VERSION "HNNBNNNYNNNNNNNNNNNNNNNNNNNNNNNNNNNNNNNNNN/4/%%%/4/'%**4NNN///"

NS_ :

BS_:

BU_: BAP_Tester Gateway_Max Getriebe_DQ Motor_konv Parksperre Schaltbetaetigung

BO_ 267 Motor_51_Auth: 48 Motor_konv
 SG_ Motor_51_CRC : 0|8@1+ (1,0) [0|255] ""  Gateway_Max
 SG_ Motor_51_BZ : 8|4@1+ (1,0) [0|15] ""  Gateway_Max
 SG_ MO_Fahrpedalrohwert_01 : 12|8@1+ (0.4,0) [0.0|101.6] "Unit_PerCent"  Gateway_Max,Getriebe_DQ
 SG_ MO_QBit_Fahrpedalwerte_01 : 20|1@1+ (1.0,0.0) [0.0|1] ""  Gateway_Max,Getriebe_DQ
 SG_ MO_Fahrpedalgradient : 21|8@1+ (25,0) [0|6350] "Unit_PerCentPerSecon"  Gateway_Max
 SG_ MO_Sig_Fahrpedalgradient : 29|1@1+ (1.0,0.0) [0.0|1] ""  Gateway_Max
 SG_ MO_rel_Saugrohrdruck : 30|6@1+ (18,0) [0|1116] "Unit_MilliBar"  Gateway_Max
 SG_ MO_rel_Saugrohrdruck_gem_err : 36|1@1+ (1.0,0.0) [0.0|1] ""  Gateway_Max
 SG_ MO_Moment_im_Leerlauf : 37|1@1+ (1.0,0.0) [0.0|1] ""  Gateway_Max,Getriebe_DQ
 SG_ MO_Schubabschaltung : 38|1@1+ (1.0,0.0) [0.0|1] ""  Gateway_Max,Getriebe_DQ
 SG_ MO_StartStopp_StoppVorbereitung : 39|1@1+ (1.0,0.0) [0.0|1] ""  Gateway_Max,Getriebe_DQ
 SG_ MO_Solldrehz_Leerlauf : 40|8@1+ (10,0) [0|2540] "Unit_MinutInver"  Gateway_Max,Getriebe_DQ
 SG_ MO_Entkopplung_Sollschlupf : 48|7@1+ (20,0) [0|2480] "Unit_MinutInver"  Gateway_Max
 SG_ MO_temporaere_Fahrerabwesenheit : 55|1@1+ (1.0,0.0) [0.0|1] ""  Gateway_Max
 SG_ TSK_a_Soll_gradientenbegrenzt : 57|7@1+ (0.1,-7.2) [-7.2|5.4] "Unit_MeterPerSeconSquar"  Gateway_Max
 SG_ TSK_Radbremsmom : 76|12@1+ (8,0) [0|32760] "Unit_NewtoMeter"  Gateway_Max,Getriebe_DQ
 SG_ TSK_Status : 88|3@1+ (1.0,0.0) [0.0|7] ""  Gateway_Max,Getriebe_DQ
 SG_ TSK_v_Begrenzung_aktiv : 91|1@1+ (1.0,0.0) [0.0|1] ""  Gateway_Max,Getriebe_DQ
 SG_ TSK_Standby_Anf_ESP : 92|1@1+ (1.0,0.0) [0.0|1] ""  Gateway_Max
 SG_ TSK_Freig_Verzoeg_Anf : 94|1@1+ (1.0,0.0) [0.0|1] ""  Gateway_Max,Getriebe_DQ
 SG_ TSK_Limiter_ausgewaehlt : 95|1@1+ (1.0,0.0) [0.0|1] ""  Gateway_Max
 SG_ TSK_Hauptschalter_GRA_ACC : 106|2@1+ (1.0,0.0) [0.0|3] ""  Gateway_Max
 SG_ TSK_SRBM_Anf_ASIL : 108|3@1+ (1.0,0.0) [0.0|7] ""  Gateway_Max
 SG_ TSK_ax_Getriebe_02 : 112|9@1+ (0.024,-2.016) [-2.016|10.224] "Unit_MeterPerSeconSquar"  Gateway_Max,Getriebe_DQ
 SG_ TSK_Zwangszusch_ESP : 121|1@1+ (1.0,0.0) [0.0|1] ""  Gateway_Max
 SG_ TSK_zul_Regelabw : 122|6@1+ (0.024,0) [0.000|1.512] "Unit_MeterPerSeconSquar"  Gateway_Max
 SG_ TSK_Radsollmoment : 128|16@1+ (0.5,-16383) [-16383.0|16383.5] "Unit_NewtoMeter"  Gateway_Max
 SG_ TSK_Kategorie_Verzoegerungsfkt : 144|2@1+ (1.0,0.0) [0.0|3] ""  Gateway_Max
 SG_ TSK_Notstopp_Anf : 233|2@1+ (1.0,0.0) [0.0|3] ""  Gateway_Max
 SG_ MO_Status_MinDrzEingriff : 235|3@1+ (1.0,0.0) [0.0|7] ""  Gateway_Max
 SG_ MO_Status_MaxDrzEingriff : 238|3@1+ (1.0,0.0) [0.0|7] ""  Gateway_Max
 SG_ MO_Status_MinDrzEingriff_sek : 241|3@1+ (1.0,0.0) [0.0|7] ""  Gateway_Max
 SG_ MO_Status_MaxDrzEingriff_sek : 244|3@1+ (1.0,0.0) [0.0|7] ""  Gateway_Max
 SG_ TSK_SRBM_max_Gradient : 248|7@1+ (50,0) [0|6250] "Unit_NewtoMeterPerSecon"  Gateway_Max
 SG_ SOK_Motor_51_Signatur : 352|32@1+ (1,0) [0|4294967295] ""  Gateway_Max

BO_ 330 Motor_52: 32 Motor_konv
 SG_ MO_Hochschaltdrehz : 21|12@1+ (3,0) [3|12282] "Unit_MinutInver"  Gateway_Max
 SG_ MO_Anzeige_Verbr_Einheit : 33|2@1+ (1.0,0.0) [0.0|3] ""  Gateway_Max
 SG_ MO_Schaltblitz_Anz : 35|7@1+ (1,0) [0|100] "Unit_PerCent"  Gateway_Max
 SG_ MO_Anzeige_Drehmoment : 42|11@1+ (1,0) [0|2045] "Unit_NewtoMeter"  Gateway_Max
 SG_ MO_Anzeige_Leistung : 53|11@1+ (0.6,0) [0.0|1227.0] "Unit_KiloWatt"  Gateway_Max
 SG_ MO_rel_Ladedruck : 64|8@1+ (0.4,0) [0.0|100.0] "Unit_PerCent"  Gateway_Max
 SG_ MO_Istgang : 72|4@1+ (1.0,0.0) [0.0|15] ""  Gateway_Max
 SG_ MO_Sollgang : 76|4@1+ (1.0,0.0) [0.0|15] ""  Gateway_Max
 SG_ MO_Oeldruck : 80|8@1+ (0.04,0) [0.00|10.00] "Unit_Bar"  Gateway_Max
 SG_ MO_Anzeigedrehz : 88|12@1+ (3,0) [0|12282] "Unit_MinutInver"  Gateway_Max
 SG_ MO_Effizienzmodus : 100|1@1+ (1.0,0.0) [0.0|1] ""  Gateway_Max,Getriebe_DQ
 SG_ MO_Fehler_Oeldrucksensor : 101|1@1+ (1.0,0.0) [0.0|1] ""  Gateway_Max
 SG_ MO_Schaltempf_verfbar : 102|1@1+ (1.0,0.0) [0.0|1] ""  Gateway_Max
 SG_ MO_Ladedruck : 103|9@1+ (0.01,0) [0.00|5.10] "Unit_Bar"  Gateway_Max
 SG_ MO_KVS : 112|15@1+ (1,0) [0|32767] "Unit_MicroLiter"  Gateway_Max
 SG_ MO_KVS_Ueberlauf : 127|1@1+ (1.0,0.0) [0.0|1] ""  Gateway_Max
 SG_ MO_ePowermeter : 128|8@1+ (0.4,-0.4) [0.0|100.8] "Unit_PerCent"  Gateway_Max
 SG_ MO_ePerformance : 136|8@1+ (0.4,-0.4) [0.0|100.8] "Unit_PerCent"  Gateway_Max
 SG_ MO_Zust_Antrieb : 144|4@1+ (1.0,0.0) [0.0|15] ""  Gateway_Max
 SG_ MO_Zust_Betriebsstrategie : 148|3@1+ (1.0,0.0) [0.0|7] ""  Gateway_Max
 SG_ Ladezustand_02 : 152|8@1+ (0.5,0) [0.0|100.0] "Unit_PerCent"  Gateway_Max
 SG_ Ladezustand_gering : 160|2@1+ (1.0,0.0) [0.0|3] ""  Gateway_Max
 SG_ Ladezustand_kritisch : 162|2@1+ (1.0,0.0) [0.0|3] ""  Gateway_Max
 SG_ MO_Powermeter_Elm_02 : 168|12@1+ (0.05,-102.4) [-100.00|100.00] "Unit_PerCent"  Gateway_Max
 SG_ MO_Powermeter : 180|12@1+ (1,0) [0|4092] ""  Gateway_Max
 SG_ MO_OnePedalDriving_Warnung : 192|2@1+ (1.0,0.0) [0.0|3] ""  Gateway_Max

BO_ 512 Motor_53: 32 Motor_konv
 SG_ TSK_Wunschgeschw : 12|10@1+ (0.32,0) [0.00|326.72] "Unit_KiloMeterPerHour"  Gateway_Max
 SG_ TSK_praediktiver_Hinweis : 22|3@1+ (1.0,0.0) [0.0|7] ""  Gateway_Max
 SG_ TSK_naechstes_Event : 25|6@1+ (1.0,0.0) [0.0|63] ""  Gateway_Max
 SG_ TSK_Fahrzeugstatus_praed_Fkt : 31|3@1+ (1.0,0.0) [0.0|7] ""  Gateway_Max
 SG_ TSK_praediktiver_Automode : 34|1@1+ (1.0,0.0) [0.0|1] ""  Gateway_Max
 SG_ CE_StStrtDlyEmiSysPrep : 35|2@1+ (1.0,0.0) [0.0|3] ""  Gateway_Max
 SG_ CE_StLdRdcEmiSysPrep : 37|3@1+ (1.0,0.0) [0.0|7] ""  Gateway_Max,Getriebe_DQ
 SG_ TSK_Texte : 40|5@1+ (1.0,0.0) [0.0|31] ""  Gateway_Max
 SG_ TSK_Akustik : 45|3@1+ (1.0,0.0) [0.0|7] ""  Gateway_Max
 SG_ TSK_Texte_Primaeranz : 48|5@1+ (1.0,0.0) [0.0|31] ""  Gateway_Max
 SG_ TSK_Limiter_Fahrerinfo : 53|2@1+ (1.0,0.0) [0.0|3] ""  Gateway_Max
 SG_ TSK_Limiter_Anzeige : 55|1@1+ (1.0,0.0) [0.0|1] ""  Gateway_Max
 SG_ TSK_Fahrzeugstatus_GRA : 56|1@1+ (1.0,0.0) [0.0|1] ""  Gateway_Max
 SG_ TSK_Fahrzeugstatus_Limiter : 57|1@1+ (1.0,0.0) [0.0|1] ""  Gateway_Max
 SG_ MO_Motorlaufwarnung : 58|1@1+ (1.0,0.0) [0.0|1] ""  Gateway_Max
 SG_ TSK_naechstes_Event_Einheit : 60|1@1+ (1.0,0.0) [0.0|1] ""  Gateway_Max
 SG_ TSK_Status_Anzeige : 61|3@1+ (1.0,0.0) [0.0|7] ""  Gateway_Max
 SG_ MO_Sperrung_FahrPr_BZS : 64|8@1+ (1.0,0.0) [0.0|255] ""  Gateway_Max
 SG_ MO_Rampenzeit_Generator_Anf : 72|4@1+ (1.0,0.0) [0.0|15] ""  Gateway_Max
 SG_ MO_Prio_MAX_Wunschdrehzahl : 76|1@1+ (1.0,0.0) [0.0|1] ""  Gateway_Max,Getriebe_DQ
 SG_ MO_Prio_MIN_Wunschdrehzahl : 77|1@1+ (1.0,0.0) [0.0|1] ""  Gateway_Max,Getriebe_DQ
 SG_ MO_Luftpfad_aktiv : 78|1@1+ (1.0,0.0) [0.0|1] ""  Gateway_Max
 SG_ MO_v_Begrenz_Aktivierbar : 79|1@1+ (1.0,0.0) [0.0|1] ""  Gateway_Max
 SG_ MO_Drehzahlbeeinflussung : 80|8@1+ (0.39,0) [0.00|99.45] "Unit_PerCent"  Gateway_Max
 SG_ MO_MIN_Wunschdrehzahl : 88|8@1+ (25,0) [0|6350] "Unit_MinutInver"  Gateway_Max,Getriebe_DQ
 SG_ MO_MAX_Wunschdrehzahl : 96|9@1+ (25,0) [0|12750] "Unit_MinutInver"  Gateway_Max,Getriebe_DQ
 SG_ MO_Charisma_FahrPr : 105|4@1+ (1.0,0.0) [0.0|15] ""  Gateway_Max
 SG_ MO_Charisma_Status : 109|2@1+ (1.0,0.0) [0.0|3] ""  Gateway_Max
 SG_ MO_StSt_Charisma_FahrPr : 111|4@1+ (1.0,0.0) [0.0|15] ""  Gateway_Max
 SG_ MO_StSt_Charisma_Status : 115|2@1+ (1.0,0.0) [0.0|3] ""  Gateway_Max
 SG_ MO_BZS_Charisma_FahrPr : 117|4@1+ (1.0,0.0) [0.0|15] ""  Gateway_Max
 SG_ MO_BZS_Charisma_Status : 121|2@1+ (1.0,0.0) [0.0|3] ""  Gateway_Max
 SG_ MO_NGS_Position : 123|1@1+ (1.0,0.0) [0.0|1] ""  Gateway_Max
 SG_ MO_NGS_Status : 124|2@1+ (1.0,0.0) [0.0|3] ""  Gateway_Max
 SG_ MO_v_Begrenzung_Niveau : 126|2@1+ (1.0,0.0) [0.0|3] ""  Gateway_Max
 SG_ MO_Anzeige_Rekuperation : 128|8@1+ (0.5,-0.5) [0.0|100.0] "Unit_PerCent"  Gateway_Max
 SG_ PEA_Fortschrittsanzeige : 136|7@1+ (1,0) [0|100] "Unit_PerCent"  Gateway_Max
 SG_ MO_Anzeige_Fahrbereitschaft : 143|1@1+ (1.0,0.0) [0.0|1] ""  Gateway_Max
 SG_ MO_Boost_verfuegbar : 144|8@1+ (0.4,-0.4) [0.0|100.4] "Unit_PerCent"  Gateway_Max
 SG_ MO_Overboost : 152|1@1+ (1.0,0.0) [0.0|1] ""  Gateway_Max
 SG_ MO_Boost_aktiv : 153|1@1+ (1.0,0.0) [0.0|1] ""  Gateway_Max
 SG_ MO_Anzeige_Betriebsmodus : 154|4@1+ (1.0,0.0) [0.0|15] ""  Gateway_Max
 SG_ PEA_Hinweis : 158|2@1+ (1.0,0.0) [0.0|3] ""  Gateway_Max
 SG_ PEA_Ereignisanzeige : 160|5@1+ (1.0,0.0) [0.0|31] ""  Gateway_Max
 SG_ PEA_Ereignisanzeige_temporaer : 165|1@1+ (1.0,0.0) [0.0|1] ""  Gateway_Max
 SG_ PEA_Abschalttexte : 166|2@1+ (1.0,0.0) [0.0|3] ""  Gateway_Max
 SG_ PEA_Zielgeschw_Einheit : 168|1@1+ (1.0,0.0) [0.0|1] ""  Gateway_Max
 SG_ PEA_Zielgeschw : 169|5@1+ (1.0,0.0) [0.0|31] ""  Gateway_Max
 SG_ MO_Antriebsstrang_Warnung_HS : 174|2@1+ (1.0,0.0) [0.0|3] ""  Gateway_Max
 SG_ MO_Anzeige_Verbrauch_oE : 176|16@1+ (0.005,0) [0.000|327.675] "Unit_None"  Gateway_Max
 SG_ MO_Text_Aktivierung_Antrieb : 192|4@1+ (1.0,0.0) [0.0|15] ""  Gateway_Max
 SG_ ISA_Tempolimit_Regelung : 196|6@1+ (1.0,0.0) [0.0|63] ""  Gateway_Max
 SG_ PEA_Fahrerinfo : 202|4@1+ (1.0,0.0) [0.0|15] ""  Gateway_Max
 SG_ CE_CtrPrpPrep : 206|3@1+ (1.0,0.0) [0.0|7] ""  Gateway_Max
 SG_ CE_PrctPrpPrep : 209|7@1+ (1,0) [0|100] "Unit_PerCent"  Gateway_Max
 SG_ MO_Kuehlmitttel_Sensor_AGB2 : 216|1@1+ (1.0,0.0) [0.0|1] ""  Gateway_Max
 SG_ CE_FlgEmiColdLmp : 217|1@1+ (1.0,0.0) [0.0|1] ""  Gateway_Max
 SG_ CE_FlgEmiColdTxt : 218|1@1+ (1.0,0.0) [0.0|1] ""  Gateway_Max
 SG_ CE_FlgHybModAdvi : 219|1@1+ (1.0,0.0) [0.0|1] ""  Gateway_Max
 SG_ CE_FlgPTLimPrfTxt : 220|1@1+ (1.0,0.0) [0.0|1] ""  Gateway_Max
 SG_ TSK_praed_Wunschgeschw : 246|10@1+ (0.32,0) [0.00|326.72] "Unit_KiloMeterPerHour"  Gateway_Max

BO_ 332 Motor_54: 32 Motor_konv
 SG_ Motor_54_CRC : 0|8@1+ (1,0) [0|255] ""  Gateway_Max
 SG_ Motor_54_BZ : 8|4@1+ (1,0) [0|15] ""  Gateway_Max
 SG_ MO_Anforderung_HMS : 12|3@1+ (1.0,0.0) [0.0|7] ""  Gateway_Max
 SG_ FoD_DTC_TSK_GRA : 15|1@1+ (1.0,0.0) [0.0|1] ""  Gateway_Max
 SG_ TSK_vMax_aktuell : 16|8@1+ (1,0) [0|253] "Unit_KiloMeterPerHour"  Gateway_Max
 SG_ ISA_Status : 24|3@1+ (1.0,0.0) [0.0|7] ""  Gateway_Max
 SG_ ISA_Regelung_aktiv : 27|1@1+ (1.0,0.0) [0.0|1] ""  Gateway_Max
 SG_ ISA_Tempolimitwarnung : 28|1@1+ (1.0,0.0) [0.0|1] ""  Gateway_Max
 SG_ MO_Red_El_Fahrleistung : 29|3@1+ (1.0,0.0) [0.0|7] ""  Gateway_Max
 SG_ TSK_Status_EA : 32|3@1+ (1.0,0.0) [0.0|7] ""  Gateway_Max
 SG_ FoD_DTC_TSK_ACC : 35|1@1+ (1.0,0.0) [0.0|1] ""  Gateway_Max
 SG_ TSK_ACC_FoD_Status : 36|2@1+ (1.0,0.0) [0.0|3] ""  Gateway_Max
 SG_ TSK_GRA_FoD_Status : 38|2@1+ (1.0,0.0) [0.0|3] ""  Gateway_Max
 SG_ TSK_vMax_Fahrerassistenz : 40|9@1+ (1,0) [0|510] ""  Gateway_Max
 SG_ TSK_Einheit_vMax_Fahrerassistenz : 49|1@1+ (1.0,0.0) [0.0|1] ""  Gateway_Max
 SG_ TSK_Status_PLA : 50|3@1+ (1.0,0.0) [0.0|7] ""  Gateway_Max
 SG_ TSK_aktives_System : 53|3@1+ (1.0,0.0) [0.0|7] ""  Gateway_Max
 SG_ TSK_erhoehter_Fahrwiderstand : 56|1@1+ (1.0,0.0) [0.0|1] ""  Gateway_Max
 SG_ TSK_Anf_Antriebsmoment : 57|1@1+ (1.0,0.0) [0.0|1] ""  Gateway_Max
 SG_ TSK_Status_ARA : 58|3@1+ (1.0,0.0) [0.0|7] ""  Gateway_Max
 SG_ TSK_Status_IPA : 61|3@1+ (1.0,0.0) [0.0|7] ""  Gateway_Max,Getriebe_DQ
 SG_ TSK_aktives_System_02 : 64|4@1+ (1.0,0.0) [0.0|15] ""  Gateway_Max,Getriebe_DQ
 SG_ TSK_Status_RHP : 68|3@1+ (1.0,0.0) [0.0|7] ""  Gateway_Max,Getriebe_DQ
 SG_ MO_Kuppl_betaetigt : 72|1@1+ (1.0,0.0) [0.0|1] ""  Gateway_Max
 SG_ MO_QBit_Kuppl_betaetigt : 73|1@1+ (1.0,0.0) [0.0|1] ""  Gateway_Max
 SG_ MO_Klima_Regelmodus : 74|2@1+ (1.0,0.0) [0.0|3] ""  Gateway_Max
 SG_ MO_Fahrbereitschaft : 76|2@1+ (1.0,0.0) [0.0|3] ""  Gateway_Max,Getriebe_DQ
 SG_ MO_Freilauf_Info : 78|2@1+ (1.0,0.0) [0.0|3] ""  Gateway_Max,Getriebe_DQ
 SG_ CE_FlgLnchCtlPreCnd : 80|1@1+ (1.0,0.0) [0.0|1] ""  Gateway_Max
 SG_ MO_Krit_Heckobjekt : 81|3@1+ (1.0,0.0) [0.0|7] ""  Gateway_Max
 SG_ MO_NGS_Gangpos : 84|3@1+ (1.0,0.0) [0.0|7] ""  Gateway_Max
 SG_ MO_Freilauf_Status : 87|3@1+ (1.0,0.0) [0.0|7] ""  Gateway_Max
 SG_ MO_EBoost_verf_praed : 90|2@1+ (1.0,0.0) [0.0|3] ""  Gateway_Max
 SG_ MO_Heckspoiler_Anf : 92|1@1+ (1.0,0.0) [0.0|1] ""  Gateway_Max
 SG_ MO_eLaunch_verf : 93|2@1+ (1.0,0.0) [0.0|3] ""  Gateway_Max
 SG_ MO_Positionierung_aktiv : 95|1@1+ (1.0,0.0) [0.0|1] ""  Gateway_Max
 SG_ MO_Veto_Launchcontrol : 96|1@1+ (1.0,0.0) [0.0|1] ""  Gateway_Max,Getriebe_DQ
 SG_ MO_Startwunsch : 100|1@1+ (1.0,0.0) [0.0|1] ""  Gateway_Max,Getriebe_DQ
 SG_ MO_LaunchControl : 101|1@1+ (1.0,0.0) [0.0|1] ""  Gateway_Max
 SG_ MO_UBE_Hybrid_Reserve : 102|10@1+ (5,0) [0|5110] "Unit_WattHour"  Gateway_Max
 SG_ OBDProtocol_req : 112|8@1+ (1.0,0.0) [0.0|255] ""  Gateway_Max,Getriebe_DQ
 SG_ OBD_Calc_Load_Val : 128|8@1+ (0.39215686274509803,0) [0E-17|99.99999999999999765] "Unit_PerCent"  Gateway_Max,Getriebe_DQ
 SG_ OBD_Eng_Cool_Temp : 136|8@1+ (1,-40) [-40|215] "Unit_DegreCelsi"  Gateway_Max,Getriebe_DQ
 SG_ OBD_Abs_Throttle_Pos : 144|8@1+ (0.39215686274509803,0) [0E-17|99.99999999999999765] "Unit_PerCent"  Gateway_Max,Getriebe_DQ
 SG_ OBD_Abs_Load_Val : 152|16@1+ (0.39215686274509803,0) [0E-17|25699.99999999999939605] "Unit_PerCent"  Gateway_Max,Getriebe_DQ
 SG_ OBD_Abs_Pedal_Pos : 168|8@1+ (0.39215686274509803,0) [0E-17|99.99999999999999765] "Unit_PerCent"  Gateway_Max,Getriebe_DQ
 SG_ MO_Servicemodus : 176|4@1+ (1.0,0.0) [0.0|15] ""  Gateway_Max,Getriebe_DQ
 SG_ OBD_ClearMem_Inhibit : 183|1@1+ (1.0,0.0) [0.0|1] ""  Gateway_Max,Getriebe_DQ
 SG_ OBD_Sperrung_Kaltstart_Denom : 184|1@1+ (1.0,0.0) [0.0|1] ""  Gateway_Max
 SG_ MO_QBit_Aussen_Temp : 185|1@1+ (1.0,0.0) [0.0|1] ""  Gateway_Max
 SG_ OBD_Sperrung_IUMPR : 186|1@1+ (1.0,0.0) [0.0|1] ""  Gateway_Max,Getriebe_DQ
 SG_ OBD_Kaltstart_Denominator : 187|1@1+ (1.0,0.0) [0.0|1] ""  Gateway_Max
 SG_ OBD_Minimum_Trip : 188|1@1+ (1.0,0.0) [0.0|1] ""  Gateway_Max,Getriebe_DQ
 SG_ OBD_Driving_Cycle : 189|1@1+ (1.0,0.0) [0.0|1] ""  Gateway_Max,Getriebe_DQ
 SG_ OBD_Warm_Up_Cycle : 190|1@1+ (1.0,0.0) [0.0|1] ""  Gateway_Max,Getriebe_DQ
 SG_ OBD_Normed_Trip : 191|1@1+ (1.0,0.0) [0.0|1] ""  Gateway_Max,Getriebe_DQ
 SG_ MO_EMG_Min_Leistung : 192|11@1+ (100,-102200) [-102200|102300] "Unit_Watt"  Gateway_Max
 SG_ MO_EMG_Max_Leistung : 203|11@1+ (100,-102200) [-102200|102300] "Unit_Watt"  Gateway_Max
 SG_ MO_MVEM_MinLeistung_MVVerbrauch : 214|10@1+ (50,-10500) [-10500|40500] "Unit_Watt"  Gateway_Max
 SG_ MO_MVEM_MaxLeistung_MVVerbrauch : 224|10@1+ (50,-10500) [-10500|40500] "Unit_Watt"  Gateway_Max
 SG_ MO_UBE_Reserve : 238|10@1+ (5,0) [0|5110] "Unit_WattHour"  Gateway_Max
 SG_ OBD_Aussen_Temp_gef : 248|8@1+ (1,-40) [-40|213] "Unit_DegreCelsi"  Gateway_Max

BO_ 553 Motor_54_SOK_Signatur: 4 Motor_konv
 SG_ SOK_Motor_54_Signatur : 0|32@1+ (1,0) [0|4294967295] ""  Gateway_Max,Getriebe_DQ

BO_ 246 Motor_55_Auth: 48 Motor_konv
 SG_ Motor_55_CRC : 0|8@1+ (1,0) [0|255] ""  Gateway_Max
 SG_ Motor_55_BZ : 8|4@1+ (1,0) [0|15] ""  Gateway_Max
 SG_ TS_Faktor_Radmomente : 12|2@1+ (1.0,0.0) [0.0|3] ""  Gateway_Max,Getriebe_DQ
 SG_ TS_Status_MomRad_Ist : 14|2@1+ (1.0,0.0) [0.0|3] ""  Gateway_Max
 SG_ TS_MomRad_verfuegb_maxReku_Summe : 16|12@1+ (3,-12279) [-12279|0] ""  Gateway_Max
 SG_ TS_MomRad_Ist : 28|13@1+ (3,-12279) [-12279|12279] "Unit_None"  Gateway_Max
 SG_ TS_MomRad_Soll_Summe : 41|13@1+ (3,-12279) [-12279|12279] "Unit_None"  Gateway_Max,Getriebe_DQ
 SG_ TS_MomRad_Wunsch : 54|13@1+ (3,-12279) [-12279|12279] "Unit_None"  Gateway_Max
 SG_ TS_MomRad_Wunsch_sek : 67|13@1+ (3,-12279) [-12279|12279] "Unit_None"  Gateway_Max
 SG_ TS_MomRad_verfuegb_max : 80|12@1+ (3,0) [0|12279] "Unit_None"  Gateway_Max
 SG_ TS_MomRad_verfuegb_max_sek : 92|12@1+ (3,0) [0|12279] "Unit_None"  Gateway_Max
 SG_ TS_MomRad_verfuegb_maxReku : 104|12@1+ (3,-12279) [-12279|0] "Unit_None"  Gateway_Max
 SG_ TS_MomRad_verfuegb_maxReku_sek : 116|12@1+ (3,-12279) [-12279|0] "Unit_None"  Gateway_Max
 SG_ TS_MomRad_Ist_sek : 128|13@1+ (3,-12279) [-12279|12279] "Unit_None"  Gateway_Max
 SG_ TS_Allrad_Anteil_sek : 141|9@1+ (0.2,0) [0.0|100.0] "Unit_PerCent"  Gateway_Max,Getriebe_DQ
 SG_ FDR_Allrad_Anteil_max_sek : 150|9@1+ (0.2,0) [0.0|100.0] "Unit_PerCent"  Gateway_Max
 SG_ FDR_Allrad_Anteil_min_sek : 159|9@1+ (0.2,0) [0.0|100.0] "Unit_PerCent"  Gateway_Max
 SG_ FDR_MomRad_Eingriff : 168|13@1+ (3,-12279) [-12279|12279] "Unit_NewtoMeter"  Gateway_Max
 SG_ FDR_Status_Eingriff : 181|1@1+ (1.0,0.0) [0.0|1] ""  Gateway_Max
 SG_ FDR_MomRad_Eingriff_sek : 182|13@1+ (3,-12279) [-12279|12279] "Unit_NewtoMeter"  Gateway_Max
 SG_ FDR_Status_Eingriff_sek : 195|1@1+ (1.0,0.0) [0.0|1] ""  Gateway_Max
 SG_ MO_Mom_Begr_Fahr_Pred : 196|9@1+ (1,0) [0|509] ""  Gateway_Max,Getriebe_DQ
 SG_ FDR_Zwangszusch_ESP : 205|1@1+ (1.0,0.0) [0.0|1] ""  Gateway_Max
 SG_ MO_EMG_Sollmodus : 206|4@1+ (1.0,0.0) [0.0|15] ""  Gateway_Max
 SG_ TS_Status_DrzReg : 210|2@1+ (1.0,0.0) [0.0|3] ""  Gateway_Max
 SG_ TS_Status_DrzReg_sek : 212|2@1+ (1.0,0.0) [0.0|3] ""  Gateway_Max
 SG_ MO_EMG_SollDrehzahl : 257|15@1+ (1,-10000) [-10000|22766] "Unit_MinutInver"  Gateway_Max
 SG_ MO_EMG_Max_Momentengradient : 272|7@1+ (1,0) [0|124] "Unit_NewtoMeterPerSecon"  Gateway_Max
 SG_ MO_EMG_Generator_Leistung : 279|11@1+ (20,-20440) [-20440|20460] "Unit_Watt"  Gateway_Max
 SG_ MO_EMG_Max_Strom_Lim : 290|11@1+ (1,-1023) [-1023|1022] "Unit_Amper"  Gateway_Max
 SG_ MO_EMG_Min_Strom_Lim : 301|11@1+ (1,-1023) [-1023|1022] "Unit_Amper"  Gateway_Max
 SG_ MO_EMG_Max_Spannung_Lim : 312|8@1+ (0.25,0) [0.00|63.25] "Unit_Volt"  Gateway_Max
 SG_ MO_EMG_Min_Spannung_Lim : 320|8@1+ (0.25,0) [0.00|63.25] "Unit_Volt"  Gateway_Max
 SG_ MO_EMG_SollMoment_02 : 328|16@1+ (0.01,-327.68) [-327.68|327.65] "Unit_NewtoMeter"  Gateway_Max
 SG_ MO_EMG_Sollspannung : 344|8@1+ (0.25,0) [0.00|63.25] "Unit_Volt"  Gateway_Max
 SG_ SOK_Motor_55_Signatur : 352|32@1+ (1,0) [0|4294967295] ""  Gateway_Max

BO_ 190 Motor_56: 48 Vector__XXX
 SG_ Motor_56_CRC : 0|8@1+ (1,0) [0|255] ""  Gateway_Max
 SG_ Motor_56_BZ : 8|4@1+ (1,0) [0|15] ""  Gateway_Max
 SG_ MO_EM1_MinDrehzahl : 12|14@1+ (2,-10000) [-10000|22764] "Unit_MinutInver"  Gateway_Max
 SG_ MO_EM1_MaxDrehzahl : 26|14@1+ (2,-10000) [-10000|22764] "Unit_MinutInver"  Gateway_Max
 SG_ MO_EM1_DynLimit_AR : 40|8@1+ (1,0) [0|254] "Unit_NewtoMeter"  Gateway_Max
 SG_ MO_EM1_Periode_AR : 48|8@1+ (0.001953125,0) [0E-9|0.496093750] "Unit_Secon"  Gateway_Max
 SG_ MO_EM1_SollMoment : 56|12@1+ (0.5,-1023) [-1023.0|1023.5] "Unit_NewtoMeter"  Gateway_Max
 SG_ MO_EM1_Sollmodus : 68|4@1+ (1.0,0.0) [0.0|15] ""  Gateway_Max
 SG_ MO_EM1_Min_Leistung : 72|14@1+ (100,-819000) [-819000|819100] "Unit_Watt"  Gateway_Max
 SG_ MO_EM1_Max_Leistung : 86|14@1+ (100,-819000) [-819000|819100] "Unit_Watt"  Gateway_Max
 SG_ MO_EM1_Min_Strom_Lim : 100|13@1+ (0.5,-2047) [-2047.0|2047.5] "Unit_Amper"  Gateway_Max
 SG_ MO_EM1_Max_Strom_Lim : 113|13@1+ (0.5,-2047) [-2047.0|2047.5] "Unit_Amper"  Gateway_Max
 SG_ MO_EM1_AR_Anf : 126|3@1+ (1.0,0.0) [0.0|7] ""  Gateway_Max
 SG_ MO_EM1_Kp_AR : 129|9@1+ (0.00390625,0) [0E-8|1.99218750] "Unit_NewtoMeterPerRPM"  Gateway_Max
 SG_ MO_EM1_SollSpannung : 138|12@1+ (0.5,0) [0.0|2047.0] "Unit_Volt"  Gateway_Max
 SG_ MO_CluEng_Set : 150|2@1+ (1.0,0.0) [0.0|3] ""  Gateway_Max
 SG_ MO_EM2_MinDrehzahl : 156|14@1+ (2,-10000) [-10000|22764] "Unit_MinutInver"  Gateway_Max
 SG_ MO_EM2_MaxDrehzahl : 170|14@1+ (2,-10000) [-10000|22764] "Unit_MinutInver"  Gateway_Max
 SG_ MO_EM2_DynLimit_AR : 184|8@1+ (1,0) [0|254] "Unit_NewtoMeter"  Gateway_Max
 SG_ MO_EM2_Periode_AR : 192|8@1+ (0.001953125,0) [0E-9|0.496093750] "Unit_Secon"  Gateway_Max
 SG_ MO_EM2_SollMoment : 200|12@1+ (0.5,-1023) [-1023.0|1023.5] "Unit_NewtoMeter"  Gateway_Max
 SG_ MO_EM2_Sollmodus : 212|4@1+ (1.0,0.0) [0.0|15] ""  Gateway_Max
 SG_ MO_EM2_Min_Leistung : 216|14@1+ (100,-819000) [-819000|819100] "Unit_Watt"  Gateway_Max
 SG_ MO_EM2_Max_Leistung : 230|14@1+ (100,-819000) [-819000|819100] "Unit_Watt"  Gateway_Max
 SG_ MO_EM2_Min_Strom_Lim : 244|13@1+ (0.5,-2047) [-2047.0|2047.5] "Unit_Amper"  Gateway_Max
 SG_ MO_EM2_Max_Strom_Lim : 257|13@1+ (0.5,-2047) [-2047.0|2047.5] "Unit_Amper"  Gateway_Max
 SG_ MO_EM2_AR_Anf : 270|3@1+ (1.0,0.0) [0.0|7] ""  Gateway_Max
 SG_ MO_EM2_Kp_AR : 273|9@1+ (0.00390625,0) [0E-8|1.99218750] "Unit_NewtoMeterPerRPM"  Gateway_Max
 SG_ MO_EM2_SollSpannung : 282|12@1+ (0.5,0) [0.0|2047.0] "Unit_Volt"  Gateway_Max
 SG_ MO_CluAxs_Set : 294|2@1+ (1.0,0.0) [0.0|3] ""  Gateway_Max
 SG_ MO_DC_Max_Strom_HV : 296|8@1+ (0.2,0) [0.0|50.8] "Unit_Amper"  Gateway_Max
 SG_ MO_DC_SollSpannung_HV : 304|8@1+ (2,0) [0|508] "Unit_Volt"  Gateway_Max
 SG_ MO_EM1_Max_Moment : 312|12@1+ (0.5,-1023) [-1023.0|1023.5] "Unit_NewtoMeter"  Gateway_Max
 SG_ MO_EM1_Min_Moment : 324|12@1+ (0.5,-1023) [-1023.0|1023.5] "Unit_NewtoMeter"  Gateway_Max
 SG_ MO_EM2_Max_Moment : 336|12@1+ (0.5,-1023) [-1023.0|1023.5] "Unit_NewtoMeter"  Gateway_Max
 SG_ MO_EM2_Min_Moment : 348|12@1+ (0.5,-1023) [-1023.0|1023.5] "Unit_NewtoMeter"  Gateway_Max
 SG_ SOK_MO_SollMoment_Signatur : 360|24@1+ (1,0) [0|16777215] "Unit_None"  Gateway_Max

BO_ 2463978666 Motor_57: 32 Vector__XXX
 SG_ Motor_57_CRC : 0|8@1+ (1,0) [0|255] ""  Gateway_Max
 SG_ Motor_57_BZ : 8|4@1+ (1,0) [0|15] ""  Gateway_Max
 SG_ MO_EM1_Min_Spannung_Lim : 12|10@1+ (1,0) [0|1021] "Unit_Volt"  Gateway_Max
 SG_ MO_EM1_Max_Spannung_Lim : 22|10@1+ (1,0) [0|1021] "Unit_Volt"  Gateway_Max
 SG_ MO_EM1_Min_Leistung_Gesamt : 32|13@1+ (200,-819000) [-819000|818800] "Unit_Watt"  Gateway_Max
 SG_ MO_EM1_Max_Leistung_Gesamt : 45|13@1+ (200,-819000) [-819000|818800] "Unit_Watt"  Gateway_Max
 SG_ MO_EM2_Min_Leistung_Gesamt : 58|13@1+ (200,-819000) [-819000|818800] "Unit_Watt"  Gateway_Max
 SG_ MO_EM2_Max_Leistung_Gesamt : 71|13@1+ (200,-819000) [-819000|818800] "Unit_Watt"  Gateway_Max
 SG_ MO_EM2_Min_Spannung_Lim : 84|10@1+ (1,0) [0|1021] "Unit_Volt"  Gateway_Max
 SG_ MO_EM2_Max_Spannung_Lim : 94|10@1+ (1,0) [0|1021] "Unit_Volt"  Gateway_Max
 SG_ MO_EM1_Generator_Leistung : 104|8@1+ (100,0) [0|25300] "Unit_Watt"  Gateway_Max
 SG_ MO_EM2_Generator_Leistung : 112|8@1+ (100,0) [0|25300] "Unit_Watt"  Gateway_Max
 SG_ MO_Verbrauch_EM_Ges : 120|15@1+ (10,0) [0|327670] "Unit_WattSecond"  Gateway_Max
 SG_ MO_Verbrauch_EM_Ges_Ueberlauf : 135|1@1+ (1.0,0.0) [0.0|1] ""  Gateway_Max
 SG_ MO_Rekuperation_Ges_EM : 136|15@1+ (10,0) [0|327670] "Unit_WattSecond"  Gateway_Max
 SG_ MO_Rekuperation_EM_Ges_Ueberlauf : 151|1@1+ (1.0,0.0) [0.0|1] ""  Gateway_Max
 SG_ MO_Drehzahl_EM : 152|13@1+ (8,-32768) [-32768|32744] "Unit_RevPerMinute"  Gateway_Max
 SG_ MO_Uebersetzung_EM : 165|10@1+ (0.03125,0) [0.03125|31.90625] ""  Gateway_Max
 SG_ MO_Drehzahl_EM_sek : 175|13@1+ (8,-32768) [-32768|32744] "Unit_RevPerMinute"  Gateway_Max
 SG_ MO_Uebersetzung_EM_sek : 188|10@1+ (0.03125,0) [0.03125|31.90625] ""  Gateway_Max
 SG_ MO_TNW_Min_Spannung_Lim : 198|10@1+ (1,0) [0|1021] "Unit_Volt"  Gateway_Max
 SG_ MO_TNW_Max_Spannung_Lim : 208|10@1+ (1,0) [0|1021] "Unit_Volt"  Gateway_Max

BO_ 2331595982 Motor_64: 32 Vector__XXX
 SG_ PTUIPwrm_PrctPwrSysCur : 12|12@1+ (0.05,-102.3) [-102.30|102.35] "Unit_PerCent"  Gateway_Max
 SG_ PTUIPwrm_PrctPwrElDrvCur : 24|12@1+ (0.05,-102.3) [-102.30|102.35] "Unit_PerCent"  Gateway_Max
 SG_ PTHyDrA_StAcv : 36|2@1+ (1.0,0.0) [0.0|3] ""  Gateway_Max
 SG_ PTUIPwrm_StAcv : 38|2@1+ (1.0,0.0) [0.0|3] ""  Gateway_Max
 SG_ PTHyDrA_PrctUtilElDrv : 40|11@1+ (0.05,0) [0.00|102.25] "Unit_PerCent"  Gateway_Max
 SG_ PTUIPwrm_PrctPwrGnrMaxUse : 51|11@1+ (0.05,-102.25) [-102.25|0.00] "Unit_PerCent"  Gateway_Max
 SG_ PTUIPwrm_PrctPwrMotElMaxUse : 62|11@1+ (0.05,0) [0.00|102.25] "Unit_PerCent"  Gateway_Max
 SG_ PTUIPwrm_FacPwrDyn : 73|7@1+ (0.01,0) [0.00|1.25] "Unit_None"  Gateway_Max
 SG_ PTUIPwrm_PrctPwrMotMaxUse : 80|11@1+ (0.05,0) [0.00|102.25] "Unit_PerCent"  Gateway_Max
 SG_ PTUIPwrm_PrctBoostAvl : 91|10@1+ (0.1,0) [0.0|102.1] "Unit_PerCent"  Gateway_Max
 SG_ PTUIPwrm_PrctPwrElBoostCur : 101|10@1+ (0.1,0) [0.0|102.1] "Unit_PerCent"  Gateway_Max
 SG_ PTUIPwrm_PrctPwrElBoostMaxUse : 111|10@1+ (0.1,0) [0.0|102.1] "Unit_PerCent"  Gateway_Max
 SG_ PTUIPwrm_PwrElBoostNom : 121|10@1+ (1,0) [0|1021] "Unit_KiloWatt"  Gateway_Max
 SG_ PTUIPwrm_PrctPwrEcoMaxUse : 142|11@1+ (0.05,0) [0.00|102.25] "Unit_PerCent"  Gateway_Max
 SG_ PTUIPwrm_PrctPwrSysMaxUseTemp : 153|11@1+ (0.05,0) [0.00|102.25] "Unit_PerCent"  Gateway_Max

BO_ 2589283946 Motor_65: 32 Vector__XXX
 SG_ PTUIPwrm_PwrMotElNom : 12|11@1+ (1,0) [0|2045] "Unit_KiloWatt"  Gateway_Max
 SG_ PTUIPwrm_PwrGnrNom : 24|11@1+ (1,0) [0|2045] "Unit_KiloWatt"  Gateway_Max
 SG_ PTUIPwrm_PwrSysMotNomDisp : 35|11@1+ (1,0) [0|2045] "Unit_KiloWatt"  Gateway_Max

BO_ 2589284069 Motor_66: 32 Motor_konv
 SG_ MO_Beladungsstufe_OPF : 12|3@1+ (1.0,0.0) [0.0|7] ""  Gateway_Max
 SG_ MO_Sensorbeladung_OPF : 16|8@1+ (0.4,0) [0.0|100.0] "Unit_PerCent"  Gateway_Max
 SG_ MO_Modellbeladung_OPF : 24|8@1+ (0.4,0) [0.0|100.0] "Unit_PerCent"  Gateway_Max
 SG_ MO_Aschebeladung_OPF : 32|8@1+ (0.4,0) [0.0|100.0] "Unit_PerCent"  Gateway_Max
 SG_ MO_Offset_Nockenwelle1 : 40|8@1+ (0.03137255,-4) [-4.00000000|4.00000025] "Unit_None"  Gateway_Max
 SG_ MO_Offset_Nockenwelle2 : 48|8@1+ (0.03137255,-4) [-4.00000000|4.00000025] "Unit_None"  Gateway_Max

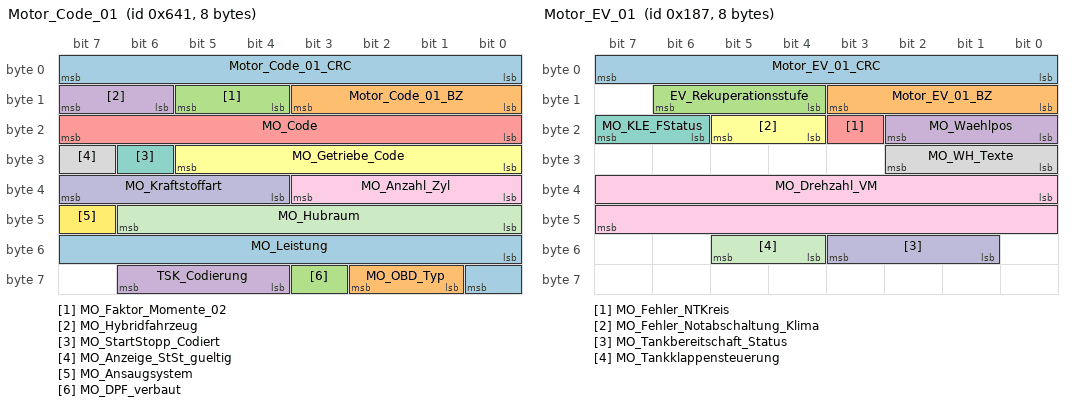
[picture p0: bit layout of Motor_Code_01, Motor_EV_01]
BO_ 1601 Motor_Code_01: 8 Motor_konv
 SG_ Motor_Code_01_CRC : 0|8@1+ (1,0) [0|255] ""  Gateway_Max,Getriebe_DQ
 SG_ Motor_Code_01_BZ : 8|4@1+ (1,0) [0|15] ""  Gateway_Max,Getriebe_DQ
 SG_ MO_Faktor_Momente_02 : 12|2@1+ (1,0) [1|3] "Unit_NewtoMeter"  Gateway_Max,Getriebe_DQ
 SG_ MO_Hybridfahrzeug : 14|2@1+ (1.0,0.0) [0.0|3] ""  Gateway_Max
 SG_ MO_Code : 16|8@1+ (1,0) [0|255] ""  Gateway_Max
 SG_ MO_Getriebe_Code : 24|6@1+ (1.0,0.0) [0.0|63] ""  Gateway_Max
 SG_ MO_StartStopp_Codiert : 30|1@1+ (1.0,0.0) [0.0|1] ""  Gateway_Max
 SG_ MO_Anzeige_StSt_gueltig : 31|1@1+ (1.0,0.0) [0.0|1] ""  Gateway_Max
 SG_ MO_Anzahl_Zyl : 32|4@1+ (1.0,0.0) [0.0|15] ""  Gateway_Max
 SG_ MO_Kraftstoffart : 36|4@1+ (1.0,0.0) [0.0|15] ""  Gateway_Max,Getriebe_DQ
 SG_ MO_Hubraum : 40|7@1+ (0.1,0) [0.0|12.7] "Unit_Liter"  Gateway_Max
 SG_ MO_Ansaugsystem : 47|1@1+ (1.0,0.0) [0.0|1] ""  Gateway_Max
 SG_ MO_Leistung : 48|9@1+ (1,0) [0|511] "Unit_KiloWatt"  Gateway_Max
 SG_ MO_OBD_Typ : 57|2@1+ (1.0,0.0) [0.0|3] ""  Gateway_Max
 SG_ MO_DPF_verbaut : 59|1@1+ (1.0,0.0) [0.0|1] ""  Gateway_Max
 SG_ TSK_Codierung : 60|3@1+ (1.0,0.0) [0.0|7] ""  Gateway_Max

BO_ 391 Motor_EV_01: 8 Motor_konv
 SG_ Motor_EV_01_CRC : 0|8@1+ (1,0) [0|255] ""  Gateway_Max
 SG_ Motor_EV_01_BZ : 8|4@1+ (1,0) [0|15] ""  Gateway_Max
 SG_ EV_Rekuperationsstufe : 12|3@1+ (1.0,0.0) [0.0|7] ""  Gateway_Max
 SG_ MO_Waehlpos : 16|3@1+ (1.0,0.0) [0.0|7] ""  Gateway_Max
 SG_ MO_Fehler_NTKreis : 19|1@1+ (1.0,0.0) [0.0|1] ""  Gateway_Max
 SG_ MO_Fehler_Notabschaltung_Klima : 20|2@1+ (1.0,0.0) [0.0|3] ""  Gateway_Max
 SG_ MO_KLE_FStatus : 22|2@1+ (1.0,0.0) [0.0|3] ""  Gateway_Max
 SG_ MO_WH_Texte : 24|3@1+ (1.0,0.0) [0.0|7] ""  Gateway_Max
 SG_ MO_Drehzahl_VM : 32|16@1+ (0.25,0) [0.00|16383.00] "Unit_MinutInver"  Gateway_Max
 SG_ MO_Tankbereitschaft_Status : 49|3@1+ (1.0,0.0) [0.0|7] ""  Gateway_Max
 SG_ MO_Tankklappensteuerung : 52|2@1+ (1.0,0.0) [0.0|3] ""  Gateway_Max

BO_ 813 Motor_Gas_01: 8 Motor_konv
 SG_ MO_Fuellstand_LPG m1  : 0|10@1+ (0.125,0) [0.000|127.625] "Unit_Liter"  Gateway_Max
 SG_ MO_CNG_LPG M  : 12|1@1+ (1.0,0.0) [0.0|1] ""  Gateway_Max
 SG_ MO_CNG_Tankstopp m0  : 15|1@1+ (1.0,0.0) [0.0|1] ""  Gateway_Max
 SG_ MO_LPG_Tankstopp m1  : 15|1@1+ (1.0,0.0) [0.0|1] ""  Gateway_Max
 SG_ MO_AnzeigeGasbetrieb : 16|4@1+ (1.0,0.0) [0.0|15] ""  Gateway_Max
 SG_ MO_akt_Betrieb : 20|1@1+ (1.0,0.0) [0.0|1] ""  Gateway_Max
 SG_ MO_Erdgasqualitaet : 21|3@1+ (1.0,0.0) [0.0|7] ""  Gateway_Max
 SG_ MO_Verbrauchsaequivalent : 24|8@1+ (0.008,0) [0.008|2.000] "Unit_None"  Gateway_Max
 SG_ MO_Tankmasse_CNG m0  : 32|8@1+ (0.25,0) [0.25|63.50] "Unit_KiloGram"  Gateway_Max
 SG_ MO_Tankvolumen_LPG m1  : 32|8@1+ (0.5,0) [0.5|127.0] "Unit_Liter"  Gateway_Max
 SG_ MO_Fuellungsgrad_CNG m0  : 40|8@1+ (0.4,0) [0.0|101.2] "Unit_PerCent"  Gateway_Max
 SG_ MO_Fuellungsgrad_LPG m1  : 40|8@1+ (0.4,0) [0.0|101.2] "Unit_PerCent"  Gateway_Max
 SG_ MO_CNG_Ueberlauf m0  : 48|1@1+ (1.0,0.0) [0.0|1] ""  Gateway_Max
 SG_ MO_LPG_Ueberlauf m1  : 48|1@1+ (1.0,0.0) [0.0|1] ""  Gateway_Max
 SG_ MO_Verbrauch_CNG m0  : 49|15@1+ (1,0) [0|32767] "Unit_MilliGram"  Gateway_Max
 SG_ MO_Verbrauch_LPG m1  : 49|15@1+ (1,0) [0|32767] "Unit_MicroLiter"  Gateway_Max

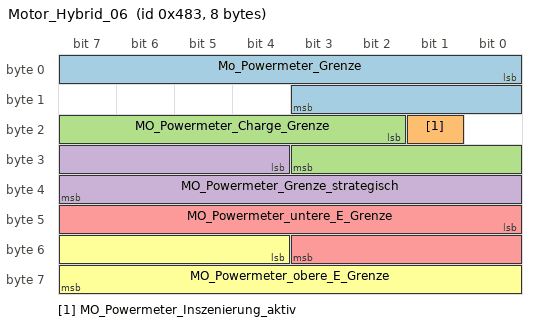
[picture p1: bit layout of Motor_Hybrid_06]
BO_ 1155 Motor_Hybrid_06: 8 Vector__XXX
 SG_ Mo_Powermeter_Grenze : 0|12@1+ (1,0) [0|4092] ""  Gateway_Max
 SG_ MO_Powermeter_Inszenierung_aktiv : 17|1@1+ (1.0,0.0) [0.0|1] ""  Gateway_Max
 SG_ MO_Powermeter_Charge_Grenze : 18|10@1+ (1,0) [0|1021] "Unit_None"  Gateway_Max
 SG_ MO_Powermeter_Grenze_strategisch : 28|12@1+ (1,0) [0|4093] "Unit_None"  Gateway_Max
 SG_ MO_Powermeter_untere_E_Grenze : 40|12@1+ (1,0) [0|4093] "Unit_None"  Gateway_Max
 SG_ MO_Powermeter_obere_E_Grenze : 52|12@1+ (1,0) [0|4093] "Unit_None"  Gateway_Max

BO_ 2589284112 Motor_VTD_01: 8 Vector__XXX
 SG_ MO_VTD_TD_L : 0|32@1+ (0.1,0) [0.0|429496729.3] "Unit_KiloMeter"  Gateway_Max
 SG_ MO_VTD_CDEODT_L : 32|32@1+ (0.1,0) [0.0|429496729.3] "Unit_KiloMeter"  Gateway_Max

BO_ 2589284113 Motor_VTD_01_SOK_Signatur: 8 Vector__XXX
 SG_ SOK_Motor_VTD_01_Signatur : 0|64@1+ (1,0) [0|18446744073709551615] ""  Gateway_Max

BO_ 2589284114 Motor_VTD_02: 8 Vector__XXX
 SG_ MO_VTD_CDFC_L : 0|32@1+ (0.01,0) [0.00|42949672.93] "Unit_Liter"  Gateway_Max
 SG_ MO_VTD_CDERDT_L : 32|32@1+ (0.1,0) [0.0|429496729.3] "Unit_KiloMeter"  Gateway_Max

BO_ 2589284115 Motor_VTD_02_SOK_Signatur: 8 Vector__XXX
 SG_ SOK_Motor_VTD_02_Signatur : 0|64@1+ (1,0) [0|18446744073709551615] ""  Gateway_Max

BO_ 2589284116 Motor_VTD_03: 8 Vector__XXX
 SG_ MO_VTD_CIDT_L : 0|32@1+ (0.1,0) [0.0|429496729.3] "Unit_KiloMeter"  Gateway_Max
 SG_ MO_VTD_GE_L : 32|32@1+ (0.1,0) [0.0|429496729.3] "Unit_KiloWattHour"  Gateway_Max

BO_ 2589284117 Motor_VTD_03_SOK_Signatur: 8 Vector__XXX
 SG_ SOK_Motor_VTD_03_Signatur : 0|64@1+ (1,0) [0|18446744073709551615] ""  Gateway_Max

BO_ 2589284118 Motor_VTD_04: 8 Vector__XXX
 SG_ MO_VTD_CIFC_L : 0|32@1+ (0.01,0) [0.00|42949672.93] "Unit_Liter"  Gateway_Max
 SG_ MO_VTD_FC_L : 32|32@1+ (0.01,0) [0.00|42949672.93] "Unit_Liter"  Gateway_Max

BO_ 2589284119 Motor_VTD_04_SOK_Signatur: 8 Vector__XXX
 SG_ SOK_Motor_VTD_04_Signatur : 0|64@1+ (1,0) [0|18446744073709551615] ""  Gateway_Max

BO_ 16 MSG1_WFS_Anfrage: 8 Motor_konv
 SG_ WFS_MSG1_RND : 0|32@1+ (1.0,0.0) [0.0|4294967295] ""  Gateway_Max
 SG_ WFS_MSG1_CRC : 32|32@1+ (1.0,0.0) [0.0|4294967295] ""  Gateway_Max

BO_ 22 MSG3_WFS_Anfrage: 8 Vector__XXX
 SG_ WFS_MSG3_RND : 0|32@1+ (1.0,0.0) [0.0|4294967295] ""  Gateway_Max
 SG_ WFS_MSG3_CRC : 32|32@1+ (1.0,0.0) [0.0|4294967295] ""  Gateway_Max

BO_ 24 MSG4_WFS_Anfrage: 8 Vector__XXX
 SG_ WFS_MSG4_RND : 0|32@1+ (1.0,0.0) [0.0|4294967295] ""  Gateway_Max
 SG_ WFS_MSG4_CRC : 32|32@1+ (1.0,0.0) [0.0|4294967295] ""  Gateway_Max

CM_ BO_ 1601 "ab MQB mit CRC-8";
CM_ BO_ 813 "Gesendet nur bei CNG/LPG-Motorprojekten";

CM_ SG_ 267 MO_Entkopplung_Sollschlupf "MSG fordert von GSG an, das Anfahrelement (Fahr-/Wandlerkupplung) zu entkoppeln; das GSG soll die gesendete Drehzahl als Schlupf einstellen und ggf. die Regler-Parameter umschalten, damit Rucke aus dem Antrieb nicht im Fahrzeug spürbar werden; nutzbar z.B";
CM_ SG_ 267 MO_Fahrpedalgradient "Das Motorsteuergerät besitzt 2 analoge Fahrpedalsignale. Das Signal des ersten Kanals wird alle 4ms abgetastet. Um Bitschwankungen des A/D-Wandler herauszufiltern wird das Signal entjittert. Anschließend wird der Gradient berechnet. Entsprechend der Zyklu";
CM_ SG_ 267 MO_Fahrpedalrohwert_01 "AUDI D4: Zykluszeit: 10ms (siehe Zykluszeit schnell/Cycletime Fast)

Stellung des Fahrpedales (Rohwert, ohne Überlagerung durch GRA-Eingriffe etc.)

Die Funktionen zur Berechung des Fahrpedalrohwerts laufen im 10ms Raster. Der Fahrpedalwert berechnet ";
CM_ SG_ 267 MO_Moment_im_Leerlauf "Fahrerwunschmoment ist minimal: keine Momentenanforderung durch Fahrpedal, ACC oder GRA+; (Das Signal ist unabhängig von Momentenerhöhungen durch Leerlaufregler oder MSR).

AUDI D4: Zykluszeit: 10ms (siehe Zykluszeit schnell/Cycletime Fast)

Achtung:";
CM_ SG_ 267 MO_QBit_Fahrpedalwerte_01 "AUDI D4: Zykluszeit: 10ms (siehe Zykluszeit schnell/Cycletime Fast)

QBit für beide Fahrpedalwerte des Motors (Fahrpedalrohsignal für ESP, EPB, ACC; Fahrpedalwert für Getriebe)

Achtung:
Reduktion der Zykluszeit Motor_03 auf 10ms geplant.
Projektabh";
CM_ SG_ 267 MO_rel_Saugrohrdruck "Der Wert gibt an, um wieviel mbar der Saugrohrdruck unterhalb des Umgebungsdrucks liegt. Überdruck im Saugrohr wird nicht ausgegeben.
0: Saugrohrdruck=Umgebungsdruck";
CM_ SG_ 267 MO_rel_Saugrohrdruck_gem_err "0: mind. eine Modellrechnung wird zur Berechnung des relativen Saugdrucks herangezogen
1: Relativer Saugrohrdruck wird ausschließlich über Messgrößen bestimmt";
CM_ SG_ 267 MO_Schubabschaltung "ESP plausibilisiert Unterdrucksensor nur bei aktiver Schubabschaltung

MLBevo:
Signal wird nur in MLBevo Projekten mit PDKII Getriebe bedient. In allen anderen MLBevo Projekten wird das Signal mit '0' bedient
PDKII berücksichtigt Verzugszeiten, die in";
CM_ SG_ 267 MO_Sig_Fahrpedalgradient "Kennzeichnet das Vorzeichen des Signal 'Fahrpedalgradient'. Die Ausgabe erfolgt nur parallel statisch mit gesendetem Signal: 'Steuerungsbit Fahrpedalgradient' ";
CM_ SG_ 267 MO_Solldrehz_Leerlauf "Leerlaufsolldrehzahl, die im Motor eingestellt ist (Bei Parallelhybrid im E-Fahr-Betrieb Leerlaufsolldrehzahl der E-Maschine). Der Motor paßt aufgrund der Anforderung von anderen Steuergeräten seine Leerlaufsolldrehzahl an, bspw. Kat-Heizen, Anforderung v";
CM_ SG_ 267 MO_StartStopp_StoppVorbereitung "Zeigt allen aktiven Start-/Stoppteilnehmern einen möglichen Motorstopp im Anhaltevorgang an (Empfänger notwendige Vorbereitungen treffen)
Es liegen keine Vetos vor.";
CM_ SG_ 267 MO_Status_MaxDrzEingriff "Aktuell drehzahlführender Anforderer der Maximaldrehzahl (Begrenzungsregelung) des Pulswechselrichters der Primärachse.";
CM_ SG_ 267 MO_Status_MaxDrzEingriff_sek "Aktuell drehzahlführender Anforderer der Maximaldrehzahl (Begrenzungsregelung) des Pulswechselrichters der Sekundärachse.";
CM_ SG_ 267 MO_Status_MinDrzEingriff "Aktuell drehzahlführender Anforderer der Minimaldrehzahl (Begrenzungsregelung) des Pulswechselrichters der Primärachse.";
CM_ SG_ 267 MO_Status_MinDrzEingriff_sek "Aktuell drehzahlführender Anforderer der Minimaldrehzahl (Begrenzungsregelung) des Pulswechselrichters der Sekundärachse.";
CM_ SG_ 267 MO_temporaere_Fahrerabwesenheit "Das Signal dient zur Signalisierung einer temporären Abwesenheit des Fahrers. In dieser Zeit ist es ihm möglich, sich durch gewisse ¿ im Verlassenskonzept definierte ¿ Fahreraktionen im aktuellen Fahrzyklus zurückzumelden.
Das Signal wird gesetzt, sobald";
CM_ SG_ 267 Motor_51_BZ "4bit Botschaftszähler, wird mit jeder Sendebotschaft inkrementiert";
CM_ SG_ 267 Motor_51_CRC "Für MLB:
Berechnung siehe Lastenheft 'Kommunikationsabsicherung für FlexRay und CAN'
Ab MQB und MLBevo:
Berechnung siehe Lastenheft 'End-to-End Kommunikationsabsicherung'

Endwerte siehe Begleitdokument 'S-PDU Kennungsfolgen'";
CM_ SG_ 267 SOK_Motor_51_Signatur "Signatur im Rahmen der durch SOK geschützten Broadcast-Kommunikation

Geschützte Funktion: Bremsfunktion HDC und Airbag-Funktionen 
Geschützte Botschaft: Motor_51";
CM_ SG_ 267 TSK_a_Soll_gradientenbegrenzt "TSK Sollbeschleunigung für Fahrerassistenzsysteme mit aktiver Längsführung (GRA, ACC, IPA...). Der Wert stellt den ruckbegrenzten Sollwert der TSK-Regelung dar und ist Basis der TSK-Antriebs- und Bremsmomentenvorsteuerung.";
CM_ SG_ 267 TSK_ax_Getriebe_02 "Beschleunigungsanforderung des Beschleunigungsreglers (u. a. für ACC, GRA, Speed Limiter). Das Signal wird vom Getriebe benutzt, um die von GRA/ACC geforderte Sollbeschleunigung in dem verbrauchsgünstigsten Gang einzustellen.
MQB: Im MQB wird die Sollbes";
CM_ SG_ 267 TSK_Freig_Verzoeg_Anf "Freigabe der Verzögerungsanforderung der ACC oder ggf. GRA+ Funktion für ECD Regelung im ESP";
CM_ SG_ 267 TSK_Hauptschalter_GRA_ACC "Stellung des GRA/ACC Hauptschalters. Das Signal wird auch bei Fehlerabschaltungen von GRA/ACC weiterhin bedient und ermöglicht für ACC die Steuerung der ACC-Anzeige auch in Fehlerfällen.";
CM_ SG_ 267 TSK_Kategorie_Verzoegerungsfkt "Zeigt der Bremslichtfunktion an, ob die aktuell verzögerungswirksame Teilnehmerfunktion am TSK als Fahrerassistenzsystem oder als Schubrekuperation zu interpretieren ist.";
CM_ SG_ 267 TSK_Limiter_ausgewaehlt "ACC/GRA-Betrieb nur bei nicht ausgewähltem Limiter möglich";
CM_ SG_ 267 TSK_Notstopp_Anf "Anforderung Notstopp des TSK";
CM_ SG_ 267 TSK_Radbremsmom "Bei der Schnittstelle vom TSK zum ESP soll in Folgeprojekten des B8 und insbesondere bei VW-Projekten die Ansteuerung der Bremse nicht über Sollbeschleunigung sondern Bremsmoment erfolgen.  Es handelt sich genauer um das Summenradbremsmoment, welches die ";
CM_ SG_ 267 TSK_Radsollmoment "Sollradmoment vom TSK";
CM_ SG_ 267 TSK_SRBM_Anf_ASIL "ASIL-Level des TSK-Anforderers, der aktuell eine Bremsmomentenanforderung auslöst";
CM_ SG_ 267 TSK_SRBM_max_Gradient "In diesem Signal wird der vom TSK maximal geforderte SummenRadBremsMomentengradient gesendet, der von der Bremse bei der Umsetzung der TSK-Verzögerung nicht überschritten werden darf.";
CM_ SG_ 267 TSK_Standby_Anf_ESP "Mit diesem Bit wird das aktive Bremssystem auf eine anstehende TSK-Verzögerungsanforderung vorbereitet (Überfahren Leerweg, Anlegen Bremsbeläge)";
CM_ SG_ 267 TSK_Status "Betriebszustand des TSK-Reglers";
CM_ SG_ 267 TSK_v_Begrenzung_aktiv "Limiter oder HGB begrenzen die Beschleunigung/das Moment";
CM_ SG_ 267 TSK_zul_Regelabw "Anforderung der zulässigen Regelabweichung vom Triebstrangkoordinator. Zulässiger Betrag der Abweichung zwischen angeforderter 'TSK_Sollbeschleunigung_Getriebe' und umzusetzender Sollbeschleunigung  im Getriebe. Im TSK wird, abhängig vom Arbeitspunkt die ";
CM_ SG_ 267 TSK_Zwangszusch_ESP "Mit diesem Bit wird das ESP/ASR zwangsweise aktiviert. Bei gesetztem Bit ist ein ausgetastetes ESP (oder ASR) wieder aktiviert bzw. wird die Austastung verhindert.";

CM_ SG_ 330 Ladezustand_02 "Aktueller relativer Ladezustand der HV-Batterie
";
CM_ SG_ 330 Ladezustand_gering "Fahrerwarnung bezüglich geringem Ladezustand der HV-Batterie";
CM_ SG_ 330 Ladezustand_kritisch "Dient zur Triggerung der Tiefentladewarnung für die HV-Batterie mit einer Ladeaufforderung im Kombi. Die Tiefentladewarnung tritt bei sehr langen Standzeiten auf, z.B. im Showroom.";
CM_ SG_ 330 MO_Anzeige_Drehmoment "Drehmomentssignal für Sport-HMI im Kombi.";
CM_ SG_ 330 MO_Anzeige_Leistung "Leistungssignal für Sport-HMI im Kombi.";
CM_ SG_ 330 MO_Anzeige_Verbr_Einheit "Signal steht im Kontext MO_Anzeige_Verbrauch und überträgt die Verbrauchseinheit der aktuellen Antriebsart. Signal muss in der gleichen Botschaft wie MO_Anzeige_Verbrauch übertragen werden";
CM_ SG_ 330 MO_Anzeigedrehz "Optimierte Anzeigedrehzahl wegen sportlicherem Drehzahlmesser im Kombi. 
Bei Parallelhybrid: Anzeige VKM- Drehzahl nach Anzeigekonzept

Hinweis: Ehemaliger Fehlerwert 0xFFF wird senderseitig nicht unterstützt. Diesen Wert aus Kompatibilitätsgründen nic";
CM_ SG_ 330 MO_Effizienzmodus "Bei Handschaltern wird  das Fahrprogramm Effizienz signalisiert. 
Bei Automatikgetrieben wird das Fahrprogramm 'D' durch 'E' ersetzt.";
CM_ SG_ 330 MO_ePerformance "Zeigt die elektrische Leistungreserve bei BEV und PHEV Projekten an.
Bei Init und Fehler soll keine Anzeige erfolgen. ";
CM_ SG_ 330 MO_ePowermeter "Anzeige ePowermeter (Fahrreserve elektrisch bis Start Verbrennungsmotor (Verbrenner startet bei 100%))";
CM_ SG_ 330 MO_Fehler_Oeldrucksensor "Steuert  im Kombiinstrument die gelbe zentrale Warnlampe und das Symbol 'gelbe Ölkanne'  mit der Textmeldung 'Sensorfehler: Werkstatt aufsuchen' an
";
CM_ SG_ 330 MO_Hochschaltdrehz "Hochschaltdrehzahl bei manuellem Gangwechsel über Lenkrad Tip-Up oder Gangwahlhebel falls dieser in Tippgasse.
Nur AUDI RS-Modelle!";
CM_ SG_ 330 MO_Istgang "Aktueller Gang für Anzeige Hochschaltempfehlung (gültig, wenn MO_Schaltempf_verfbar = 1).

Anzeige im Kombi:
Sollgang == Istgang         ==> Anzeige Istgang
Sollgang !=   Istgang         ==> Schaltempfehlung
Sollgang == Istgang == 0 ==> keine Anzeige";
CM_ SG_ 330 MO_KVS "Motorsteuergerätinterner Verbrauchszähler, der vom Kombi zyklisch ausgelesen wird, um die Einspritzmenge zur Verbrauchsmessung aufzusummieren; aus diesem Zählerstand werden Momentan- und Durchschnittsverbrauch berechnet; das Überlauf-Bit ist zu berücksich";
CM_ SG_ 330 MO_KVS_Ueberlauf "Der motorsteuergeräteinterne Verbrauchszähler ist mindestens einmal übergelaufen. Dieses Bit wird genutzt, um erkennen zu können, daß das Motorsteuergerät aus dem Reset-Zustand hochläuft.";
CM_ SG_ 330 MO_Ladedruck "absoluter Ladedruck";
CM_ SG_ 330 MO_Oeldruck "Öldruck analog zur Anzeige";
CM_ SG_ 330 MO_OnePedalDriving_Warnung "Bewarnung des Fahrers, wenn keine ausreichende Verzögerung aus der Funktion OnePedalDriving dargestellt werden kann.
MO_OnePedalDriving_Warnung = 0  -> keine Warnung
MO_OnePedalDriving_Warnung = 1  -> 1. Warnstufe";
CM_ SG_ 330 MO_Powermeter "Anzeigewerte im Kombi
0       = Unteres Ende Bremsen/grau;
340   = Unteres Ende CHARGE;
1020 = READY;
1870 = Oberes Ende EFFICIENCY;
3400 = 100%;
4080 = MAX;";
CM_ SG_ 330 MO_Powermeter_Elm_02 "relatives Moment / relative Leistung der elektrischen Maschine";
CM_ SG_ 330 MO_rel_Ladedruck "relativer Ladedruck (für Boostanzeige)";
CM_ SG_ 330 MO_Schaltblitz_Anz "Signalisierung der drehzahlabhängigen Schaltblitzanzeige im Kombiinstrument (0-100%)";
CM_ SG_ 330 MO_Schaltempf_verfbar "Info, ob Schaltempfehlung im Fzg. verfügbar. Statischer Wert, ändert sich für ein Fzg. nicht!";
CM_ SG_ 330 MO_Sollgang "Motor sendet den Sollgang in den der Fahrer schalten soll. Wird im Kombi als Hochschaltempfehlung hervorgehoben (gültig, wenn MO_Schaltempf_verfbar = 1).

Anzeige im Kombi:
Sollgang == Istgang          ==> Anzeige Istgang
Sollgang !=  Istgang         ";
CM_ SG_ 330 MO_Zust_Antrieb "Signalisiert die Zuordnung der Antriebsverbräuche zu den Antriebsmaschinen für die Restreichweitenberechnung, nicht gleichbedeutend mit Motorlauf EM oder VM bzw. Brennstoffzelle";
CM_ SG_ 330 MO_Zust_Betriebsstrategie "Signalisiert den aktuellen Zustand der Betriebsstrategie";

CM_ SG_ 512 CE_CtrPrpPrep "Anzeigesignal für Countdown des Aufheizfortschritts (VW-Anzeigekonzept)";
CM_ SG_ 512 CE_FlgEmiColdLmp "Ausgabe einer aktiven Momenteneinschränkung während des Kaltstart.";
CM_ SG_ 512 CE_FlgEmiColdTxt "„Volle Antriebsleistung demnächst verfügbar“
VW: mit Aktivierung der Emissionskaltleuchte für 5s sichtbar
AUDI: Anzeige solange max. Leistung < Schwelle (zB. 50%)";
CM_ SG_ 512 CE_FlgHybModAdvi "'Für volle Antriebsleistung Hybrid-Modus wählen'";
CM_ SG_ 512 CE_FlgPTLimPrfTxt "PopUp für Fahrerwarnung bei Derating aufgrund zu hoher Abgastemperatur

„Fahrleistung temporär eingeschränkt“";
CM_ SG_ 512 CE_PrctPrpPrep "Anzeigesignal für Ladebalken des Aufheizfortschritts";
CM_ SG_ 512 CE_StLdRdcEmiSysPrep "Status Lastreduktion zur Konditionierung des Abgassystems";
CM_ SG_ 512 CE_StStrtDlyEmiSysPrep "Startverzögerung aufgrund Emissionssystem";
CM_ SG_ 512 ISA_Tempolimit_Regelung "Anzeige des expliziten Tempolimits zur Regelgrundanzeige";
CM_ SG_ 512 MO_Antriebsstrang_Warnung_HS "Status der Fehlerlampen-Ansteuerung und Textausgabe für Fehlerspeichereinträge aus der Kupplungsschutz-Funktion für Handschaltgetriebe.";
CM_ SG_ 512 MO_Anzeige_Betriebsmodus "Info an das Kombi zur Anzeige verschiedener Betriebsmodi";
CM_ SG_ 512 MO_Anzeige_Fahrbereitschaft "Signalisiert dauerhaft an das Kombi, ob die Fahrbereitschaft vorhanden ist (Drehzahlmesser auf READY)";
CM_ SG_ 512 MO_Anzeige_Rekuperation "Signal steht im Kontext zu MO_Anzeige_Verbrauch und wird für die Anzeige des Reku-Bereiches im grafischen Momentanverbrauch verwendet";
CM_ SG_ 512 MO_Anzeige_Verbrauch_oE "Anzeige Verbrauchssignal fürs Kombi. Im Bezug auf Verbrennerbeteiligung. Das Signal ist einheitenlos. Die zugehörige Einheit wird in MO_Anzeige_Verbr_Einheit übertragen.";
CM_ SG_ 512 MO_Boost_aktiv "Anzeige im Kombi ob Boost aktiv ist.
Die Anzeige wird zusätzlich über das Signal MO_Boost_verfuegbar gesteuert.
";
CM_ SG_ 512 MO_Boost_verfuegbar "Anzeige des aktuell verfügbaren Boostpotentials im Kombiinstrument.";
CM_ SG_ 512 MO_BZS_Charisma_FahrPr "Rückmeldung des aktuellen Charisma-Fahrprogramms der MSG Betriebsstrategie

MLBevo: Aktuelles Fahrprogramm des Charisma-Teilnehmers (siehe Systemlastenheft Drive Select)
MQB: Istwert der Kennlinie (siehe Systemlastenheft MQB FPA)";
CM_ SG_ 512 MO_BZS_Charisma_Status "Charisma Systemstatus des Charisma-Teilnehmers MSG (Betriebszustände)

Wert 0x3 ist nur für Fahrzeuge ab MQB relevant";
CM_ SG_ 512 MO_Charisma_FahrPr "MLBevo: Aktuelles Fahrprogramm des Charisma-Teilnehmers (siehe Systemlastenheft Drive Select)
MQB: Istwert der Kennlinie (siehe Systemlastenheft MQB FPA)";
CM_ SG_ 512 MO_Charisma_Status "Charisma Systemstatus des Charisma-Teilnehmers

Wert 0x3 ist nur für Fahrzeuge ab MQB relevant";
CM_ SG_ 512 MO_Drehzahlbeeinflussung "Faktor zur Anhebung der Fahrdrehzahl im Warmlauf";
CM_ SG_ 512 MO_Kuehlmitttel_Sensor_AGB2 "Signal der Sensorelektroden für den Kühlmittelfüllstand HV-Kreis im HEV aktuell, entstört, bewertet (OK/Mangel)";
CM_ SG_ 512 MO_Luftpfad_aktiv "Getriebeeingriff wird zusätzlich zum Zündungspfad auch über den Luftpfad umgesetzt, kommt zu MLB neu in die PL48-Getriebe";
CM_ SG_ 512 MO_MAX_Wunschdrehzahl "maximale Motorwunschdrehzahl, die vom Getriebe nicht überschritten werden darf

Signal darf GE_Synchro_Wunschdrehzahl nicht spiegeln";
CM_ SG_ 512 MO_MIN_Wunschdrehzahl "minimale Motorwunschdrehzahl aufgrund Regeneration, die vom Getriebe nicht unterschritten werden darf

Hinweis: 
Ehemaliger Fehlerwert 0xFF wird senderseitig nicht unterstützt. 
Diesen Wert aus Kompatibilitätsgründen nicht neu belegen!";
CM_ SG_ 512 MO_Motorlaufwarnung "Signal zur Anforderung der 'Motorlaufwarnung' im Kombi.";
CM_ SG_ 512 MO_NGS_Position "Messwert des Neutralgangsensors
(nur Handschalter)";
CM_ SG_ 512 MO_NGS_Status "Status des Signals MO_NGS_Position. Das MSG prüft die Plausibilität nur hinsichtlich sicher geöffnetem Triebstrang.";
CM_ SG_ 512 MO_Overboost "Nur Turbo. Anzeige eines Overboostpfeils im Kombi während Overboostzustand der Ladedruckregelung.";
CM_ SG_ 512 MO_Prio_MAX_Wunschdrehzahl "Prioritätsbit der Motorwunschdrehzahl  als MAX";
CM_ SG_ 512 MO_Prio_MIN_Wunschdrehzahl "Prioritätsbit der Motorwunschdrehzahl als MIN";
CM_ SG_ 512 MO_Rampenzeit_Generator_Anf "Das Motorsteuergerät kann eine Load-Response-Zeit des Generators vom Niedervoltenergiemanagement (NVEM) anfordern. Die Load-Response-Zeit wird vom NVEM umgesetzt, wenn dies bordnetzverträglich möglich ist.";
CM_ SG_ 512 MO_Sperrung_FahrPr_BZS "Sperrung einzelner Betriebszustände bzgl. Kommunikation zwischen Motor-SG und Charisma-SG (Gateway)";
CM_ SG_ 512 MO_StSt_Charisma_FahrPr "MLBevo: Aktuelles Fahrprogramm des Charisma-Teilnehmers (siehe Systemlastenheft Drive Select)
MQB: Istwert der Kennlinie (siehe Systemlastenheft MQB FPA)";
CM_ SG_ 512 MO_StSt_Charisma_Status "Charisma Systemstatus des Charisma-Teilnehmers

Wert 0x3 ist nur für Fahrzeuge ab MQB relevant";
CM_ SG_ 512 MO_Text_Aktivierung_Antrieb "Fahrerinformation zur Antriebsstrangaktivierung.";
CM_ SG_ 512 MO_v_Begrenz_Aktivierbar "Fehlerbit wird vom Motor-SG gesetzt, wenn dieses nicht in dieGeschwindigkeits-begrenzung gehen kann, ein Fehler während der v-Begrenzung auftritt oder v > v_Begrenzung - v_Delta";
CM_ SG_ 512 MO_v_Begrenzung_Niveau "Zeigt an, ob eine v-Begrenzung aufgrund Anforderung der Niveauregelung  im MSG aktiv ist oder nicht (Signal für Niveau zum Steuern der Kombianzeige).";
CM_ SG_ 512 PEA_Abschalttexte "Das Signal dient dem Anzeigen von Abschalttexten, wenn PEA nicht verfügbar ist";
CM_ SG_ 512 PEA_Ereignisanzeige "Das Signal dient der Anzeige des Hinweisgrundes";
CM_ SG_ 512 PEA_Ereignisanzeige_temporaer "Signal dient zur Steuerung einer TPA Anzeige im Kombi";
CM_ SG_ 512 PEA_Fahrerinfo "PEA sendet im Hinweis-/Störungsfall an das Kombi Informationen zum Anzeigen (Text + Akustik)";
CM_ SG_ 512 PEA_Fortschrittsanzeige "Ablaufbalken für PEA-Hinweise";
CM_ SG_ 512 PEA_Hinweis "Aufforderung für Fahrerhandlung durch PEA";
CM_ SG_ 512 PEA_Zielgeschw "Das Signal dient der Anzeige einer Geschwindigkeit eines Geschwindigkeitsereignisses für PEA";
CM_ SG_ 512 PEA_Zielgeschw_Einheit "Einheit der anzuzeigenden Zielgeschwindigkeit für PEA (Prädiktiver Effizienz Assistent)";
CM_ SG_ 512 TSK_Akustik "Anforderung zur Ausgabe Akustischer Meldungen des Triebstrangkoordinators";
CM_ SG_ 512 TSK_Fahrzeugstatus_GRA "Zur Anzeige der Nicht-Verfuegbarkeit des Geschwindigkeitsregelanlage im Fahrzeugstatus";
CM_ SG_ 512 TSK_Fahrzeugstatus_Limiter "Zur Anzeige der Nicht-Verfuegbarkeit des Speedlimiters im Fahrzeugstatus";
CM_ SG_ 512 TSK_Fahrzeugstatus_praed_Fkt "Zeigt den Status der Prädiktion der Kundenfunktionen P_LIM und P_ GRA an";
CM_ SG_ 512 TSK_Limiter_Anzeige "Signalisiert den Wunsch des MSG an das Kombiinstrument, seine Anzeige auf Limiter umzuschalten";
CM_ SG_ 512 TSK_Limiter_Fahrerinfo "Fahrerhinweise und Warnungen des Speedlimiters";
CM_ SG_ 512 TSK_naechstes_Event "Anzeige des naechsten Streckenereignisses, welches in der PGRA-PLIM Regelung eine Änderung der Zielgeschwindigkeit zur Folge hat";
CM_ SG_ 512 TSK_naechstes_Event_Einheit "Das Signal zeigt an in welcher Einheit der Hinweis anzuzeigen ist. Bspw. Schilder in mph und Anzeige in Km/h";
CM_ SG_ 512 TSK_praed_Wunschgeschw "Zur Anzeige der prädiktiven Wunschgeschwindigkeit von GRA/Speedlimiter im Kombiinstrument";
CM_ SG_ 512 TSK_praediktiver_Automode "Signal zur Anzeige des Automodes bei praediktivem Limiter/GRA";
CM_ SG_ 512 TSK_praediktiver_Hinweis "Anzeigesteuerung ob Geschwindigkeitshinweis als Vorschlag (zur Übernahme) oder als Hinweis (bei automatischer Übernahme) behandelt werden soll";
CM_ SG_ 512 TSK_Status_Anzeige "Signalisiert den Status von GRA oder Limiter zur Anzeige im Kombiinstrument.
Der Signalwert 'Limitierung_aktiv' wird nur verwendet für den Audi Speedlimiter und zeigt bei aktivier Funktion an, dass nahe an der Abregelgeschwindigkeit gefahren wird und die";
CM_ SG_ 512 TSK_Texte "Textmeldungen des TSK zur Darstellung im Kombi";
CM_ SG_ 512 TSK_Texte_Primaeranz "Trigger für Anzeigetexte von GRA und Limiter, GRA Temporäranzeige (Audi) und Limiter Warnungen

0 keine Anzeige 
1 GRA Symbol passiv xxx km/h / mph (nur Audi)
2 GRA Symbol aktiv xxx km/h / mph (nur Audi)
3 Bremse überhitzt ! (reserv.)
4 Limiter Modu";
CM_ SG_ 512 TSK_Wunschgeschw "Zur Anzeige der Wunschgeschwindigkeit von GRA/Speedlimiter im Kombiinstrument";

CM_ SG_ 332 CE_FlgLnchCtlPreCnd "Launch Control: status of combustion engine preconditions";
CM_ SG_ 332 FoD_DTC_TSK_ACC "DTC ist entweder bereits eingetragen oder wird eingetragen, sobald die zugehörige FOD Funktion freigeschaltet wird.";
CM_ SG_ 332 FoD_DTC_TSK_GRA "DTC ist entweder bereits eingetragen oder wird eingetragen, sobald die zugehörige FoD Funktion freigeschaltet wird.";
CM_ SG_ 332 ISA_Regelung_aktiv "Signalisiert, dass die Regelung zur Überführung der Fahrzeuggeschwindigkeit auf ein gültiges Tempolimit der Funktion Intelligent Speed Assist (ISA) aktiv ist.";
CM_ SG_ 332 ISA_Status "Signalisiert den Status der Funktion Intelligent Speed Assist (ISA). Der Status zeigt an, ob ISA Tempolimits übernimmt und einregelt. Dabei wird unterschieden, ob es sich um eine globale Aktivierung/Deaktivierung der Funktion, oder um eine temporäre Einsc";
CM_ SG_ 332 ISA_Tempolimitwarnung "Signal zur Ausgabe einer Warnung an den Fahrer, wenn bei aktiviertem Intelligent Speed Assit (ISA) das gültige Tempolimit überschritten wird.";
CM_ SG_ 332 MO_Anforderung_HMS "Halteanforderung vom Motor an HMS";
CM_ SG_ 332 MO_EBoost_verf_praed "Zeigt an, ob für eine im Projekt definierte Zeit (max. 10s) E-Boost in Höhe von EM1_maxPred_Moment verfügbar sein wird.

0 - Init_oder_nicht_verfügbar
1 - EBoost_kurzzeit_verfügbar (~3Sek.)
2 - EBoost_langzeit_verfügbar (~10Sek)";
CM_ SG_ 332 MO_eLaunch_verf "Zeigt an, ob aus Antriebssicht E-Launch verfügbar ist.";
CM_ SG_ 332 MO_EMG_Max_Leistung "zugeteilte elektrische Leistung für den motorischen Betrieb;
elektrische Leistung zur Berechnung eines momentan möglichen maximalen Moments";
CM_ SG_ 332 MO_EMG_Min_Leistung "zugeteilte elektrische Leistung für den generatorischen Betrieb;
elektrische Leistung zur Berechnung eines momentan möglichen minimalen Moments";
CM_ SG_ 332 MO_Fahrbereitschaft "Das Signal MO_Fahrbereitschaft zeigt in mehreren Stufen an, ob der Motor in einem anfahrbereiten Zustand ist.";
CM_ SG_ 332 MO_Freilauf_Info "Freilauf Informationssignal vom Motorsteuergerät zum Getriebesteuergerät. Das Motorsteuergerät kann über dieses Signal den Freilauf freigeben, verhindern bzw. explizit anfordern.";
CM_ SG_ 332 MO_Freilauf_Status "Freilauf-Status-Signal vom Frailauf-Master an aktive Freilauf-Teilnehmer. In diesem Signal zeigt der Freilauf-Master an, welchen aktuellen Status die Freilauf-Betriebsstrategie hat.";
CM_ SG_ 332 MO_Heckspoiler_Anf "Anforderung den Heckspoiler zur Ladeluft- bzw. Motorraumkühlung auszufahren.";
CM_ SG_ 332 MO_Klima_Regelmodus "Anforderung an Klima SG zur Regelungsanpassung der HV Klimakomponenten bei bestimmten Umweltbedingungen";
CM_ SG_ 332 MO_Krit_Heckobjekt "Beschreibt die Kritikalität des hinter einem in der Spur fahrenden Fahrzeuges";
CM_ SG_ 332 MO_Kuppl_betaetigt "Das Motorsteuergerät gibt eine plausibilisierte Information aus, ob die Kupplung betätigt oder nicht betätigt wurde.";
CM_ SG_ 332 MO_LaunchControl "Signalisierung einer verfügbaren LaunchControl Funktion ans Kombiinstrument";
CM_ SG_ 332 MO_MVEM_MaxLeistung_MVVerbrauch "Einzuhaltende Max-Grenze der Leistungsaufnahme bzw. -abgabe der 48V-Verbraucher (inkl 48V-DC/DC-Wandler) im 48V-Netz. Für Begrenzung der Leistungsaufnahme der MV-Verbraucher vorgesehen.

Verbrauch - positiv";
CM_ SG_ 332 MO_MVEM_MinLeistung_MVVerbrauch "Einzuhaltende Min-Grenze der Leistungsaufnahme bzw. -abgabe der 48V-Verbraucher (inkl 48V-DC/DC-Wandler) im 48V-Netz. Für Anforderung einer Leistungsaufnahme der MV-Verbraucher vorgesehen. 
 
Verbrauch - positiv
Rückspeisung - negativ";
CM_ SG_ 332 MO_NGS_Gangpos "Gang- bzw. Neutralinformation des erweiterten Neutralgangsensors. Bedingt durch den eingeschränkten Erfassungssbereich des Sensors sind die Ganginformationen als eingelegt bzw. fast eingelegt/vorausgewählt zu interpretieren (nur Handschalter)";
CM_ SG_ 332 MO_Positionierung_aktiv "Zeigt an, dass die Motorpositionierung mit Hilfe des Riemenstartergenerator momentan aktiv ist.";
CM_ SG_ 332 MO_QBit_Aussen_Temp "QBit der Aussentemperatur. Gesetzt bei Ersatzwert, Init oder Fehler.";
CM_ SG_ 332 MO_QBit_Kuppl_betaetigt "Q - Bit für das Signal Kupplung betätigt";
CM_ SG_ 332 MO_Red_El_Fahrleistung "Anzeige einer eingeschränkten Fahrleistung";
CM_ SG_ 332 MO_Servicemodus "Ausgabe aktiver Service-Mode";
CM_ SG_ 332 MO_Startwunsch "o	Setzen bei Erfüllung der kompletten Fahrerbedienhandlung (z.B. Zündanlasstaster + Bremse + Fahrstufe P/N [klassisch] oder Fahrstufe D/R + Bremse [MEB]), je nach Fahrzeug z.T. bereits vor oder immer erst nach Einschalten der Klemme 15;
o	Rücksetzen bei ";
CM_ SG_ 332 MO_UBE_Hybrid_Reserve "Seitens Antrieb in einem (P)HEV erforderliche Energiereserve der HV-Batterie, die den Fußpunkt der „Usable Battery Energy“ (BMS_UBE) verschiebt. Die Reserve dient der Darstellung von Hybrid-Grundfunktionen (z.B. Start/Stopp, elektrisch Kriechen,usw.) unte";
CM_ SG_ 332 MO_UBE_Reserve "Seitens Antrieb erforderliche Energiereserve der HV-Batterie, die den Fußpunkt der „Usable Battery Energy“ (BMS_UBE) verschiebt. Die Reserve dient der Gewährleistung von Sicherheitsfunktionen und ggf. Emissionierungsmaßnahmen unterhalb des Fahrbetriebs im";
CM_ SG_ 332 MO_Veto_Launchcontrol "Veto des Motor-Steuergeräts bzgl. der Aktivierung der Launch-Control";
CM_ SG_ 332 Motor_54_BZ "4bit Botschaftszähler, wird mit jeder Sendebotschaft inkrementiert";
CM_ SG_ 332 Motor_54_CRC "Für MLB:
Berechnung siehe Lastenheft 'Kommunikationsabsicherung für FlexRay und CAN'
Ab MQB und MLBevo:
Berechnung siehe Lastenheft 'End-to-End Kommunikationsabsicherung'

Endwerte siehe Begleitdokument 'S-PDU Kennungsfolgen'";
CM_ SG_ 332 OBD_Abs_Load_Val "Absolute Load Value

Übertragung von Meßgrößen an das Getriebesteuergerät für Freeze Frame Abspeicherung bei Getriebefehlern

PID $43 Absolute Load Value; 0 .. 25700%  mit 100/255 %/bit";
CM_ SG_ 332 OBD_Abs_Pedal_Pos "Absolute Pedal Position

Übertragung von Meßgrößen an das Getriebesteuergerät für Freeze Frame Abspeicherung bei Getriebefehlern

PID $49 Accelerator Pedal Position D; 0 .. 100% mit 100/255 %/bit";
CM_ SG_ 332 OBD_Abs_Throttle_Pos "Absolute Throttle Position

Übertragung von Meßgrößen an das Getriebesteuergerät für Freeze Frame Abspeicherung bei Getriebefehlern

PID $11 Absolute Throttle Position; 0 .. 100% mit 100/255 %/bit";
CM_ SG_ 332 OBD_Aussen_Temp_gef "Gefilterte Aussentemperatur vom Motor für OBD Funktionen.";
CM_ SG_ 332 OBD_Calc_Load_Val "Calculated Load Value

Übertragung von Meßgrößen an das Getriebesteuergerät für Freeze Frame Abspeicherung bei Getriebefehlern

PID $04 Calculated Load Value; 0 .. 100% mit 100/255 % per bit
";
CM_ SG_ 332 OBD_ClearMem_Inhibit "Bei FSP_Loeschen_zulässig müssen alle OBD-ECUs im Gesamtfahrzeug einen Service 04hex Request (Ereignisspeicher löschen) korrekt ausführen. 

In MLB-, MLBevo-, MQB-Fahrzeugkonzepten muss der MIL-Master/Motorsteuergerät bei Kl.15 ein, projektabhängig, kon";
CM_ SG_ 332 OBD_Driving_Cycle "Signalisierung Driving Cycle Qualifizierung - Trigger Ignition Cycle Counter";
CM_ SG_ 332 OBD_Eng_Cool_Temp "Engine Coolant Temperature

Übertragung von Meßgrößen an das Getriebesteuergerät für Freeze Frame Abspeicherung bei Getriebefehlern

PID $05 Engine Coolant Temperature; -40 .. +215°C mit 1°C/bit und 40°C Offset";
CM_ SG_ 332 OBD_Kaltstart_Denominator "Bestimmte Diagnosen werden nur unter Kaltstartbedingungen durchgeführt, der entsprechende Denominator bei IUMPR-pflichtigen Systemen wird anhand dieses vom MSG gebildeten Signals inkrementiert. (Entspricht EVAP-Denominator)";
CM_ SG_ 332 OBD_Minimum_Trip "Grundlage OBD-Gesetz CCR 1968.2 (d)(4.3) Denominator Specifications
Bildung des General Denominator 'Normed Trip':
 600 sec. (kumulativ) Zeit nach Motorstart
 300 sec. (kumulativ) mit Fahrzeuggeschwindigkeit > 25 mph (40 km/h)
 30 sec. (kontinuierlich";
CM_ SG_ 332 OBD_Normed_Trip "Gesetzlich definierte 'Normed Condition' erfüllt, 'General Denominator' darf erhöht werden";
CM_ SG_ 332 OBD_Sperrung_IUMPR "Wenn der General Denominator auf Grund eines Fehlers in den Eingangsgrößen gesperrt wird, wird diese Information über Bussystem als OBD-Statusinformation OBD_Sperrung_IUMPR für andere OBD-Steuergeräte bereitgestellt. 

Das MSG (MIL-Master) setzt dieses ";
CM_ SG_ 332 OBD_Sperrung_Kaltstart_Denom "Information vom MIL Master, dass die Bildung des EVAP Denominators  im Motor nicht möglich ist und damit der noECM-Denominator gesperrt werden darf.";
CM_ SG_ 332 OBD_Warm_Up_Cycle "Mit dem Warm-Up-Cycle wird der zentrale Verlernzähler vom Gateway inkrementiert";
CM_ SG_ 332 OBDProtocol_req "Der PrimaryOBDECU_MILMaster stellt allen PrimaryOBDECUnoMILMaster über das Bussignal [OBDProtocol_req], das für das Fahrzeug zu verwendende OBD-Diagnoseprotokoll bereit.";
CM_ SG_ 332 TSK_ACC_FoD_Status "Information, ob die TSK-ACC-Funktion freigeschaltet ist oder nicht.";
CM_ SG_ 332 TSK_aktives_System "Anzeige der in der TSK-Längsführung aktiven Funktion";
CM_ SG_ 332 TSK_aktives_System_02 "Anzeige der in der TSK-Längsführung aktiven Funktion";
CM_ SG_ 332 TSK_Anf_Antriebsmoment "Das Signal zeigt an, ob die TSK-Laengsregelung aktuell Antriebsmoment anfordert, zur Verwendung in der ASR/EDS-Funktion";
CM_ SG_ 332 TSK_Einheit_vMax_Fahrerassistenz "Einheit zu Signal TSK_vMax_Fahrerassistenz";
CM_ SG_ 332 TSK_erhoehter_Fahrwiderstand "Rueckmeldung vom Triebstrangkoordinator, dass eine große Reglerdifferenz detektiert wurde. Soll ermoeglichen, einen ggfs. unbekannten Fahrwiderstand am Boden zu erkennen.";
CM_ SG_ 332 TSK_GRA_FoD_Status "Information, ob die TSK-GRA-Funktion freigeschaltet ist oder nicht.";
CM_ SG_ 332 TSK_Status_ARA "Funktionsstatus des Triebstrangkoordinators für den Anhängerrangierassistenten";
CM_ SG_ 332 TSK_Status_EA "Funktionsstatus des Triebstrangkoordinators für den Anforderer Emergency Assist";
CM_ SG_ 332 TSK_Status_IPA "Funktionsstatus des Triebstrangkoordinators für die Längsführung des Einparkassistenten";
CM_ SG_ 332 TSK_Status_PLA "Funktionsstatus des Triebstrangkoordinators für den Speedlimiter des Parkassistenten";
CM_ SG_ 332 TSK_Status_RHP "Functional status of the drive train coordinator for the longitudinal guidance of the rush hour pilot.";
CM_ SG_ 332 TSK_vMax_aktuell "Im aktuellen Betriebszustand global gültige Geschwindigkeitslimitierung.";
CM_ SG_ 332 TSK_vMax_Fahrerassistenz "maximale Sollgeschwindigkeit für GRA/ACC/Limiter
Hinweis: Signal ist mit Signal TSK_Einheit_vMax_Fahrerassistenz zu interpretieren.  Das Signal wird abwechselnd in km/h und mph gesendet.";

CM_ SG_ 553 SOK_Motor_54_Signatur "Signatur im Rahmen der durch SOK geschützten Broadcast-Kommunikation

Geschützte Funktion: ORU
Geschützte Botschaft: Motor_54";

CM_ SG_ 246 FDR_Allrad_Anteil_max_sek "Maximaler prozentualer Anteil der sekundären Antriebsachse am Gesamtmoment - wird soweit dies durch die Leistungsfähigkeit der Achse möglich ist eingehalten";
CM_ SG_ 246 FDR_Allrad_Anteil_min_sek "Minimaler prozentualer Anteil der sekundären Antriebsachse am Gesamtmoment - wird soweit dies durch die Leistungsfähigkeit der Achse möglich ist eingehalten";
CM_ SG_ 246 FDR_MomRad_Eingriff "maximal zulässiges Moment primäre Antriebsachse";
CM_ SG_ 246 FDR_MomRad_Eingriff_sek "maximal zulässiges Moment sekundäre Antriebsachse";
CM_ SG_ 246 FDR_Status_Eingriff "Eingriff primäre Antriebsachse aktiv";
CM_ SG_ 246 FDR_Status_Eingriff_sek "Eingriff sekundäre Antriebsachse aktiv";
CM_ SG_ 246 FDR_Zwangszusch_ESP "Mit diesem Bit wird das ESP/ASR zwangsweise aktiviert. Bei gesetztem Bit ist ein ausgetastetes ESP (oder ASR) wieder aktiviert bzw. wird die Austastung verhindert.";
CM_ SG_ 246 MO_EMG_Generator_Leistung "Elektrische Wunschleistung zur Berechnung eines momentan erforderlichen Moments im Generatorbetrieb";
CM_ SG_ 246 MO_EMG_Max_Momentengradient "maximale Änderung des E-Maschinen Moments";
CM_ SG_ 246 MO_EMG_Max_Spannung_Lim "Maximal zulässige Spannung (DC), die vom RSG im generatorischen Betrieb nicht überschritten werden darf; Abregelspannung zur Begrenzung des minimalen Moments im generatorischen Betrieb";
CM_ SG_ 246 MO_EMG_Max_Strom_Lim "maximal zulässiger Strom, der vom RSG im motorischen Betrieb aufgenommen werden darf;
Abregelstrom zur Begrenzung des maximalen Moments im motorischen Betrieb";
CM_ SG_ 246 MO_EMG_Min_Spannung_Lim "Minimal zulässige Spannung (DC), die vom RSG im motorischen Betrieb nicht unterschritten werden darf;
Abregelspannung zur Begrenzung des maximalen Moments im motorischen Betrieb";
CM_ SG_ 246 MO_EMG_Min_Strom_Lim "minimal zulässiger HV-Strom, der von der LE im generatorischen Betrieb abgegeben werden darf (betragsmäßig maximal aber i.d.R. negativ, daher ‚Min‘);
Abregelstrom zur Begrenzung des minimalen Moments im generatorischen Betrieb";
CM_ SG_ 246 MO_EMG_SollDrehzahl "E-Maschinen Soll-Drehzahl";
CM_ SG_ 246 MO_EMG_Sollmodus "Anforderung der Betriebsart der E-Maschine
Werte:
0: Standby; Kommunikation aktiv
1: Momentenregelung
2: Drehzahlregelung (interner Regelkreis)
3: Spannungsregelung
4: Spannungsregelung Batterie Ab
6: Kalibrierung / Anlernen einer neuen EM
8: Frei";
CM_ SG_ 246 MO_EMG_SollMoment_02 "48V-RSG Soll-Moment vom Hybridcontroller";
CM_ SG_ 246 MO_EMG_Sollspannung "Sollspannung des MSGs für den Spannungsgeregelten Modus";
CM_ SG_ 246 MO_Mom_Begr_Fahr_Pred "Einheitenloser Wert!  MO_Faktor_Momente_02  in Motor_Code_01 beachten!

Bei Bezugsdrehzahl quasistationär max. mögliches Moment (Summe aus max. Moment des Verbren-nungsmotors und max. Moment des E-Motors).

Die Bezugsdrehzahl soll je nach Bedienung de";
CM_ SG_ 246 Motor_55_BZ "4bit Botschaftszähler, wird mit jeder Sendebotschaft inkrementiert";
CM_ SG_ 246 Motor_55_CRC "Für MLB:
Berechnung siehe Lastenheft 'Kommunikationsabsicherung für FlexRay und CAN'
Ab MQB und MLBevo:
Berechnung siehe Lastenheft 'End-to-End Kommunikationsabsicherung'

Endwerte siehe Begleitdokument 'S-PDU Kennungsfolgen'";
CM_ SG_ 246 SOK_Motor_55_Signatur "Signatur im Rahmen der durch SOK geschützten Broadcast-Kommunikation

Geschützte Funktion: Bremsfunktionen 
Geschützte Botschaft: Motor_55";
CM_ SG_ 246 TS_Allrad_Anteil_sek "Vom Antrieb gewünschter prozentualer Anteil der sekundären Antriebsachse am Gesamtmoment";
CM_ SG_ 246 TS_Faktor_Radmomente "Schaltet den Wertebereich von Rad-Momenten-Signale diverser SG um, so dass zum einen die max. möglichen Werte übertragen werden können und zum anderen die Auflösung möglichst hoch ist.
Faktor ist über Laufzeit konstant, variiert nur zwischen Fahrzeug-Pro";
CM_ SG_ 246 TS_MomRad_Ist "Gesamt-Istmoment der Antriebsmaschinen, umgerechnet auf Radebene, unter Berücksichtigung der Massenträgheiten der Antriebsmaschinen und des Getriebes, unter Berücksichtigung der Verluste der Antriebsmaschinen, der Nebenaggregate und des Getriebes (d.h. ke";
CM_ SG_ 246 TS_MomRad_Ist_sek "Gesamt-Istmoment der Antriebsmaschinen, umgerechnet auf Radebene, unter Berücksichtigung der Massenträgheiten der Antriebsmaschinen und des Getriebes, unter Berücksichtigung der Verluste der Antriebsmaschinen, der Nebenaggregate und des Getriebes.
Zeigt ";
CM_ SG_ 246 TS_MomRad_Soll_Summe "Faktor in TS_Faktor_Radmomente beachten!

Momentenanforderung aus Fahrpedal bzw. von ACC/GRA bzw. aus dem Leerlaufregler (quasistatischer Anteil); keine Begrenzungen, keine Fahrverhaltensformung, keine Abbildung externer Eingriffsanforderungen; definier";
CM_ SG_ 246 TS_MomRad_verfuegb_max "Faktor in TS_Faktor_Radmomente beachten!

In aktuellem Betriebszustand (u.a. Übersetzung) kurzfristig (ca. 100..200 ms) verfügbares max. positives Moment; 

Zeigt bei antriebstechnisch getrennten Achsen das Moment der primären Achse; zeigt bei mechani";
CM_ SG_ 246 TS_MomRad_verfuegb_max_sek "Faktor in TS_Faktor_Radmomente beachten!

In aktuellem Betriebszustand (u.a. Übersetzung) kurzfristig (ca. 100..200 ms) verfügbares max. positives Moment; 

Zeigt bei antriebstechnisch getrennten Achsen das Moment der sekundären Achse; steht bei mecha";
CM_ SG_ 246 TS_MomRad_verfuegb_maxReku "Faktor in TS_Faktor_Radmomente beachten!

In aktuellem Betriebszustand (u.a. Übersetzung) kurzfristig (ca. 100..200 ms) verfügbares max. negatives Moment; 

Zeigt bei antriebstechnisch getrennten Achsen das Moment der primären Achse; zeigt bei mechani";
CM_ SG_ 246 TS_MomRad_verfuegb_maxReku_sek "Faktor in TS_Faktor_Radmomente beachten!

In aktuellem Betriebszustand (u.a. Übersetzung) kurzfristig (ca. 100..200 ms) verfügbares max. negatives Moment; 

Zeigt bei antriebstechnisch getrennten Achsen das Moment der sekundären Achse; steht bei mecha";
CM_ SG_ 246 TS_MomRad_verfuegb_maxReku_Summe "Im aktuellen Betriebszustand kurzfristig (ca. 100..200 ms) verfügbares max. negatives Summenmoment; definiert auf Bezugsebene Rad.
Faktor in TS_Faktor_Radmomente beachten!";
CM_ SG_ 246 TS_MomRad_Wunsch "Faktor in TS_Faktor_Radmomente beachten!

Wunsch-Moment nach MSG-Betriebs-Strategie-Aufteilung und Umverteilung der Achs-Aufteilung durch EF; nach Lastschlagdämpfung der jeweiligen Achse; incl. Deckelung aufgrund von Schutz-Eingriffen, ohne Berücksichti";
CM_ SG_ 246 TS_MomRad_Wunsch_sek "Faktor in TS_Faktor_Radmomente beachten!

Wunsch-Moment nach MSG-Betriebs-Strategie-Aufteilung und Umverteilung der Achs-Aufteilung durch EF; nach Lastschlagdämpfung der jeweiligen Achse; incl. Deckelung aufgrund von Schutz-Eingriffen, ohne Berücksichti";
CM_ SG_ 246 TS_Status_DrzReg "Dient zur Kommunikation von Fehlerzuständen von Antrieb zum ESC";
CM_ SG_ 246 TS_Status_DrzReg_sek "Dient zur Kommunikation von Fehlerzuständen von Antrieb zum ESC (sekundäre Achse)";
CM_ SG_ 246 TS_Status_MomRad_Ist "Qualitätsstatus zu TS_MomRad_Ist und TS_MomRad_Ist_Sek
Qualifiziert bei antriebstechnisch getrennten Achsen sowohl das Moment der primären Achse als auch das Moment der sekundären Achse, und bei mechanischem Allradantrieb das Gesamtmoment für beide Achse";

CM_ SG_ 190 MO_CluAxs_Set "Sollzustand der Kupplung an der elektrischen Hinterachse";
CM_ SG_ 190 MO_CluEng_Set "Sollzustand der Trennkupplung im TQ250";
CM_ SG_ 190 MO_DC_Max_Strom_HV "Abregelgrenze: maximal freigegebener Strom auf der Hochvolt-Seite im Tiefsetzbetrieb (Strom aus dem Traktionsnetz ins Bordnetz)";
CM_ SG_ 190 MO_DC_SollSpannung_HV "Sollwert für die Traktionsnetzspannung im Hochsetzbetrieb vom Bordnetz ins Traktionsnetz
vorgehaltenes Signal; wird in PQ35/PL71 nicht berücksichtigt";
CM_ SG_ 190 MO_EM1_AR_Anf "Anforderung der Anti-Ruckel Funktion auf der E-Maschine

0: aus
1: nicht belegt
2: D2T2 Regelung
3: Referenzdrehzahl Regelung
4: interne Referenzdrehzahlregelung";
CM_ SG_ 190 MO_EM1_DynLimit_AR "Auslöseschwelle für dynamische Ruckeldämpfung

Der Momentenwert ergibt sich aus der Multiplikation mit dem Faktor MO_EM1_Faktor_AR_Momente (Skalierung Wertebereich und Auflösung).";
CM_ SG_ 190 MO_EM1_Kp_AR "dynamischer Verstärkungsfaktor zur Umrechnung Drehzahlschwingung in Eingriffsmoment";
CM_ SG_ 190 MO_EM1_Max_Leistung "zugeteilte elektrische Leistung für den motorischen Betrieb; elektrische Leistung zur Berechnung eines momentan möglichen maximalen Moments und einer momentan möglichen maximalen mechanischen Leistung";
CM_ SG_ 190 MO_EM1_Max_Moment "maximal erlaubtes positives (motorisches) Moment der E-Maschine aus Hybridstrategie";
CM_ SG_ 190 MO_EM1_Max_Strom_Lim "maximal zulässiger HV-Strom, der von der LE im motorischen Betrieb aufgenommen werden darf; Abregelstrom zur Begrenzung des maximalen Moments im motorischen Betrieb";
CM_ SG_ 190 MO_EM1_MaxDrehzahl "Maximale E-Maschinen-Drehzahl";
CM_ SG_ 190 MO_EM1_Min_Leistung "zugeteilte elektrische Leistung für den generatorischen Betrieb (betragsmäßig maximal aber i.d.R. negativ, daher ‚Min‘);; elektrische Leistung zur Berechnung eines momentan möglichen minimalen Moments und einer momentan möglichen minimalen mechanischen Le";
CM_ SG_ 190 MO_EM1_Min_Moment "maximal erlaubtes negatives (generatorisches) Moment der E-Maschine aus Hybridstrategie";
CM_ SG_ 190 MO_EM1_Min_Strom_Lim "minimal zulässiger HV-Strom, der von der LE im generatorischen Betrieb abgegeben werden darf (betragsmäßig maximal aber i.d.R. negativ, daher ‚Min‘); Abregelstrom zur Begrenzung des minimalen Moments im generatorischen Betrieb";
CM_ SG_ 190 MO_EM1_MinDrehzahl "Minimale E-Maschinen-Drehzahl";
CM_ SG_ 190 MO_EM1_Periode_AR "Zeitkonstante (Periodendauer) der Ruckelschwingung (abhängig vom Gang und ggf. elektrischem/hybridischem Fahren) ";
CM_ SG_ 190 MO_EM1_Sollmodus "Werte:
  Anforderung der Betriebsart der E-Maschine
0: Standby; Kommunikation aktiv; aktiver Kurzschluss
1: Momentenregelung
2: Drehzahlregelung (interner Regelkreis)
3: Spannungsregelung
4: Drehzahlregelung (externer Regelkreis)
5: nicht verfügbar";
CM_ SG_ 190 MO_EM1_SollMoment "E-Maschinen Soll-Moment vom Hybridcontroller";
CM_ SG_ 190 MO_EM1_SollSpannung "E-Maschinen Soll-Spannung";
CM_ SG_ 190 MO_EM2_AR_Anf "Anforderung der Anti-Ruckel Funktion auf der E-Maschine

0: aus
1: nicht belegt
2: D2T2 Regelung
3: Referenzdrehzahl Regelung
4: interne Referenzdrehzahlregelung";
CM_ SG_ 190 MO_EM2_DynLimit_AR "Auslöseschwelle für dynamische Ruckeldämpfung

Der Momentenwert ergibt sich aus der Multiplikation mit dem Faktor MO_EM2_Faktor_AR_Momente (Skalierung Wertebereich und Auflösung).";
CM_ SG_ 190 MO_EM2_Kp_AR "dynamischer Verstärkungsfaktor zur Umrechnung Drehzahlschwingung in Eingriffsmoment";
CM_ SG_ 190 MO_EM2_Max_Leistung "zugeteilte elektrische Leistung für den motorischen Betrieb; elektrische Leistung zur Berechnung eines momentan möglichen maximalen Moments und einer momentan möglichen maximalen mechanischen Leistung";
CM_ SG_ 190 MO_EM2_Max_Moment "maximal erlaubtes positives (motorisches) Moment der E-Maschine aus Hybridstrategie";
CM_ SG_ 190 MO_EM2_Max_Strom_Lim "maximal zulässiger HV-Strom, der von der LE im motorischen Betrieb aufgenommen werden darf; Abregelstrom zur Begrenzung des maximalen Moments im motorischen Betrieb";
CM_ SG_ 190 MO_EM2_MaxDrehzahl "Maximale E-Maschinen-Drehzahl";
CM_ SG_ 190 MO_EM2_Min_Leistung "zugeteilte elektrische Leistung für den generatorischen Betrieb (betragsmäßig maximal aber i.d.R. negativ, daher ‚Min‘);; elektrische Leistung zur Berechnung eines momentan möglichen minimalen Moments und einer momentan möglichen minimalen mechanischen Le";
CM_ SG_ 190 MO_EM2_Min_Moment "maximal erlaubtes negatives (generatorisches) Moment der E-Maschine aus Hybridstrategie";
CM_ SG_ 190 MO_EM2_Min_Strom_Lim "minimal zulässiger HV-Strom, der von der LE im generatorischen Betrieb abgegeben werden darf (betragsmäßig maximal aber i.d.R. negativ, daher ‚Min‘); Abregelstrom zur Begrenzung des minimalen Moments im generatorischen Betrieb";
CM_ SG_ 190 MO_EM2_MinDrehzahl "Minimale E-Maschinen-Drehzahl";
CM_ SG_ 190 MO_EM2_Periode_AR "Zeitkonstante (Periodendauer) der Ruckelschwingung (abhängig vom Gang und ggf. elektrischem/hybridischem Fahren) ";
CM_ SG_ 190 MO_EM2_Sollmodus "Werte:
  Anforderung der Betriebsart der E-Maschine
0: Standby; Kommunikation aktiv; aktiver Kurzschluss
1: Momentenregelung
2: Drehzahlregelung (interner Regelkreis)
3: Spannungsregelung
4: Drehzahlregelung (externer Regelkreis)
5: nicht verfügbar";
CM_ SG_ 190 MO_EM2_SollMoment "E-Maschinen Soll-Moment vom Hybridcontroller";
CM_ SG_ 190 MO_EM2_SollSpannung "E-Maschinen Soll-Spannung";
CM_ SG_ 190 Motor_56_BZ "4bit Botschaftszähler, wird mit jeder Sendebotschaft inkrementiert";
CM_ SG_ 190 Motor_56_CRC "Für MLB:
Berechnung siehe Lastenheft 'Kommunikationsabsicherung für FlexRay und CAN'
Ab MQB und MLBevo:
Berechnung siehe Lastenheft 'End-to-End Kommunikationsabsicherung'

Endwerte siehe Begleitdokument 'S-PDU Kennungsfolgen'";
CM_ SG_ 190 SOK_MO_SollMoment_Signatur "Signatur im Rahmen der durch SOK geschützen Broadcast-Kommunikation

Geschützte Signale: MO_EM1_SollMoment, MO_EM2_SollMoment";

CM_ SG_ 2463978666 MO_Drehzahl_EM "Effektivdrehzahl, die am E-Maschinenausgang ermittelt wird, die für die Primärachse zur Verfügung steht";
CM_ SG_ 2463978666 MO_Drehzahl_EM_sek "Effektivdrehzahl, die am E-Maschinenausgang ermittelt wird, die für die Sekundärachse zur Verfügung steht";
CM_ SG_ 2463978666 MO_EM1_Generator_Leistung "elektrische Wunschleistung zur Berechnung eines momentan erforderlichen Moments im Generatorbetrieb";
CM_ SG_ 2463978666 MO_EM1_Max_Leistung_Gesamt "im Gesamtsystem verfügbare elektrische Leistung für den motorischen Betrieb; elektrische Leistung zur Berechnung eines momentan möglichen";
CM_ SG_ 2463978666 MO_EM1_Max_Spannung_Lim "maximal zulässige HV-Spannung (DC), die von der LE im generatorischen Betrieb nicht überschritten werden darf; Abregelspannung zur Begrenzung des minimalen Moments im generatorischen Betrieb";
CM_ SG_ 2463978666 MO_EM1_Min_Leistung_Gesamt "vom Gesamtsystem aufnehmbare elektrische Leistung für den generatorischen Betrieb (betragsmäßig maximal aber i.d.R. negativ, daher ‚Min‘); elektrische Leistung zur Berechnung eines momentan möglichen minimalen Moments (maximal genaratorisch)";
CM_ SG_ 2463978666 MO_EM1_Min_Spannung_Lim "minimal zulässige HV-Spannung (DC), die von der LE im motorischen Betrieb nicht unterschritten werden darf; Abregelspannung zur Begrenzung des maximalen Moments im motorischen Betrieb";
CM_ SG_ 2463978666 MO_EM2_Generator_Leistung "elektrische Wunschleistung zur Berechnung eines momentan erforderlichen Moments im Generatorbetrieb";
CM_ SG_ 2463978666 MO_EM2_Max_Leistung_Gesamt "im Gesamtsystem verfügbare elektrische Leistung für den motorischen Betrieb; elektrische Leistung zur Berechnung eines momentan möglichen";
CM_ SG_ 2463978666 MO_EM2_Max_Spannung_Lim "maximal zulässige HV-Spannung (DC), die von der LE im generatorischen Betrieb nicht überschritten werden darf; Abregelspannung zur Begrenzung des minimalen Moments im generatorischen Betrieb";
CM_ SG_ 2463978666 MO_EM2_Min_Leistung_Gesamt "vom Gesamtsystem aufnehmbare elektrische Leistung für den generatorischen Betrieb (betragsmäßig maximal aber i.d.R. negativ, daher ‚Min‘); elektrische Leistung zur Berechnung eines momentan möglichen minimalen Moments (maximal genaratorisch)";
CM_ SG_ 2463978666 MO_EM2_Min_Spannung_Lim "minimal zulässige HV-Spannung (DC), die von der LE im motorischen Betrieb nicht unterschritten werden darf; Abregelspannung zur Begrenzung des maximalen Moments im motorischen Betrieb";
CM_ SG_ 2463978666 MO_Rekuperation_EM_Ges_Ueberlauf "Rekuperationleistungssignal mindest 1x übergelaufen";
CM_ SG_ 2463978666 MO_Rekuperation_Ges_EM "Rekuperation-Energie des Antriebs";
CM_ SG_ 2463978666 MO_TNW_Max_Spannung_Lim "maximal zulässige HV-Spannung (DC), die vom TNW (Traktionsnetzwandler) im generatorischen Betrieb nicht überschritten werden darf";
CM_ SG_ 2463978666 MO_TNW_Min_Spannung_Lim "minimal zulässige HV-Spannung (DC), die von dem TNW (Traktionsnetzwandler) im motorischen Betrieb nicht unterschritten werden darf";
CM_ SG_ 2463978666 MO_Uebersetzung_EM "Übersetzung von MO_Drehzahl_EM zur Primärachse, wenn eine Verbindung sicher hergestellt ist";
CM_ SG_ 2463978666 MO_Uebersetzung_EM_sek "Übersetzung von MO_Drehzahl_EM_sek zur Sekundärachse, wenn eine Verbindung sicher hergestellt ist";
CM_ SG_ 2463978666 MO_Verbrauch_EM_Ges "Antriebs-Energie des Antriebs";
CM_ SG_ 2463978666 MO_Verbrauch_EM_Ges_Ueberlauf "Verbrauchssignal mindest 1x übergelaufen";
CM_ SG_ 2463978666 Motor_57_BZ "4bit Botschaftszähler, wird mit jeder Sendebotschaft inkrementiert";
CM_ SG_ 2463978666 Motor_57_CRC "Für MLB:
Berechnung siehe Lastenheft 'Kommunikationsabsicherung für FlexRay und CAN'
Ab MQB und MLBevo:
Berechnung siehe Lastenheft 'End-to-End Kommunikationsabsicherung'

Endwerte siehe Begleitdokument 'S-PDU Kennungsfolgen'";

CM_ SG_ 2331595982 PTHyDrA_PrctUtilElDrv "Display for Fahrer Information Display, that shows the utilization in percent of the electric drive system. When full the combustion engine shall start.";
CM_ SG_ 2331595982 PTHyDrA_StAcv "Status-Information Assistent für elektrisches Fahren";
CM_ SG_ 2331595982 PTUIPwrm_FacPwrDyn "Dynamik-Faktor für die anzuzeigende momentane relative Systemleistung im Powermeter";
CM_ SG_ 2331595982 PTUIPwrm_PrctBoostAvl "Anzuzeigende relative Verfügbarkeit des Boost.";
CM_ SG_ 2331595982 PTUIPwrm_PrctPwrEcoMaxUse "relative verfügbare und ökologisch klassifizierte Vortriebs-Leistung des Gesamtantriebs";
CM_ SG_ 2331595982 PTUIPwrm_PrctPwrElBoostCur "Anzuzeigende momentane relative Leistung des Boost";
CM_ SG_ 2331595982 PTUIPwrm_PrctPwrElBoostMaxUse "Anzuzeigende relative nutzbare Leistung des Boost.";
CM_ SG_ 2331595982 PTUIPwrm_PrctPwrElDrvCur "Anzuzeigende momentane relative Leistung des elektrischen Antriebs im Powermeter";
CM_ SG_ 2331595982 PTUIPwrm_PrctPwrGnrMaxUse "Anzuzeigende relative nutzbare generatorische Leistung im Powermeter";
CM_ SG_ 2331595982 PTUIPwrm_PrctPwrMotElMaxUse "Anzuzeigende relative nutzbare motorische Leistung des elektr. Antriebs im Powermeter";
CM_ SG_ 2331595982 PTUIPwrm_PrctPwrMotMaxUse "Anzuzeigende relative nutzbare motorische Leistung im Powermeter";
CM_ SG_ 2331595982 PTUIPwrm_PrctPwrSysCur "Anzuzeigende momentane relative Systemleistung im Powermeter";
CM_ SG_ 2331595982 PTUIPwrm_PrctPwrSysMaxUseTemp "relative kurzzeitig verfügbare Vortriebs-Leistung des Gesamtantriebs";
CM_ SG_ 2331595982 PTUIPwrm_PwrElBoostNom "nominelle Boost-Leistung des elektrischen Antriebs";
CM_ SG_ 2331595982 PTUIPwrm_StAcv "Status-Information Powermeter";

CM_ SG_ 2589283946 PTUIPwrm_PwrGnrNom "nominelle Verzögerungs-Leistung des elektrischen Antriebs ";
CM_ SG_ 2589283946 PTUIPwrm_PwrMotElNom "nominelle Vortriebs-Leistung des elektrischen Antriebs";
CM_ SG_ 2589283946 PTUIPwrm_PwrSysMotNomDisp "nominelle Vortriebs-Leistung des Gesamtantriebs";

CM_ SG_ 2589284069 MO_Aschebeladung_OPF "Dieses Signal zeigt die Beladung des OPFs mit Asche an.";
CM_ SG_ 2589284069 MO_Beladungsstufe_OPF "Dieses Signal zeigt die Beladungsstufe des OPFs an.";
CM_ SG_ 2589284069 MO_Modellbeladung_OPF "Dieses Signal zeigt die ermittelte OPF-Beladung an.";
CM_ SG_ 2589284069 MO_Offset_Nockenwelle1 "Offset zwischen Nockenwelle 1 und Kurbelwelle auf Basis Druck 1.";
CM_ SG_ 2589284069 MO_Offset_Nockenwelle2 "Offset zwischen Nockenwelle 2 und Kurbelwelle auf Basis Druck 2.";
CM_ SG_ 2589284069 MO_Sensorbeladung_OPF "Dieses Signal zeigt die mittels Sensor erkannte Beladung des OPFs an.";

CM_ SG_ 1601 MO_Ansaugsystem "Art des Ansaugsystems des Verbrennungsmotors";
CM_ SG_ 1601 MO_Anzahl_Zyl "Zylinderzahl des Verbrennungsmotors";
CM_ SG_ 1601 MO_Anzeige_StSt_gueltig "Zeigt die Gültigkeit der neuen StSt-Anzeigesignale an, MO_Anzeige_StSt_Text und  MO_Anzeige_Symbol. Mo_Text_Motorstart 1..5 sind zu ignorieren.";
CM_ SG_ 1601 MO_Code "Motorcodierinformation Version 16 (Details siehe Anhang)";
CM_ SG_ 1601 MO_DPF_verbaut "Verbauinformation Diesel-Partikel-Filter
";
CM_ SG_ 1601 MO_Faktor_Momente_02 "Dieses Signal schaltet den Wertebereich aller Momente vom Motor, Getriebe, TSK, Bremse ... um! Die Momente besitzen somit einen variablen Wertebereich, weil sich durch den Faktor die Momente sowohl in Auflösung als auch Maximalwerten ändert.

0x0 nicht ";
CM_ SG_ 1601 MO_Getriebe_Code "Getriebecodierung des Motors";
CM_ SG_ 1601 MO_Hubraum "Hubraum des Verbrennungsmotors";
CM_ SG_ 1601 MO_Hybridfahrzeug "Anhand dieses Signals plausibilisiert die Lenkhilfe das Bit Fahrbereitschaft.

Im Projekt Cayenne PHEV (und ggf. auch VW526 PHEV) ist aus Gründen der Abwärtskompatibilität der Wert '2' zu senden.";
CM_ SG_ 1601 MO_Kraftstoffart "Primärkraftstoff zum Antrieb des Fahrzeugs";
CM_ SG_ 1601 MO_Leistung "Nennleistung des Verbrennungsmotors

Im reinen E-Fahrzeug (BEV): Ausgabe der elektrischen Systemleistung";
CM_ SG_ 1601 MO_OBD_Typ "Abgastyp OBD
Hinweis: In Fahrzeugen mit dem Zielmarkt China und einer Zertifizierung ab China 6 muss auf dem Signal 'MO_OBD_Typ' der Wert 'US_OBD' gesendet werden.";
CM_ SG_ 1601 MO_StartStopp_Codiert "Funktion StartStopp im aktuellen Klemmenzyklus verbaut";
CM_ SG_ 1601 Motor_Code_01_CRC "Für MLB:
'Berechnung siehe Lastenheft 'Kommunikationsabsicherung für FlexRay und CAN''

Ab MQB und MLBevo:
'Berechnung siehe Lastenheft 'End-to-End Kommunikationsabsicherung''

Endwerte siehe Begleitdokument 'S-PDU Kennungsfolgen'";
CM_ SG_ 1601 TSK_Codierung "Information über den plausibilisierten Codierungszustand des Triebstrangskoordinators auf ACC oder GRA.";

CM_ SG_ 391 EV_Rekuperationsstufe "Im Kombi anzuzeigende Rekuperationsstufe";
CM_ SG_ 391 MO_Drehzahl_VM "Motordrehzahl des Verbrennungsmotors

für OBD freeze frame

Hinweis: 
Ehemaliger Fehlerwert 0xFFFF wird senderseitig nicht unterstützt. 
Diesen Wert aus Kompatibilitätsgründen nicht neu belegen!";
CM_ SG_ 391 MO_Fehler_Notabschaltung_Klima "Das Signal dient der schnellen Abschaltung der Klimakomponenten (EKK, HV-Heizung) durch den HV-Koordinator (MSG) nach einem HV-Interlock Ereignis.";
CM_ SG_ 391 MO_Fehler_NTKreis "Fehlerstatus Niedertemperaturkreis";
CM_ SG_ 391 MO_KLE_FStatus "Fehlerstatus der Kühlerlüfterelektronik";
CM_ SG_ 391 MO_Tankbereitschaft_Status "Meldung der Tankbereitschaft";
CM_ SG_ 391 MO_Tankklappensteuerung "Ansteuerungsanforderung der Tankklappe";
CM_ SG_ 391 MO_Waehlpos "Wählhebelposition (im VW120/7 und MQB BEV ist der Wählhebel am HCAN mit Master Motor-SG angeschlossen)

(wenn das Signal zusätzlich in Botschaft MSG_HYB_03 verortet ist, gilt: Signal nur in der CAN-Welt PQ35/25 zu verwenden, da dort am ACAN die Wählhebe";
CM_ SG_ 391 MO_WH_Texte "Fahrerhinweise für das Kombi";
CM_ SG_ 391 Motor_EV_01_BZ "Fehlende Beschreibung (Import)";
CM_ SG_ 391 Motor_EV_01_CRC "Für MLB:
'Berechnung siehe Lastenheft 'Kommunikationsabsicherung für FlexRay und CAN''

Ab MQB und MLBevo:
'Berechnung siehe Lastenheft 'End-to-End Kommunikationsabsicherung''

Endwerte siehe Begleitdokument 'S-PDU Kennungsfolgen'";

CM_ SG_ 813 MO_akt_Betrieb "Motor läuft aktuell im Benzin- oder Gasbetrieb";
CM_ SG_ 813 MO_AnzeigeGasbetrieb "Anzeige des Betriebszustands bei Umschaltung zwischen Gas- und Benzinbetrieb";
CM_ SG_ 813 MO_CNG_Tankstopp "Der CNG-Tankalgorithmus hat einen Tankstopp (CNG-Tank) erkannt.
Bei separatem CNG-SG gatet das MSG die Information.";
CM_ SG_ 813 MO_CNG_Ueberlauf "Der motorsteuergeräteinterne Verbrauchszähler ist mindestens einmal übergelaufen. Dieses Bit wird genutzt, um erkennen zu können, dass das Motorsteuergerät aus dem Reset-Zustand hochläuft.";
CM_ SG_ 813 MO_Erdgasqualitaet "Erdgas-Qualität abgestuft in 70%, 80%, 90% und 100% (bei CNG bezogen auf 100% Methan). Berechnung erfolgt einmalig nach jeder Betankungserkennung.";
CM_ SG_ 813 MO_Fuellstand_LPG "Tankfüllstand LPG (Sensor am MSG/LPG-SG)";
CM_ SG_ 813 MO_Fuellungsgrad_CNG "Gefilterter temperaturkompensierter Gasdruckwert als Prozentwert vom Maximalwert wird im Kombi als Zeiger dargestellt.";
CM_ SG_ 813 MO_Fuellungsgrad_LPG "Füllungsgrad des LPG-Tanks in %";
CM_ SG_ 813 MO_LPG_Tankstopp "Der LPG-Tankalgorithmus hat einen Tankstopp (LPG-Tank) erkannt.
Bei separatem LPG-SG gatet das MSG die Information.";
CM_ SG_ 813 MO_LPG_Ueberlauf "Der motorsteuergeräteinterne Verbrauchszähler ist mindestens einmal übergelaufen. Dieses Bit wird genutzt, um erkennen zu können, dass das Motorsteuergerät aus dem Reset-Zustand hochläuft.";
CM_ SG_ 813 MO_Tankmasse_CNG "Max. Tankmasse in kg bei einem Tankdruck von 200bar, in Abhängigkeit vom max. Tankvolumen und der CNG-Tanktemperatur beim Befüllen (Verwendung im Kombi zur Reichweitenberechnung)";
CM_ SG_ 813 MO_Tankvolumen_LPG "Volumen des LPG-Tanks";
CM_ SG_ 813 MO_Verbrauch_CNG "Motorsteuergeräteinterner Verbrauchszähler, der vom Kombi zyklisch ausgelesen wird, um die Gasmenge zur Verbrauchsberechnung aufzusummieren; aus diesem Zählerstand werden Momentan- und Durchschnittsverbrauch berechnet; das Überlauf-Bit ist zu berücksichti";
CM_ SG_ 813 MO_Verbrauch_LPG "Motorsteuergeräteinterner Verbrauchszähler, der vom Kombi zyklisch ausgelesen wird, um die Gasmenge zur Verbrauchsberechnung aufzusummieren; aus diesem Zählerstand werden Momentan- und Durchschnittsverbrauch berechnet; das Überlauf-Bit ist zu berücksichti";
CM_ SG_ 813 MO_Verbrauchsaequivalent "Faktor zur Umrechnung des aktuellen/letzten Verbrauchs im LPG/CNG-Betrieb auf einen äquivalenten Benzin-Verbrauch (zur Ermittlung der Gesamtreichweite)";

CM_ SG_ 1155 MO_Powermeter_Charge_Grenze "Zeigt eine Einschränkung der Rekuperationsleistung an
";
CM_ SG_ 1155 Mo_Powermeter_Grenze "Anzeige des verfügbaren Powermeterstands im Kombi. Bei EV Unterscheidung zwischen Boost- und Dauerbereich, bei HEV für die Zustartgrenze nutzber";
CM_ SG_ 1155 MO_Powermeter_Grenze_strategisch "Zeigt eine strategische Leistungsbeschränkung des Antriebs, 
zum Beispiel kein Boost im Efficiency Modus";
CM_ SG_ 1155 MO_Powermeter_Inszenierung_aktiv "Mit Hilfe des Signals kann eine Dynamikabfahrt für den Kunden inszeniert werden. Die Inszenierung wird im Powermeter des Kombi-Instruments verortet.";
CM_ SG_ 1155 MO_Powermeter_obere_E_Grenze "Zeigt die obere Grenze für das elektrische Fahren an";
CM_ SG_ 1155 MO_Powermeter_untere_E_Grenze "Zeigt die untere Grenze für das elektrische Fahren an";

CM_ SG_ 2589284112 MO_VTD_CDEODT_L "zurückgelegte Strecke insg. im Betrieb bei Entladung bei abgeschaltetem Motor

(Vehicle Tracking Data:Total distance traveled in charge depleting operation with engine off (Lifetime))";
CM_ SG_ 2589284112 MO_VTD_TD_L "zurückgelegte Strecke insgesamt

(Vehicle Tracking Data:Total Distance Traveled (Lifetime))";

CM_ SG_ 2589284113 SOK_Motor_VTD_01_Signatur "Signatur im Rahmen der durch SOK geschützten Broadcast-Kommunikation

Geschützte Funktion: PHEV
Geschützte Botschaft: Motor_VTD_01";

CM_ SG_ 2589284114 MO_VTD_CDERDT_L "zurückgelegte Strecke insg. im Betrieb bei Entladung bei eingeschaltetem Motor

(Vehicle Tracking Data: Total distance traveled in charge depleting operation with engine running (Lifetime))";
CM_ SG_ 2589284114 MO_VTD_CDFC_L "Kraftstoffverbrauch insgesamt im Betrieb bei Entladung

(Vehicle Tracking Data: Total fuel consumed in charge depleting operation (Lifetime))";

CM_ SG_ 2589284115 SOK_Motor_VTD_02_Signatur "Signatur im Rahmen der durch SOK geschützten Broadcast-Kommunikation

Geschützte Funktion: PHEV
Geschützte Botschaft: Motor_VTD_02";

CM_ SG_ 2589284116 MO_VTD_CIDT_L "zurückgelegte Strecke insg. im vom Fahrer wählbaren Betrieb der Ladungserhöhung

(Vehicle Tracking Data: Total distance traveled in driver-selectable charge increasing operation (Lifetime))";
CM_ SG_ 2589284116 MO_VTD_GE_L "der Batterie zugeführte Netzenergie insgesamt

(Vehicle Tracking Data: Total grid energy into the battery (Lifetime))";

CM_ SG_ 2589284117 SOK_Motor_VTD_03_Signatur "Signatur im Rahmen der durch SOK geschützten Broadcast-Kommunikation

Geschützte Funktion: PHEV
Geschützte Botschaft: Motor_VTD_03";

CM_ SG_ 2589284118 MO_VTD_CIFC_L "Kraftstoffverbrauch insgesamt im vom Fahrer wählbaren Betrieb der Ladungserhöhung.

(Vehicle Tracking Data: Total fuel consumed in driver-selectable charge increasing operation (Lifetime))";
CM_ SG_ 2589284118 MO_VTD_FC_L "Kraftstoffverbrauch insgesamt

(Vehicle Tracking Data: Total fuel consumed (Lifetime))";

CM_ SG_ 2589284119 SOK_Motor_VTD_04_Signatur "Signatur im Rahmen der durch SOK geschützten Broadcast-Kommunikation

Geschützte Funktion: PHEV
Geschützte Botschaft: Motor_VTD_04";
BA_DEF_REL_ BU_SG_REL_  "GenSigTimeoutTime" INT 0 65535;
BA_DEF_ BO_  "DiagRequest" ENUM "No", "Yes";
BA_DEF_ BO_  "DiagResponse" ENUM "No", "Yes";
BA_DEF_ BO_  "DiagState" ENUM "No", "Yes";
BA_DEF_ BO_  "GenMsgChkConstant" HEX 0 4095;
BA_DEF_ BO_  "GenMsgCycleTime" INT 0 65535;
BA_DEF_ BO_  "GenMsgCycleTimeFast" INT 0 65535;
BA_DEF_ BO_  "GenMsgDelayTime" INT 0 100000;
BA_DEF_ BO_  "GenMsgILSupport" ENUM "No", "Yes";
BA_DEF_ BO_  "GenMsgNrOfRepetition" INT 0 100;
BA_DEF_ BO_  "GenMsgPDUConstants" STRING;
BA_DEF_ BO_  "GenMsgSendType" ENUM "Cyclic", "not_used", "not_used", "not_used", "not_used", "not_used", "not_used", "IfActive", "NoMsgSendType";
BA_DEF_ BO_  "GenMsgStartDelayTime" INT 0 100000;
BA_DEF_ BO_  "NmMessage" ENUM "No", "Yes";
BA_DEF_ BO_  "NmhMessage" ENUM "No", "Yes";
BA_DEF_ BO_  "MsgType" ENUM "Application", "NM ", "NMH", "TP2.0", "ISO-TP ", "BAP", "EID", "KS", "XCP_PRE_CONFIGURED", "XCP_RUNTIME_CONFIGURED";
BA_DEF_ BO_  "VAGTP20_API" HEX 0 255;
BA_DEF_ BO_  "VAGTP20_DynConnection" ENUM "No", "Yes";
BA_DEF_ BO_  "VAGTP20_DynSetup" ENUM "No", "Yes";
BA_DEF_ BO_  "VAGTP20_StatConnection" ENUM "No", "Yes";
BA_DEF_ BO_  "CANFD_BRS" ENUM "0", "1";
BA_DEF_ BO_  "VFrameFormat" ENUM "StandardCAN", "ExtendedCAN", "reserved", "reserved", "reserved", "reserved", "reserved", "reserved", "reserved", "reserved", "reserved", "reserved", "reserved", "reserved", "StandardCAN_FD", "ExtendedCAN_FD";
BA_DEF_ SG_  "GenSigActiveRepetitions" INT -2147483648 2147483647;
BA_DEF_ SG_  "GenSigInactiveValue" INT -2147483648 2147483647;
BA_DEF_ SG_  "GenSigSendType" ENUM "Cyclic", "OnWrite", "OnWriteWithRepetition", "OnChange", "OnChangeWithRepetition", "IfActive", "IfActiveWithRepetition", "NoSigSendType", "OnChangeAndIfActive", "OnChangeAndIfActiveWithRepetition";
BA_DEF_ SG_  "GenSigStartValue" INT -2147483648 2147483647;
BA_DEF_ SG_  "NWM-WakeupAllowed" ENUM "No", "Yes";
BA_DEF_ SG_  "GenSigFuncType" ENUM "NoFunction", "MsgCounter", "CRC-8", "XOR", "XOR-2", "DatedBit", "SW-Kl15", "CHK", "Constant", "Protocol", "CRC-8-SAE_J1850", "CRC-32", "DataLength", "DataID", "MsgCounter16", "SOK-Signatur", "Cluster";
BA_DEF_ SG_  "GenSigSwitchedByIgnition" ENUM "No", "Yes";
BA_DEF_ SG_  "Fehlerwert" HEX 0 2147483647;
BA_DEF_ SG_  "GenSigMissingSourceValue" HEX 0 2147483647;
BA_DEF_DEF_REL_  "GenSigTimeoutTime" 0;
BA_DEF_DEF_  "DiagRequest" "No";
BA_DEF_DEF_  "DiagResponse" "No";
BA_DEF_DEF_  "DiagState" "No";
BA_DEF_DEF_  "GenMsgChkConstant" 0;
BA_DEF_DEF_  "GenMsgCycleTime" 0;
BA_DEF_DEF_  "GenMsgCycleTimeFast" 0;
BA_DEF_DEF_  "GenMsgDelayTime" 0;
BA_DEF_DEF_  "GenMsgILSupport" "No";
BA_DEF_DEF_  "GenMsgNrOfRepetition" 0;
BA_DEF_DEF_  "GenMsgPDUConstants" "";
BA_DEF_DEF_  "GenMsgSendType" "NoMsgSendType";
BA_DEF_DEF_  "GenMsgStartDelayTime" 0;
BA_DEF_DEF_  "NmMessage" "No";
BA_DEF_DEF_  "NmhMessage" "No";
BA_DEF_DEF_  "MsgType" "Application";
BA_DEF_DEF_  "VAGTP20_API" 0;
BA_DEF_DEF_  "VAGTP20_DynConnection" "No";
BA_DEF_DEF_  "VAGTP20_DynSetup" "No";
BA_DEF_DEF_  "VAGTP20_StatConnection" "No";
BA_DEF_DEF_  "CANFD_BRS" "1";
BA_DEF_DEF_  "VFrameFormat" "StandardCAN";
BA_DEF_DEF_  "GenSigActiveRepetitions" 0;
BA_DEF_DEF_  "GenSigInactiveValue" 0;
BA_DEF_DEF_  "GenSigSendType" "NoSigSendType";
BA_DEF_DEF_  "GenSigStartValue" 0;
BA_DEF_DEF_  "NWM-WakeupAllowed" "No";
BA_DEF_DEF_  "GenSigFuncType" "NoFunction";
BA_DEF_DEF_  "GenSigSwitchedByIgnition" "Yes";
BA_DEF_DEF_  "Fehlerwert" 0;
BA_DEF_DEF_  "GenSigMissingSourceValue" 0;
BA_ "GenMsgCycleTime" BO_ 267 20;
BA_ "GenMsgILSupport" BO_ 267 1;
BA_ "GenMsgPDUConstants" BO_ 267 "0x2c,0xb1,0x1a,0x75,0xbb,0x65,0x79,0x47,0x81,0x2b,0xcc,0x96,0x17,0xdb,0xc0,0x94";
BA_ "GenMsgSendType" BO_ 267 0;
BA_ "VFrameFormat" BO_ 267 14;
BA_ "GenMsgCycleTime" BO_ 330 20;
BA_ "GenMsgILSupport" BO_ 330 1;
BA_ "GenMsgSendType" BO_ 330 0;
BA_ "VFrameFormat" BO_ 330 14;
BA_ "GenMsgCycleTime" BO_ 512 50;
BA_ "GenMsgILSupport" BO_ 512 1;
BA_ "GenMsgSendType" BO_ 512 0;
BA_ "VFrameFormat" BO_ 512 14;
BA_ "GenMsgCycleTime" BO_ 332 100;
BA_ "GenMsgDelayTime" BO_ 332 10;
BA_ "GenMsgILSupport" BO_ 332 1;
BA_ "GenMsgPDUConstants" BO_ 332 "0x16,0x35,0x59,0x15,0x9a,0x2a,0x97,0xb8,0x0e,0x4e,0x30,0xcc,0xb3,0x07,0x01,0xad";
BA_ "GenMsgSendType" BO_ 332 0;
BA_ "VFrameFormat" BO_ 332 14;
BA_ "GenMsgCycleTime" BO_ 553 100;
BA_ "GenMsgDelayTime" BO_ 553 10;
BA_ "GenMsgSendType" BO_ 553 0;
BA_ "VFrameFormat" BO_ 553 14;
BA_ "GenMsgCycleTime" BO_ 246 10;
BA_ "GenMsgILSupport" BO_ 246 1;
BA_ "GenMsgPDUConstants" BO_ 246 "0xd4,0x37,0x91,0x7d,0x5f,0xf3,0xbc,0xa9,0xd2,0x18,0x96,0x46,0xf8,0x6d,0xf5,0x4d";
BA_ "GenMsgSendType" BO_ 246 0;
BA_ "VFrameFormat" BO_ 246 14;
BA_ "GenMsgCycleTime" BO_ 190 10;
BA_ "GenMsgILSupport" BO_ 190 1;
BA_ "GenMsgPDUConstants" BO_ 190 "0x18,0x71,0x10,0x8d,0xd7,0xaa,0xb0,0x78,0xac,0x12,0xae,0x0c,0xdd,0xf1,0x85,0x68";
BA_ "GenMsgSendType" BO_ 190 0;
BA_ "VFrameFormat" BO_ 190 14;
BA_ "GenMsgCycleTime" BO_ 2463978666 100;
BA_ "GenMsgILSupport" BO_ 2463978666 1;
BA_ "GenMsgPDUConstants" BO_ 2463978666 "0x4a,0x1b,0x16,0x0a,0x24,0x35,0xf8,0x1f,0x59,0x60,0x3b,0x15,0xaa,0xe5,0x9a,0x2e";
BA_ "GenMsgSendType" BO_ 2463978666 0;
BA_ "VFrameFormat" BO_ 2463978666 15;
BA_ "GenMsgCycleTime" BO_ 2331595982 50;
BA_ "GenMsgILSupport" BO_ 2331595982 1;
BA_ "GenMsgSendType" BO_ 2331595982 0;
BA_ "VFrameFormat" BO_ 2331595982 15;
BA_ "GenMsgCycleTime" BO_ 2589283946 500;
BA_ "GenMsgILSupport" BO_ 2589283946 1;
BA_ "GenMsgSendType" BO_ 2589283946 0;
BA_ "VFrameFormat" BO_ 2589283946 15;
BA_ "GenMsgCycleTime" BO_ 2589284069 2000;
BA_ "GenMsgILSupport" BO_ 2589284069 1;
BA_ "GenMsgSendType" BO_ 2589284069 0;
BA_ "VFrameFormat" BO_ 2589284069 15;
BA_ "GenMsgChkConstant" BO_ 1601 71;
BA_ "GenMsgCycleTime" BO_ 1601 1000;
BA_ "GenMsgILSupport" BO_ 1601 1;
BA_ "GenMsgPDUConstants" BO_ 1601 "0x47,0x47,0x47,0x47,0x47,0x47,0x47,0x47,0x47,0x47,0x47,0x47,0x47,0x47,0x47,0x47";
BA_ "GenMsgSendType" BO_ 1601 0;
BA_ "VFrameFormat" BO_ 1601 14;
BA_ "GenMsgCycleTime" BO_ 391 100;
BA_ "GenMsgDelayTime" BO_ 391 40;
BA_ "GenMsgILSupport" BO_ 391 1;
BA_ "GenMsgPDUConstants" BO_ 391 "0x7f,0xed,0x17,0xc2,0x7c,0xeb,0x44,0x21,0x01,0xfa,0xdb,0x15,0x4a,0x6b,0x23,0x05";
BA_ "GenMsgSendType" BO_ 391 0;
BA_ "VFrameFormat" BO_ 391 14;
BA_ "GenMsgCycleTime" BO_ 813 50;
BA_ "GenMsgILSupport" BO_ 813 1;
BA_ "GenMsgSendType" BO_ 813 0;
BA_ "VFrameFormat" BO_ 813 14;
BA_ "GenMsgCycleTime" BO_ 1155 500;
BA_ "GenMsgDelayTime" BO_ 1155 50;
BA_ "GenMsgILSupport" BO_ 1155 1;
BA_ "GenMsgSendType" BO_ 1155 0;
BA_ "VFrameFormat" BO_ 1155 14;
BA_ "GenMsgCycleTime" BO_ 2589284112 2000;
BA_ "GenMsgILSupport" BO_ 2589284112 1;
BA_ "GenMsgSendType" BO_ 2589284112 0;
BA_ "VFrameFormat" BO_ 2589284112 15;
BA_ "GenMsgCycleTime" BO_ 2589284113 2000;
BA_ "GenMsgSendType" BO_ 2589284113 0;
BA_ "VFrameFormat" BO_ 2589284113 15;
BA_ "GenMsgCycleTime" BO_ 2589284114 2000;
BA_ "GenMsgILSupport" BO_ 2589284114 1;
BA_ "GenMsgSendType" BO_ 2589284114 0;
BA_ "VFrameFormat" BO_ 2589284114 15;
BA_ "GenMsgCycleTime" BO_ 2589284115 2000;
BA_ "GenMsgSendType" BO_ 2589284115 0;
BA_ "VFrameFormat" BO_ 2589284115 15;
BA_ "GenMsgCycleTime" BO_ 2589284116 2000;
BA_ "GenMsgILSupport" BO_ 2589284116 1;
BA_ "GenMsgSendType" BO_ 2589284116 0;
BA_ "VFrameFormat" BO_ 2589284116 15;
BA_ "GenMsgCycleTime" BO_ 2589284117 2000;
BA_ "GenMsgSendType" BO_ 2589284117 0;
BA_ "VFrameFormat" BO_ 2589284117 15;
BA_ "GenMsgCycleTime" BO_ 2589284118 2000;
BA_ "GenMsgILSupport" BO_ 2589284118 1;
BA_ "GenMsgSendType" BO_ 2589284118 0;
BA_ "VFrameFormat" BO_ 2589284118 15;
BA_ "GenMsgCycleTime" BO_ 2589284119 2000;
BA_ "GenMsgSendType" BO_ 2589284119 0;
BA_ "VFrameFormat" BO_ 2589284119 15;
BA_ "GenMsgILSupport" BO_ 16 1;
BA_ "VFrameFormat" BO_ 16 14;
BA_ "GenMsgILSupport" BO_ 22 1;
BA_ "VFrameFormat" BO_ 22 14;
BA_ "GenMsgILSupport" BO_ 24 1;
BA_ "VFrameFormat" BO_ 24 14;
BA_ "GenSigSendType" SG_ 267 MO_Entkopplung_Sollschlupf 0;
BA_ "GenSigStartValue" SG_ 267 MO_Entkopplung_Sollschlupf 126;
BA_ "GenSigSwitchedByIgnition" SG_ 267 MO_Entkopplung_Sollschlupf 0;
BA_ "GenSigSendType" SG_ 267 MO_Fahrpedalgradient 0;
BA_ "GenSigSwitchedByIgnition" SG_ 267 MO_Fahrpedalgradient 0;
BA_ "Fehlerwert" SG_ 267 MO_Fahrpedalgradient 255;
BA_ "GenSigSendType" SG_ 267 MO_Fahrpedalrohwert_01 0;
BA_ "GenSigSwitchedByIgnition" SG_ 267 MO_Fahrpedalrohwert_01 0;
BA_ "Fehlerwert" SG_ 267 MO_Fahrpedalrohwert_01 255;
BA_ "GenSigSendType" SG_ 267 MO_Moment_im_Leerlauf 0;
BA_ "GenSigSwitchedByIgnition" SG_ 267 MO_Moment_im_Leerlauf 0;
BA_ "GenSigSendType" SG_ 267 MO_QBit_Fahrpedalwerte_01 0;
BA_ "GenSigStartValue" SG_ 267 MO_QBit_Fahrpedalwerte_01 1;
BA_ "GenSigSwitchedByIgnition" SG_ 267 MO_QBit_Fahrpedalwerte_01 0;
BA_ "GenSigSendType" SG_ 267 MO_rel_Saugrohrdruck 0;
BA_ "GenSigSwitchedByIgnition" SG_ 267 MO_rel_Saugrohrdruck 0;
BA_ "Fehlerwert" SG_ 267 MO_rel_Saugrohrdruck 63;
BA_ "GenSigSendType" SG_ 267 MO_rel_Saugrohrdruck_gem_err 0;
BA_ "GenSigSwitchedByIgnition" SG_ 267 MO_rel_Saugrohrdruck_gem_err 0;
BA_ "GenSigSendType" SG_ 267 MO_Schubabschaltung 0;
BA_ "GenSigSwitchedByIgnition" SG_ 267 MO_Schubabschaltung 0;
BA_ "GenSigSendType" SG_ 267 MO_Sig_Fahrpedalgradient 0;
BA_ "GenSigSwitchedByIgnition" SG_ 267 MO_Sig_Fahrpedalgradient 0;
BA_ "GenSigSendType" SG_ 267 MO_Solldrehz_Leerlauf 0;
BA_ "GenSigSwitchedByIgnition" SG_ 267 MO_Solldrehz_Leerlauf 0;
BA_ "GenSigSendType" SG_ 267 MO_StartStopp_StoppVorbereitung 0;
BA_ "GenSigSwitchedByIgnition" SG_ 267 MO_StartStopp_StoppVorbereitung 0;
BA_ "GenSigSendType" SG_ 267 MO_Status_MaxDrzEingriff 0;
BA_ "GenSigSwitchedByIgnition" SG_ 267 MO_Status_MaxDrzEingriff 0;
BA_ "GenSigSendType" SG_ 267 MO_Status_MaxDrzEingriff_sek 0;
BA_ "GenSigSwitchedByIgnition" SG_ 267 MO_Status_MaxDrzEingriff_sek 0;
BA_ "GenSigSendType" SG_ 267 MO_Status_MinDrzEingriff 0;
BA_ "GenSigSwitchedByIgnition" SG_ 267 MO_Status_MinDrzEingriff 0;
BA_ "GenSigSendType" SG_ 267 MO_Status_MinDrzEingriff_sek 0;
BA_ "GenSigSwitchedByIgnition" SG_ 267 MO_Status_MinDrzEingriff_sek 0;
BA_ "GenSigSendType" SG_ 267 MO_temporaere_Fahrerabwesenheit 0;
BA_ "GenSigSwitchedByIgnition" SG_ 267 MO_temporaere_Fahrerabwesenheit 0;
BA_ "GenSigSendType" SG_ 267 Motor_51_BZ 0;
BA_ "GenSigFuncType" SG_ 267 Motor_51_BZ 1;
BA_ "GenSigSwitchedByIgnition" SG_ 267 Motor_51_BZ 0;
BA_ "GenSigSendType" SG_ 267 Motor_51_CRC 0;
BA_ "GenSigFuncType" SG_ 267 Motor_51_CRC 2;
BA_ "GenSigSwitchedByIgnition" SG_ 267 Motor_51_CRC 0;
BA_ "GenSigSendType" SG_ 267 SOK_Motor_51_Signatur 0;
BA_ "GenSigFuncType" SG_ 267 SOK_Motor_51_Signatur 15;
BA_ "GenSigSendType" SG_ 267 TSK_a_Soll_gradientenbegrenzt 0;
BA_ "GenSigStartValue" SG_ 267 TSK_a_Soll_gradientenbegrenzt 127;
BA_ "GenSigSwitchedByIgnition" SG_ 267 TSK_a_Soll_gradientenbegrenzt 0;
BA_ "GenSigSendType" SG_ 267 TSK_ax_Getriebe_02 0;
BA_ "GenSigStartValue" SG_ 267 TSK_ax_Getriebe_02 511;
BA_ "GenSigSwitchedByIgnition" SG_ 267 TSK_ax_Getriebe_02 0;
BA_ "GenSigSendType" SG_ 267 TSK_Freig_Verzoeg_Anf 0;
BA_ "GenSigSwitchedByIgnition" SG_ 267 TSK_Freig_Verzoeg_Anf 0;
BA_ "GenSigSendType" SG_ 267 TSK_Hauptschalter_GRA_ACC 0;
BA_ "GenSigSwitchedByIgnition" SG_ 267 TSK_Hauptschalter_GRA_ACC 0;
BA_ "Fehlerwert" SG_ 267 TSK_Hauptschalter_GRA_ACC 3;
BA_ "GenSigSendType" SG_ 267 TSK_Kategorie_Verzoegerungsfkt 0;
BA_ "GenSigSwitchedByIgnition" SG_ 267 TSK_Kategorie_Verzoegerungsfkt 0;
BA_ "GenSigSendType" SG_ 267 TSK_Limiter_ausgewaehlt 0;
BA_ "GenSigSwitchedByIgnition" SG_ 267 TSK_Limiter_ausgewaehlt 0;
BA_ "GenSigSendType" SG_ 267 TSK_Notstopp_Anf 0;
BA_ "GenSigSwitchedByIgnition" SG_ 267 TSK_Notstopp_Anf 0;
BA_ "GenSigSendType" SG_ 267 TSK_Radbremsmom 0;
BA_ "GenSigSwitchedByIgnition" SG_ 267 TSK_Radbremsmom 0;
BA_ "GenSigSendType" SG_ 267 TSK_Radsollmoment 0;
BA_ "GenSigStartValue" SG_ 267 TSK_Radsollmoment 65534;
BA_ "GenSigSwitchedByIgnition" SG_ 267 TSK_Radsollmoment 0;
BA_ "Fehlerwert" SG_ 267 TSK_Radsollmoment 65535;
BA_ "GenSigSendType" SG_ 267 TSK_SRBM_Anf_ASIL 0;
BA_ "GenSigSwitchedByIgnition" SG_ 267 TSK_SRBM_Anf_ASIL 0;
BA_ "GenSigSendType" SG_ 267 TSK_SRBM_max_Gradient 0;
BA_ "GenSigStartValue" SG_ 267 TSK_SRBM_max_Gradient 126;
BA_ "GenSigSwitchedByIgnition" SG_ 267 TSK_SRBM_max_Gradient 0;
BA_ "Fehlerwert" SG_ 267 TSK_SRBM_max_Gradient 127;
BA_ "GenSigSendType" SG_ 267 TSK_Standby_Anf_ESP 0;
BA_ "GenSigSwitchedByIgnition" SG_ 267 TSK_Standby_Anf_ESP 0;
BA_ "GenSigSendType" SG_ 267 TSK_Status 0;
BA_ "GenSigStartValue" SG_ 267 TSK_Status 1;
BA_ "GenSigSwitchedByIgnition" SG_ 267 TSK_Status 0;
BA_ "GenSigSendType" SG_ 267 TSK_v_Begrenzung_aktiv 0;
BA_ "GenSigSwitchedByIgnition" SG_ 267 TSK_v_Begrenzung_aktiv 0;
BA_ "GenSigSendType" SG_ 267 TSK_zul_Regelabw 0;
BA_ "GenSigSwitchedByIgnition" SG_ 267 TSK_zul_Regelabw 0;
BA_ "GenSigSendType" SG_ 267 TSK_Zwangszusch_ESP 0;
BA_ "GenSigSwitchedByIgnition" SG_ 267 TSK_Zwangszusch_ESP 0;
BA_ "GenSigSendType" SG_ 330 Ladezustand_02 0;
BA_ "GenSigStartValue" SG_ 330 Ladezustand_02 254;
BA_ "GenSigSwitchedByIgnition" SG_ 330 Ladezustand_02 0;
BA_ "Fehlerwert" SG_ 330 Ladezustand_02 255;
BA_ "GenSigSendType" SG_ 330 Ladezustand_gering 0;
BA_ "GenSigSwitchedByIgnition" SG_ 330 Ladezustand_gering 0;
BA_ "GenSigSendType" SG_ 330 Ladezustand_kritisch 0;
BA_ "GenSigSwitchedByIgnition" SG_ 330 Ladezustand_kritisch 0;
BA_ "GenSigSendType" SG_ 330 MO_Anzeige_Drehmoment 0;
BA_ "GenSigSwitchedByIgnition" SG_ 330 MO_Anzeige_Drehmoment 0;
BA_ "Fehlerwert" SG_ 330 MO_Anzeige_Drehmoment 2047;
BA_ "GenSigSendType" SG_ 330 MO_Anzeige_Leistung 0;
BA_ "GenSigSwitchedByIgnition" SG_ 330 MO_Anzeige_Leistung 0;
BA_ "Fehlerwert" SG_ 330 MO_Anzeige_Leistung 2047;
BA_ "GenSigSendType" SG_ 330 MO_Anzeige_Verbr_Einheit 0;
BA_ "GenSigSwitchedByIgnition" SG_ 330 MO_Anzeige_Verbr_Einheit 0;
BA_ "GenSigSendType" SG_ 330 MO_Anzeigedrehz 0;
BA_ "GenSigSwitchedByIgnition" SG_ 330 MO_Anzeigedrehz 0;
BA_ "GenSigSendType" SG_ 330 MO_Effizienzmodus 0;
BA_ "GenSigSwitchedByIgnition" SG_ 330 MO_Effizienzmodus 0;
BA_ "GenSigSendType" SG_ 330 MO_ePerformance 0;
BA_ "GenSigSwitchedByIgnition" SG_ 330 MO_ePerformance 0;
BA_ "Fehlerwert" SG_ 330 MO_ePerformance 255;
BA_ "GenSigSendType" SG_ 330 MO_ePowermeter 0;
BA_ "GenSigSwitchedByIgnition" SG_ 330 MO_ePowermeter 0;
BA_ "GenSigSendType" SG_ 330 MO_Fehler_Oeldrucksensor 0;
BA_ "GenSigSwitchedByIgnition" SG_ 330 MO_Fehler_Oeldrucksensor 0;
BA_ "Fehlerwert" SG_ 330 MO_Fehler_Oeldrucksensor 1;
BA_ "GenSigSendType" SG_ 330 MO_Hochschaltdrehz 0;
BA_ "GenSigSwitchedByIgnition" SG_ 330 MO_Hochschaltdrehz 0;
BA_ "Fehlerwert" SG_ 330 MO_Hochschaltdrehz 4095;
BA_ "GenSigSendType" SG_ 330 MO_Istgang 0;
BA_ "GenSigSwitchedByIgnition" SG_ 330 MO_Istgang 0;
BA_ "GenSigSendType" SG_ 330 MO_KVS 0;
BA_ "GenSigSwitchedByIgnition" SG_ 330 MO_KVS 0;
BA_ "GenSigSendType" SG_ 330 MO_KVS_Ueberlauf 0;
BA_ "GenSigSwitchedByIgnition" SG_ 330 MO_KVS_Ueberlauf 0;
BA_ "GenSigSendType" SG_ 330 MO_Ladedruck 0;
BA_ "GenSigSwitchedByIgnition" SG_ 330 MO_Ladedruck 0;
BA_ "Fehlerwert" SG_ 330 MO_Ladedruck 511;
BA_ "GenSigSendType" SG_ 330 MO_Oeldruck 0;
BA_ "GenSigStartValue" SG_ 330 MO_Oeldruck 254;
BA_ "GenSigSwitchedByIgnition" SG_ 330 MO_Oeldruck 0;
BA_ "Fehlerwert" SG_ 330 MO_Oeldruck 255;
BA_ "GenSigSendType" SG_ 330 MO_OnePedalDriving_Warnung 0;
BA_ "GenSigSwitchedByIgnition" SG_ 330 MO_OnePedalDriving_Warnung 0;
BA_ "GenSigSendType" SG_ 330 MO_Powermeter 0;
BA_ "GenSigStartValue" SG_ 330 MO_Powermeter 4093;
BA_ "GenSigSwitchedByIgnition" SG_ 330 MO_Powermeter 0;
BA_ "GenSigSendType" SG_ 330 MO_Powermeter_Elm_02 0;
BA_ "GenSigStartValue" SG_ 330 MO_Powermeter_Elm_02 4094;
BA_ "GenSigSwitchedByIgnition" SG_ 330 MO_Powermeter_Elm_02 0;
BA_ "GenSigSendType" SG_ 330 MO_rel_Ladedruck 0;
BA_ "GenSigSwitchedByIgnition" SG_ 330 MO_rel_Ladedruck 0;
BA_ "Fehlerwert" SG_ 330 MO_rel_Ladedruck 255;
BA_ "GenSigSendType" SG_ 330 MO_Schaltblitz_Anz 0;
BA_ "GenSigStartValue" SG_ 330 MO_Schaltblitz_Anz 126;
BA_ "GenSigSwitchedByIgnition" SG_ 330 MO_Schaltblitz_Anz 0;
BA_ "Fehlerwert" SG_ 330 MO_Schaltblitz_Anz 127;
BA_ "GenSigSendType" SG_ 330 MO_Schaltempf_verfbar 0;
BA_ "GenSigSwitchedByIgnition" SG_ 330 MO_Schaltempf_verfbar 0;
BA_ "GenSigSendType" SG_ 330 MO_Sollgang 0;
BA_ "GenSigSwitchedByIgnition" SG_ 330 MO_Sollgang 0;
BA_ "GenSigSendType" SG_ 330 MO_Zust_Antrieb 0;
BA_ "GenSigSwitchedByIgnition" SG_ 330 MO_Zust_Antrieb 0;
BA_ "GenSigSendType" SG_ 330 MO_Zust_Betriebsstrategie 0;
BA_ "GenSigSwitchedByIgnition" SG_ 330 MO_Zust_Betriebsstrategie 0;
BA_ "GenSigSendType" SG_ 512 CE_CtrPrpPrep 0;
BA_ "GenSigStartValue" SG_ 512 CE_CtrPrpPrep 7;
BA_ "GenSigSwitchedByIgnition" SG_ 512 CE_CtrPrpPrep 0;
BA_ "GenSigSendType" SG_ 512 CE_FlgEmiColdLmp 0;
BA_ "GenSigSwitchedByIgnition" SG_ 512 CE_FlgEmiColdLmp 0;
BA_ "GenSigSendType" SG_ 512 CE_FlgEmiColdTxt 0;
BA_ "GenSigSwitchedByIgnition" SG_ 512 CE_FlgEmiColdTxt 0;
BA_ "GenSigSendType" SG_ 512 CE_FlgHybModAdvi 0;
BA_ "GenSigSwitchedByIgnition" SG_ 512 CE_FlgHybModAdvi 0;
BA_ "GenSigSendType" SG_ 512 CE_FlgPTLimPrfTxt 0;
BA_ "GenSigSwitchedByIgnition" SG_ 512 CE_FlgPTLimPrfTxt 0;
BA_ "GenSigSendType" SG_ 512 CE_PrctPrpPrep 0;
BA_ "GenSigStartValue" SG_ 512 CE_PrctPrpPrep 126;
BA_ "Fehlerwert" SG_ 512 CE_PrctPrpPrep 127;
BA_ "GenSigSendType" SG_ 512 CE_StLdRdcEmiSysPrep 0;
BA_ "GenSigStartValue" SG_ 512 CE_StLdRdcEmiSysPrep 6;
BA_ "Fehlerwert" SG_ 512 CE_StLdRdcEmiSysPrep 7;
BA_ "GenSigSendType" SG_ 512 CE_StStrtDlyEmiSysPrep 0;
BA_ "GenSigStartValue" SG_ 512 CE_StStrtDlyEmiSysPrep 2;
BA_ "Fehlerwert" SG_ 512 CE_StStrtDlyEmiSysPrep 3;
BA_ "GenSigSendType" SG_ 512 ISA_Tempolimit_Regelung 0;
BA_ "GenSigSwitchedByIgnition" SG_ 512 ISA_Tempolimit_Regelung 0;
BA_ "GenSigSendType" SG_ 512 MO_Antriebsstrang_Warnung_HS 0;
BA_ "GenSigSwitchedByIgnition" SG_ 512 MO_Antriebsstrang_Warnung_HS 0;
BA_ "GenSigSendType" SG_ 512 MO_Anzeige_Betriebsmodus 0;
BA_ "GenSigSwitchedByIgnition" SG_ 512 MO_Anzeige_Betriebsmodus 0;
BA_ "GenSigSendType" SG_ 512 MO_Anzeige_Fahrbereitschaft 0;
BA_ "GenSigSwitchedByIgnition" SG_ 512 MO_Anzeige_Fahrbereitschaft 0;
BA_ "GenSigSendType" SG_ 512 MO_Anzeige_Rekuperation 0;
BA_ "GenSigSwitchedByIgnition" SG_ 512 MO_Anzeige_Rekuperation 0;
BA_ "GenSigSendType" SG_ 512 MO_Anzeige_Verbrauch_oE 0;
BA_ "GenSigSwitchedByIgnition" SG_ 512 MO_Anzeige_Verbrauch_oE 0;
BA_ "GenSigSendType" SG_ 512 MO_Boost_aktiv 0;
BA_ "GenSigSwitchedByIgnition" SG_ 512 MO_Boost_aktiv 0;
BA_ "GenSigSendType" SG_ 512 MO_Boost_verfuegbar 0;
BA_ "GenSigSwitchedByIgnition" SG_ 512 MO_Boost_verfuegbar 0;
BA_ "Fehlerwert" SG_ 512 MO_Boost_verfuegbar 255;
BA_ "GenSigSendType" SG_ 512 MO_BZS_Charisma_FahrPr 0;
BA_ "GenSigSwitchedByIgnition" SG_ 512 MO_BZS_Charisma_FahrPr 0;
BA_ "GenSigSendType" SG_ 512 MO_BZS_Charisma_Status 0;
BA_ "GenSigSwitchedByIgnition" SG_ 512 MO_BZS_Charisma_Status 0;
BA_ "GenSigSendType" SG_ 512 MO_Charisma_FahrPr 0;
BA_ "GenSigSwitchedByIgnition" SG_ 512 MO_Charisma_FahrPr 0;
BA_ "GenSigSendType" SG_ 512 MO_Charisma_Status 0;
BA_ "GenSigSwitchedByIgnition" SG_ 512 MO_Charisma_Status 0;
BA_ "GenSigSendType" SG_ 512 MO_Drehzahlbeeinflussung 0;
BA_ "GenSigSwitchedByIgnition" SG_ 512 MO_Drehzahlbeeinflussung 0;
BA_ "GenSigSendType" SG_ 512 MO_Kuehlmitttel_Sensor_AGB2 0;
BA_ "GenSigSwitchedByIgnition" SG_ 512 MO_Kuehlmitttel_Sensor_AGB2 0;
BA_ "GenSigSendType" SG_ 512 MO_Luftpfad_aktiv 0;
BA_ "GenSigSwitchedByIgnition" SG_ 512 MO_Luftpfad_aktiv 0;
BA_ "GenSigSendType" SG_ 512 MO_MAX_Wunschdrehzahl 0;
BA_ "GenSigSwitchedByIgnition" SG_ 512 MO_MAX_Wunschdrehzahl 0;
BA_ "GenSigSendType" SG_ 512 MO_MIN_Wunschdrehzahl 0;
BA_ "GenSigSwitchedByIgnition" SG_ 512 MO_MIN_Wunschdrehzahl 0;
BA_ "GenSigSendType" SG_ 512 MO_Motorlaufwarnung 0;
BA_ "GenSigSwitchedByIgnition" SG_ 512 MO_Motorlaufwarnung 0;
BA_ "GenSigSendType" SG_ 512 MO_NGS_Position 0;
BA_ "GenSigSwitchedByIgnition" SG_ 512 MO_NGS_Position 0;
BA_ "GenSigSendType" SG_ 512 MO_NGS_Status 0;
BA_ "GenSigSwitchedByIgnition" SG_ 512 MO_NGS_Status 0;
BA_ "Fehlerwert" SG_ 512 MO_NGS_Status 3;
BA_ "GenSigSendType" SG_ 512 MO_Overboost 0;
BA_ "GenSigSwitchedByIgnition" SG_ 512 MO_Overboost 0;
BA_ "GenSigSendType" SG_ 512 MO_Prio_MAX_Wunschdrehzahl 0;
BA_ "GenSigSwitchedByIgnition" SG_ 512 MO_Prio_MAX_Wunschdrehzahl 0;
BA_ "GenSigSendType" SG_ 512 MO_Prio_MIN_Wunschdrehzahl 0;
BA_ "GenSigSwitchedByIgnition" SG_ 512 MO_Prio_MIN_Wunschdrehzahl 0;
BA_ "GenSigSendType" SG_ 512 MO_Rampenzeit_Generator_Anf 0;
BA_ "GenSigStartValue" SG_ 512 MO_Rampenzeit_Generator_Anf 15;
BA_ "GenSigSwitchedByIgnition" SG_ 512 MO_Rampenzeit_Generator_Anf 0;
BA_ "GenSigSendType" SG_ 512 MO_Sperrung_FahrPr_BZS 0;
BA_ "GenSigSwitchedByIgnition" SG_ 512 MO_Sperrung_FahrPr_BZS 0;
BA_ "GenSigSendType" SG_ 512 MO_StSt_Charisma_FahrPr 0;
BA_ "GenSigSwitchedByIgnition" SG_ 512 MO_StSt_Charisma_FahrPr 0;
BA_ "GenSigSendType" SG_ 512 MO_StSt_Charisma_Status 0;
BA_ "GenSigSwitchedByIgnition" SG_ 512 MO_StSt_Charisma_Status 0;
BA_ "GenSigSendType" SG_ 512 MO_Text_Aktivierung_Antrieb 0;
BA_ "GenSigStartValue" SG_ 512 MO_Text_Aktivierung_Antrieb 15;
BA_ "GenSigSwitchedByIgnition" SG_ 512 MO_Text_Aktivierung_Antrieb 0;
BA_ "GenSigSendType" SG_ 512 MO_v_Begrenz_Aktivierbar 0;
BA_ "GenSigSwitchedByIgnition" SG_ 512 MO_v_Begrenz_Aktivierbar 0;
BA_ "GenSigSendType" SG_ 512 MO_v_Begrenzung_Niveau 0;
BA_ "GenSigSwitchedByIgnition" SG_ 512 MO_v_Begrenzung_Niveau 0;
BA_ "GenSigSendType" SG_ 512 PEA_Abschalttexte 0;
BA_ "GenSigSwitchedByIgnition" SG_ 512 PEA_Abschalttexte 0;
BA_ "GenSigSendType" SG_ 512 PEA_Ereignisanzeige 0;
BA_ "GenSigSwitchedByIgnition" SG_ 512 PEA_Ereignisanzeige 0;
BA_ "GenSigSendType" SG_ 512 PEA_Ereignisanzeige_temporaer 0;
BA_ "GenSigSwitchedByIgnition" SG_ 512 PEA_Ereignisanzeige_temporaer 0;
BA_ "GenSigSendType" SG_ 512 PEA_Fahrerinfo 0;
BA_ "GenSigSwitchedByIgnition" SG_ 512 PEA_Fahrerinfo 0;
BA_ "GenSigSendType" SG_ 512 PEA_Fortschrittsanzeige 0;
BA_ "GenSigStartValue" SG_ 512 PEA_Fortschrittsanzeige 127;
BA_ "GenSigSwitchedByIgnition" SG_ 512 PEA_Fortschrittsanzeige 0;
BA_ "GenSigSendType" SG_ 512 PEA_Hinweis 0;
BA_ "GenSigSwitchedByIgnition" SG_ 512 PEA_Hinweis 0;
BA_ "GenSigSendType" SG_ 512 PEA_Zielgeschw 0;
BA_ "GenSigSwitchedByIgnition" SG_ 512 PEA_Zielgeschw 0;
BA_ "GenSigSendType" SG_ 512 PEA_Zielgeschw_Einheit 0;
BA_ "GenSigSwitchedByIgnition" SG_ 512 PEA_Zielgeschw_Einheit 0;
BA_ "GenSigSendType" SG_ 512 TSK_Akustik 0;
BA_ "GenSigSwitchedByIgnition" SG_ 512 TSK_Akustik 0;
BA_ "GenSigSendType" SG_ 512 TSK_Fahrzeugstatus_GRA 0;
BA_ "GenSigSwitchedByIgnition" SG_ 512 TSK_Fahrzeugstatus_GRA 0;
BA_ "GenSigSendType" SG_ 512 TSK_Fahrzeugstatus_Limiter 0;
BA_ "GenSigSwitchedByIgnition" SG_ 512 TSK_Fahrzeugstatus_Limiter 0;
BA_ "GenSigSendType" SG_ 512 TSK_Fahrzeugstatus_praed_Fkt 0;
BA_ "GenSigSwitchedByIgnition" SG_ 512 TSK_Fahrzeugstatus_praed_Fkt 0;
BA_ "GenSigSendType" SG_ 512 TSK_Limiter_Anzeige 0;
BA_ "GenSigSwitchedByIgnition" SG_ 512 TSK_Limiter_Anzeige 0;
BA_ "GenSigSendType" SG_ 512 TSK_Limiter_Fahrerinfo 0;
BA_ "GenSigSwitchedByIgnition" SG_ 512 TSK_Limiter_Fahrerinfo 0;
BA_ "GenSigSendType" SG_ 512 TSK_naechstes_Event 0;
BA_ "GenSigSwitchedByIgnition" SG_ 512 TSK_naechstes_Event 0;
BA_ "GenSigSendType" SG_ 512 TSK_naechstes_Event_Einheit 0;
BA_ "GenSigSwitchedByIgnition" SG_ 512 TSK_naechstes_Event_Einheit 0;
BA_ "GenSigSendType" SG_ 512 TSK_praed_Wunschgeschw 0;
BA_ "GenSigStartValue" SG_ 512 TSK_praed_Wunschgeschw 1022;
BA_ "GenSigSwitchedByIgnition" SG_ 512 TSK_praed_Wunschgeschw 0;
BA_ "GenSigSendType" SG_ 512 TSK_praediktiver_Automode 0;
BA_ "GenSigSwitchedByIgnition" SG_ 512 TSK_praediktiver_Automode 0;
BA_ "GenSigSendType" SG_ 512 TSK_praediktiver_Hinweis 0;
BA_ "GenSigSwitchedByIgnition" SG_ 512 TSK_praediktiver_Hinweis 0;
BA_ "GenSigSendType" SG_ 512 TSK_Status_Anzeige 0;
BA_ "GenSigStartValue" SG_ 512 TSK_Status_Anzeige 1;
BA_ "GenSigSwitchedByIgnition" SG_ 512 TSK_Status_Anzeige 0;
BA_ "GenSigSendType" SG_ 512 TSK_Texte 0;
BA_ "GenSigSwitchedByIgnition" SG_ 512 TSK_Texte 0;
BA_ "GenSigSendType" SG_ 512 TSK_Texte_Primaeranz 0;
BA_ "GenSigSwitchedByIgnition" SG_ 512 TSK_Texte_Primaeranz 0;
BA_ "GenSigSendType" SG_ 512 TSK_Wunschgeschw 0;
BA_ "GenSigSwitchedByIgnition" SG_ 512 TSK_Wunschgeschw 0;
BA_ "GenSigSendType" SG_ 332 CE_FlgLnchCtlPreCnd 0;
BA_ "GenSigSwitchedByIgnition" SG_ 332 CE_FlgLnchCtlPreCnd 0;
BA_ "GenSigSendType" SG_ 332 FoD_DTC_TSK_ACC 0;
BA_ "GenSigSwitchedByIgnition" SG_ 332 FoD_DTC_TSK_ACC 0;
BA_ "GenSigSendType" SG_ 332 FoD_DTC_TSK_GRA 0;
BA_ "GenSigSwitchedByIgnition" SG_ 332 FoD_DTC_TSK_GRA 0;
BA_ "GenSigSendType" SG_ 332 ISA_Regelung_aktiv 3;
BA_ "GenSigSwitchedByIgnition" SG_ 332 ISA_Regelung_aktiv 0;
BA_ "GenSigSendType" SG_ 332 ISA_Status 3;
BA_ "GenSigStartValue" SG_ 332 ISA_Status 1;
BA_ "GenSigSwitchedByIgnition" SG_ 332 ISA_Status 0;
BA_ "GenSigSendType" SG_ 332 ISA_Tempolimitwarnung 3;
BA_ "GenSigSwitchedByIgnition" SG_ 332 ISA_Tempolimitwarnung 0;
BA_ "GenSigSendType" SG_ 332 MO_Anforderung_HMS 3;
BA_ "GenSigSwitchedByIgnition" SG_ 332 MO_Anforderung_HMS 0;
BA_ "GenSigSendType" SG_ 332 MO_EBoost_verf_praed 0;
BA_ "GenSigSwitchedByIgnition" SG_ 332 MO_EBoost_verf_praed 0;
BA_ "GenSigSendType" SG_ 332 MO_eLaunch_verf 0;
BA_ "GenSigSwitchedByIgnition" SG_ 332 MO_eLaunch_verf 0;
BA_ "GenSigSendType" SG_ 332 MO_EMG_Max_Leistung 0;
BA_ "GenSigStartValue" SG_ 332 MO_EMG_Max_Leistung 2046;
BA_ "GenSigSwitchedByIgnition" SG_ 332 MO_EMG_Max_Leistung 0;
BA_ "Fehlerwert" SG_ 332 MO_EMG_Max_Leistung 2047;
BA_ "GenSigSendType" SG_ 332 MO_EMG_Min_Leistung 0;
BA_ "GenSigStartValue" SG_ 332 MO_EMG_Min_Leistung 2046;
BA_ "GenSigSwitchedByIgnition" SG_ 332 MO_EMG_Min_Leistung 0;
BA_ "Fehlerwert" SG_ 332 MO_EMG_Min_Leistung 2047;
BA_ "GenSigSendType" SG_ 332 MO_Fahrbereitschaft 3;
BA_ "GenSigSwitchedByIgnition" SG_ 332 MO_Fahrbereitschaft 0;
BA_ "GenSigSendType" SG_ 332 MO_Freilauf_Info 3;
BA_ "GenSigSwitchedByIgnition" SG_ 332 MO_Freilauf_Info 0;
BA_ "GenSigSendType" SG_ 332 MO_Freilauf_Status 3;
BA_ "GenSigSwitchedByIgnition" SG_ 332 MO_Freilauf_Status 0;
BA_ "Fehlerwert" SG_ 332 MO_Freilauf_Status 7;
BA_ "GenSigSendType" SG_ 332 MO_Heckspoiler_Anf 0;
BA_ "GenSigSwitchedByIgnition" SG_ 332 MO_Heckspoiler_Anf 0;
BA_ "GenSigSendType" SG_ 332 MO_Klima_Regelmodus 0;
BA_ "GenSigSwitchedByIgnition" SG_ 332 MO_Klima_Regelmodus 0;
BA_ "GenSigSendType" SG_ 332 MO_Krit_Heckobjekt 0;
BA_ "GenSigSwitchedByIgnition" SG_ 332 MO_Krit_Heckobjekt 0;
BA_ "Fehlerwert" SG_ 332 MO_Krit_Heckobjekt 7;
BA_ "GenSigSendType" SG_ 332 MO_Kuppl_betaetigt 3;
BA_ "GenSigSwitchedByIgnition" SG_ 332 MO_Kuppl_betaetigt 0;
BA_ "GenSigSendType" SG_ 332 MO_LaunchControl 0;
BA_ "GenSigSwitchedByIgnition" SG_ 332 MO_LaunchControl 0;
BA_ "GenSigSendType" SG_ 332 MO_MVEM_MaxLeistung_MVVerbrauch 0;
BA_ "GenSigStartValue" SG_ 332 MO_MVEM_MaxLeistung_MVVerbrauch 1022;
BA_ "GenSigSwitchedByIgnition" SG_ 332 MO_MVEM_MaxLeistung_MVVerbrauch 0;
BA_ "Fehlerwert" SG_ 332 MO_MVEM_MaxLeistung_MVVerbrauch 1023;
BA_ "GenSigSendType" SG_ 332 MO_MVEM_MinLeistung_MVVerbrauch 0;
BA_ "GenSigStartValue" SG_ 332 MO_MVEM_MinLeistung_MVVerbrauch 1022;
BA_ "GenSigSwitchedByIgnition" SG_ 332 MO_MVEM_MinLeistung_MVVerbrauch 0;
BA_ "Fehlerwert" SG_ 332 MO_MVEM_MinLeistung_MVVerbrauch 1023;
BA_ "GenSigSendType" SG_ 332 MO_NGS_Gangpos 3;
BA_ "GenSigSwitchedByIgnition" SG_ 332 MO_NGS_Gangpos 0;
BA_ "Fehlerwert" SG_ 332 MO_NGS_Gangpos 7;
BA_ "GenSigSendType" SG_ 332 MO_Positionierung_aktiv 0;
BA_ "GenSigSwitchedByIgnition" SG_ 332 MO_Positionierung_aktiv 0;
BA_ "GenSigSendType" SG_ 332 MO_QBit_Aussen_Temp 0;
BA_ "GenSigStartValue" SG_ 332 MO_QBit_Aussen_Temp 1;
BA_ "GenSigSwitchedByIgnition" SG_ 332 MO_QBit_Aussen_Temp 0;
BA_ "GenSigSendType" SG_ 332 MO_QBit_Kuppl_betaetigt 3;
BA_ "GenSigSwitchedByIgnition" SG_ 332 MO_QBit_Kuppl_betaetigt 0;
BA_ "GenSigSendType" SG_ 332 MO_Red_El_Fahrleistung 0;
BA_ "GenSigSwitchedByIgnition" SG_ 332 MO_Red_El_Fahrleistung 0;
BA_ "GenSigSendType" SG_ 332 MO_Servicemodus 0;
BA_ "GenSigSwitchedByIgnition" SG_ 332 MO_Servicemodus 0;
BA_ "GenSigSendType" SG_ 332 MO_Startwunsch 3;
BA_ "GenSigSwitchedByIgnition" SG_ 332 MO_Startwunsch 0;
BA_ "GenSigSendType" SG_ 332 MO_UBE_Hybrid_Reserve 0;
BA_ "GenSigStartValue" SG_ 332 MO_UBE_Hybrid_Reserve 1023;
BA_ "GenSigSwitchedByIgnition" SG_ 332 MO_UBE_Hybrid_Reserve 0;
BA_ "GenSigSendType" SG_ 332 MO_UBE_Reserve 0;
BA_ "GenSigStartValue" SG_ 332 MO_UBE_Reserve 1023;
BA_ "GenSigSwitchedByIgnition" SG_ 332 MO_UBE_Reserve 0;
BA_ "GenSigSendType" SG_ 332 MO_Veto_Launchcontrol 0;
BA_ "GenSigSwitchedByIgnition" SG_ 332 MO_Veto_Launchcontrol 0;
BA_ "GenSigSendType" SG_ 332 Motor_54_BZ 0;
BA_ "GenSigFuncType" SG_ 332 Motor_54_BZ 1;
BA_ "GenSigSwitchedByIgnition" SG_ 332 Motor_54_BZ 0;
BA_ "GenSigSendType" SG_ 332 Motor_54_CRC 0;
BA_ "GenSigFuncType" SG_ 332 Motor_54_CRC 2;
BA_ "GenSigSwitchedByIgnition" SG_ 332 Motor_54_CRC 0;
BA_ "GenSigSendType" SG_ 332 OBD_Abs_Load_Val 0;
BA_ "GenSigStartValue" SG_ 332 OBD_Abs_Load_Val 65535;
BA_ "GenSigSwitchedByIgnition" SG_ 332 OBD_Abs_Load_Val 0;
BA_ "GenSigSendType" SG_ 332 OBD_Abs_Pedal_Pos 0;
BA_ "GenSigStartValue" SG_ 332 OBD_Abs_Pedal_Pos 255;
BA_ "GenSigSwitchedByIgnition" SG_ 332 OBD_Abs_Pedal_Pos 0;
BA_ "GenSigSendType" SG_ 332 OBD_Abs_Throttle_Pos 0;
BA_ "GenSigStartValue" SG_ 332 OBD_Abs_Throttle_Pos 255;
BA_ "GenSigSwitchedByIgnition" SG_ 332 OBD_Abs_Throttle_Pos 0;
BA_ "GenSigSendType" SG_ 332 OBD_Aussen_Temp_gef 0;
BA_ "GenSigStartValue" SG_ 332 OBD_Aussen_Temp_gef 254;
BA_ "GenSigSwitchedByIgnition" SG_ 332 OBD_Aussen_Temp_gef 0;
BA_ "Fehlerwert" SG_ 332 OBD_Aussen_Temp_gef 255;
BA_ "GenSigSendType" SG_ 332 OBD_Calc_Load_Val 0;
BA_ "GenSigStartValue" SG_ 332 OBD_Calc_Load_Val 255;
BA_ "GenSigSwitchedByIgnition" SG_ 332 OBD_Calc_Load_Val 0;
BA_ "GenSigSendType" SG_ 332 OBD_ClearMem_Inhibit 0;
BA_ "GenSigSwitchedByIgnition" SG_ 332 OBD_ClearMem_Inhibit 0;
BA_ "GenSigSendType" SG_ 332 OBD_Driving_Cycle 0;
BA_ "GenSigSwitchedByIgnition" SG_ 332 OBD_Driving_Cycle 0;
BA_ "GenSigSendType" SG_ 332 OBD_Eng_Cool_Temp 0;
BA_ "GenSigStartValue" SG_ 332 OBD_Eng_Cool_Temp 255;
BA_ "GenSigSwitchedByIgnition" SG_ 332 OBD_Eng_Cool_Temp 0;
BA_ "GenSigSendType" SG_ 332 OBD_Kaltstart_Denominator 0;
BA_ "GenSigSwitchedByIgnition" SG_ 332 OBD_Kaltstart_Denominator 0;
BA_ "GenSigSendType" SG_ 332 OBD_Minimum_Trip 0;
BA_ "GenSigSwitchedByIgnition" SG_ 332 OBD_Minimum_Trip 0;
BA_ "GenSigSendType" SG_ 332 OBD_Normed_Trip 0;
BA_ "GenSigSwitchedByIgnition" SG_ 332 OBD_Normed_Trip 0;
BA_ "GenSigSendType" SG_ 332 OBD_Sperrung_IUMPR 0;
BA_ "GenSigSwitchedByIgnition" SG_ 332 OBD_Sperrung_IUMPR 0;
BA_ "GenSigSendType" SG_ 332 OBD_Sperrung_Kaltstart_Denom 0;
BA_ "GenSigSwitchedByIgnition" SG_ 332 OBD_Sperrung_Kaltstart_Denom 0;
BA_ "GenSigSendType" SG_ 332 OBD_Warm_Up_Cycle 0;
BA_ "GenSigSwitchedByIgnition" SG_ 332 OBD_Warm_Up_Cycle 0;
BA_ "GenSigSendType" SG_ 332 OBDProtocol_req 0;
BA_ "GenSigSwitchedByIgnition" SG_ 332 OBDProtocol_req 0;
BA_ "Fehlerwert" SG_ 332 OBDProtocol_req 255;
BA_ "GenSigSendType" SG_ 332 TSK_ACC_FoD_Status 0;
BA_ "GenSigSwitchedByIgnition" SG_ 332 TSK_ACC_FoD_Status 0;
BA_ "GenSigSendType" SG_ 332 TSK_aktives_System 3;
BA_ "GenSigSwitchedByIgnition" SG_ 332 TSK_aktives_System 0;
BA_ "GenSigSendType" SG_ 332 TSK_aktives_System_02 3;
BA_ "GenSigSwitchedByIgnition" SG_ 332 TSK_aktives_System_02 0;
BA_ "GenSigSendType" SG_ 332 TSK_Anf_Antriebsmoment 3;
BA_ "GenSigSwitchedByIgnition" SG_ 332 TSK_Anf_Antriebsmoment 0;
BA_ "GenSigSendType" SG_ 332 TSK_Einheit_vMax_Fahrerassistenz 0;
BA_ "GenSigSwitchedByIgnition" SG_ 332 TSK_Einheit_vMax_Fahrerassistenz 0;
BA_ "GenSigSendType" SG_ 332 TSK_erhoehter_Fahrwiderstand 3;
BA_ "GenSigSwitchedByIgnition" SG_ 332 TSK_erhoehter_Fahrwiderstand 0;
BA_ "GenSigSendType" SG_ 332 TSK_GRA_FoD_Status 0;
BA_ "GenSigSwitchedByIgnition" SG_ 332 TSK_GRA_FoD_Status 0;
BA_ "GenSigSendType" SG_ 332 TSK_Status_ARA 3;
BA_ "GenSigStartValue" SG_ 332 TSK_Status_ARA 1;
BA_ "GenSigSwitchedByIgnition" SG_ 332 TSK_Status_ARA 0;
BA_ "Fehlerwert" SG_ 332 TSK_Status_ARA 7;
BA_ "GenSigSendType" SG_ 332 TSK_Status_EA 3;
BA_ "GenSigStartValue" SG_ 332 TSK_Status_EA 1;
BA_ "GenSigSwitchedByIgnition" SG_ 332 TSK_Status_EA 0;
BA_ "Fehlerwert" SG_ 332 TSK_Status_EA 7;
BA_ "GenSigSendType" SG_ 332 TSK_Status_IPA 3;
BA_ "GenSigStartValue" SG_ 332 TSK_Status_IPA 1;
BA_ "GenSigSwitchedByIgnition" SG_ 332 TSK_Status_IPA 0;
BA_ "Fehlerwert" SG_ 332 TSK_Status_IPA 7;
BA_ "GenSigSendType" SG_ 332 TSK_Status_PLA 3;
BA_ "GenSigStartValue" SG_ 332 TSK_Status_PLA 1;
BA_ "GenSigSwitchedByIgnition" SG_ 332 TSK_Status_PLA 0;
BA_ "Fehlerwert" SG_ 332 TSK_Status_PLA 7;
BA_ "GenSigSendType" SG_ 332 TSK_Status_RHP 3;
BA_ "GenSigStartValue" SG_ 332 TSK_Status_RHP 1;
BA_ "GenSigSwitchedByIgnition" SG_ 332 TSK_Status_RHP 0;
BA_ "GenSigSendType" SG_ 332 TSK_vMax_aktuell 0;
BA_ "GenSigStartValue" SG_ 332 TSK_vMax_aktuell 255;
BA_ "GenSigSendType" SG_ 332 TSK_vMax_Fahrerassistenz 0;
BA_ "GenSigStartValue" SG_ 332 TSK_vMax_Fahrerassistenz 511;
BA_ "GenSigSwitchedByIgnition" SG_ 332 TSK_vMax_Fahrerassistenz 0;
BA_ "GenSigSendType" SG_ 553 SOK_Motor_54_Signatur 0;
BA_ "GenSigFuncType" SG_ 553 SOK_Motor_54_Signatur 15;
BA_ "GenSigSwitchedByIgnition" SG_ 553 SOK_Motor_54_Signatur 0;
BA_ "GenSigSendType" SG_ 246 FDR_Allrad_Anteil_max_sek 0;
BA_ "GenSigStartValue" SG_ 246 FDR_Allrad_Anteil_max_sek 510;
BA_ "Fehlerwert" SG_ 246 FDR_Allrad_Anteil_max_sek 511;
BA_ "GenSigSendType" SG_ 246 FDR_Allrad_Anteil_min_sek 0;
BA_ "GenSigStartValue" SG_ 246 FDR_Allrad_Anteil_min_sek 510;
BA_ "Fehlerwert" SG_ 246 FDR_Allrad_Anteil_min_sek 511;
BA_ "GenSigSendType" SG_ 246 FDR_MomRad_Eingriff 0;
BA_ "GenSigStartValue" SG_ 246 FDR_MomRad_Eingriff 8190;
BA_ "GenSigSwitchedByIgnition" SG_ 246 FDR_MomRad_Eingriff 0;
BA_ "Fehlerwert" SG_ 246 FDR_MomRad_Eingriff 8191;
BA_ "GenSigSendType" SG_ 246 FDR_MomRad_Eingriff_sek 0;
BA_ "GenSigStartValue" SG_ 246 FDR_MomRad_Eingriff_sek 8190;
BA_ "GenSigSwitchedByIgnition" SG_ 246 FDR_MomRad_Eingriff_sek 0;
BA_ "Fehlerwert" SG_ 246 FDR_MomRad_Eingriff_sek 8191;
BA_ "GenSigSendType" SG_ 246 FDR_Status_Eingriff 0;
BA_ "GenSigSwitchedByIgnition" SG_ 246 FDR_Status_Eingriff 0;
BA_ "GenSigSendType" SG_ 246 FDR_Status_Eingriff_sek 0;
BA_ "GenSigSwitchedByIgnition" SG_ 246 FDR_Status_Eingriff_sek 0;
BA_ "GenSigSendType" SG_ 246 FDR_Zwangszusch_ESP 0;
BA_ "GenSigSendType" SG_ 246 MO_EMG_Generator_Leistung 0;
BA_ "GenSigStartValue" SG_ 246 MO_EMG_Generator_Leistung 2046;
BA_ "GenSigSwitchedByIgnition" SG_ 246 MO_EMG_Generator_Leistung 0;
BA_ "Fehlerwert" SG_ 246 MO_EMG_Generator_Leistung 2047;
BA_ "GenSigSendType" SG_ 246 MO_EMG_Max_Momentengradient 0;
BA_ "GenSigStartValue" SG_ 246 MO_EMG_Max_Momentengradient 126;
BA_ "GenSigSwitchedByIgnition" SG_ 246 MO_EMG_Max_Momentengradient 0;
BA_ "GenSigSendType" SG_ 246 MO_EMG_Max_Spannung_Lim 0;
BA_ "GenSigStartValue" SG_ 246 MO_EMG_Max_Spannung_Lim 254;
BA_ "GenSigSwitchedByIgnition" SG_ 246 MO_EMG_Max_Spannung_Lim 0;
BA_ "Fehlerwert" SG_ 246 MO_EMG_Max_Spannung_Lim 255;
BA_ "GenSigSendType" SG_ 246 MO_EMG_Max_Strom_Lim 0;
BA_ "GenSigStartValue" SG_ 246 MO_EMG_Max_Strom_Lim 2046;
BA_ "GenSigSwitchedByIgnition" SG_ 246 MO_EMG_Max_Strom_Lim 0;
BA_ "Fehlerwert" SG_ 246 MO_EMG_Max_Strom_Lim 2047;
BA_ "GenSigSendType" SG_ 246 MO_EMG_Min_Spannung_Lim 0;
BA_ "GenSigStartValue" SG_ 246 MO_EMG_Min_Spannung_Lim 254;
BA_ "GenSigSwitchedByIgnition" SG_ 246 MO_EMG_Min_Spannung_Lim 0;
BA_ "Fehlerwert" SG_ 246 MO_EMG_Min_Spannung_Lim 255;
BA_ "GenSigSendType" SG_ 246 MO_EMG_Min_Strom_Lim 0;
BA_ "GenSigStartValue" SG_ 246 MO_EMG_Min_Strom_Lim 2046;
BA_ "GenSigSwitchedByIgnition" SG_ 246 MO_EMG_Min_Strom_Lim 0;
BA_ "Fehlerwert" SG_ 246 MO_EMG_Min_Strom_Lim 2047;
BA_ "GenSigSendType" SG_ 246 MO_EMG_SollDrehzahl 0;
BA_ "GenSigStartValue" SG_ 246 MO_EMG_SollDrehzahl 32767;
BA_ "GenSigSwitchedByIgnition" SG_ 246 MO_EMG_SollDrehzahl 0;
BA_ "GenSigSendType" SG_ 246 MO_EMG_Sollmodus 0;
BA_ "GenSigStartValue" SG_ 246 MO_EMG_Sollmodus 15;
BA_ "GenSigSwitchedByIgnition" SG_ 246 MO_EMG_Sollmodus 0;
BA_ "GenSigSendType" SG_ 246 MO_EMG_SollMoment_02 0;
BA_ "GenSigStartValue" SG_ 246 MO_EMG_SollMoment_02 65534;
BA_ "GenSigSwitchedByIgnition" SG_ 246 MO_EMG_SollMoment_02 0;
BA_ "GenSigSendType" SG_ 246 MO_EMG_Sollspannung 0;
BA_ "GenSigStartValue" SG_ 246 MO_EMG_Sollspannung 254;
BA_ "GenSigSwitchedByIgnition" SG_ 246 MO_EMG_Sollspannung 0;
BA_ "Fehlerwert" SG_ 246 MO_EMG_Sollspannung 255;
BA_ "GenSigSendType" SG_ 246 MO_Mom_Begr_Fahr_Pred 0;
BA_ "GenSigStartValue" SG_ 246 MO_Mom_Begr_Fahr_Pred 510;
BA_ "GenSigSwitchedByIgnition" SG_ 246 MO_Mom_Begr_Fahr_Pred 0;
BA_ "GenSigSendType" SG_ 246 Motor_55_BZ 0;
BA_ "GenSigFuncType" SG_ 246 Motor_55_BZ 1;
BA_ "GenSigSwitchedByIgnition" SG_ 246 Motor_55_BZ 0;
BA_ "GenSigSendType" SG_ 246 Motor_55_CRC 0;
BA_ "GenSigFuncType" SG_ 246 Motor_55_CRC 2;
BA_ "GenSigSwitchedByIgnition" SG_ 246 Motor_55_CRC 0;
BA_ "GenSigSendType" SG_ 246 SOK_Motor_55_Signatur 0;
BA_ "GenSigFuncType" SG_ 246 SOK_Motor_55_Signatur 15;
BA_ "GenSigSendType" SG_ 246 TS_Allrad_Anteil_sek 0;
BA_ "GenSigStartValue" SG_ 246 TS_Allrad_Anteil_sek 510;
BA_ "GenSigSwitchedByIgnition" SG_ 246 TS_Allrad_Anteil_sek 0;
BA_ "Fehlerwert" SG_ 246 TS_Allrad_Anteil_sek 511;
BA_ "GenSigSendType" SG_ 246 TS_Faktor_Radmomente 0;
BA_ "GenSigSwitchedByIgnition" SG_ 246 TS_Faktor_Radmomente 0;
BA_ "GenSigSendType" SG_ 246 TS_MomRad_Ist 0;
BA_ "GenSigStartValue" SG_ 246 TS_MomRad_Ist 8190;
BA_ "GenSigSwitchedByIgnition" SG_ 246 TS_MomRad_Ist 0;
BA_ "GenSigSendType" SG_ 246 TS_MomRad_Ist_sek 0;
BA_ "GenSigStartValue" SG_ 246 TS_MomRad_Ist_sek 8190;
BA_ "GenSigSwitchedByIgnition" SG_ 246 TS_MomRad_Ist_sek 0;
BA_ "GenSigSendType" SG_ 246 TS_MomRad_Soll_Summe 0;
BA_ "GenSigStartValue" SG_ 246 TS_MomRad_Soll_Summe 8190;
BA_ "GenSigSwitchedByIgnition" SG_ 246 TS_MomRad_Soll_Summe 0;
BA_ "GenSigSendType" SG_ 246 TS_MomRad_verfuegb_max 0;
BA_ "GenSigStartValue" SG_ 246 TS_MomRad_verfuegb_max 4094;
BA_ "GenSigSwitchedByIgnition" SG_ 246 TS_MomRad_verfuegb_max 0;
BA_ "GenSigSendType" SG_ 246 TS_MomRad_verfuegb_max_sek 0;
BA_ "GenSigStartValue" SG_ 246 TS_MomRad_verfuegb_max_sek 4094;
BA_ "GenSigSwitchedByIgnition" SG_ 246 TS_MomRad_verfuegb_max_sek 0;
BA_ "GenSigSendType" SG_ 246 TS_MomRad_verfuegb_maxReku 0;
BA_ "GenSigStartValue" SG_ 246 TS_MomRad_verfuegb_maxReku 4094;
BA_ "GenSigSwitchedByIgnition" SG_ 246 TS_MomRad_verfuegb_maxReku 0;
BA_ "GenSigSendType" SG_ 246 TS_MomRad_verfuegb_maxReku_sek 0;
BA_ "GenSigStartValue" SG_ 246 TS_MomRad_verfuegb_maxReku_sek 4094;
BA_ "GenSigSwitchedByIgnition" SG_ 246 TS_MomRad_verfuegb_maxReku_sek 0;
BA_ "GenSigSendType" SG_ 246 TS_MomRad_verfuegb_maxReku_Summe 0;
BA_ "GenSigStartValue" SG_ 246 TS_MomRad_verfuegb_maxReku_Summe 4094;
BA_ "GenSigSwitchedByIgnition" SG_ 246 TS_MomRad_verfuegb_maxReku_Summe 0;
BA_ "GenSigSendType" SG_ 246 TS_MomRad_Wunsch 0;
BA_ "GenSigStartValue" SG_ 246 TS_MomRad_Wunsch 8190;
BA_ "GenSigSwitchedByIgnition" SG_ 246 TS_MomRad_Wunsch 0;
BA_ "GenSigSendType" SG_ 246 TS_MomRad_Wunsch_sek 0;
BA_ "GenSigStartValue" SG_ 246 TS_MomRad_Wunsch_sek 8190;
BA_ "GenSigSwitchedByIgnition" SG_ 246 TS_MomRad_Wunsch_sek 0;
BA_ "GenSigSendType" SG_ 246 TS_Status_DrzReg 0;
BA_ "GenSigSwitchedByIgnition" SG_ 246 TS_Status_DrzReg 0;
BA_ "GenSigSendType" SG_ 246 TS_Status_DrzReg_sek 0;
BA_ "GenSigSwitchedByIgnition" SG_ 246 TS_Status_DrzReg_sek 0;
BA_ "GenSigSendType" SG_ 246 TS_Status_MomRad_Ist 0;
BA_ "GenSigStartValue" SG_ 246 TS_Status_MomRad_Ist 2;
BA_ "GenSigSwitchedByIgnition" SG_ 246 TS_Status_MomRad_Ist 0;
BA_ "GenSigSendType" SG_ 190 MO_CluAxs_Set 0;
BA_ "GenSigSwitchedByIgnition" SG_ 190 MO_CluAxs_Set 0;
BA_ "GenSigSendType" SG_ 190 MO_CluEng_Set 0;
BA_ "GenSigSwitchedByIgnition" SG_ 190 MO_CluEng_Set 0;
BA_ "GenSigSendType" SG_ 190 MO_DC_Max_Strom_HV 0;
BA_ "GenSigStartValue" SG_ 190 MO_DC_Max_Strom_HV 255;
BA_ "GenSigSwitchedByIgnition" SG_ 190 MO_DC_Max_Strom_HV 0;
BA_ "GenSigSendType" SG_ 190 MO_DC_SollSpannung_HV 0;
BA_ "GenSigStartValue" SG_ 190 MO_DC_SollSpannung_HV 255;
BA_ "GenSigSwitchedByIgnition" SG_ 190 MO_DC_SollSpannung_HV 0;
BA_ "GenSigSendType" SG_ 190 MO_EM1_AR_Anf 0;
BA_ "GenSigSwitchedByIgnition" SG_ 190 MO_EM1_AR_Anf 0;
BA_ "GenSigSendType" SG_ 190 MO_EM1_DynLimit_AR 0;
BA_ "GenSigStartValue" SG_ 190 MO_EM1_DynLimit_AR 255;
BA_ "GenSigSwitchedByIgnition" SG_ 190 MO_EM1_DynLimit_AR 0;
BA_ "GenSigSendType" SG_ 190 MO_EM1_Kp_AR 0;
BA_ "GenSigStartValue" SG_ 190 MO_EM1_Kp_AR 511;
BA_ "GenSigSwitchedByIgnition" SG_ 190 MO_EM1_Kp_AR 0;
BA_ "GenSigSendType" SG_ 190 MO_EM1_Max_Leistung 0;
BA_ "GenSigStartValue" SG_ 190 MO_EM1_Max_Leistung 16382;
BA_ "GenSigSwitchedByIgnition" SG_ 190 MO_EM1_Max_Leistung 0;
BA_ "GenSigSendType" SG_ 190 MO_EM1_Max_Moment 0;
BA_ "GenSigStartValue" SG_ 190 MO_EM1_Max_Moment 4094;
BA_ "GenSigSwitchedByIgnition" SG_ 190 MO_EM1_Max_Moment 0;
BA_ "GenSigSendType" SG_ 190 MO_EM1_Max_Strom_Lim 0;
BA_ "GenSigStartValue" SG_ 190 MO_EM1_Max_Strom_Lim 8190;
BA_ "GenSigSwitchedByIgnition" SG_ 190 MO_EM1_Max_Strom_Lim 0;
BA_ "GenSigSendType" SG_ 190 MO_EM1_MaxDrehzahl 0;
BA_ "GenSigStartValue" SG_ 190 MO_EM1_MaxDrehzahl 16383;
BA_ "GenSigSwitchedByIgnition" SG_ 190 MO_EM1_MaxDrehzahl 0;
BA_ "GenSigSendType" SG_ 190 MO_EM1_Min_Leistung 0;
BA_ "GenSigStartValue" SG_ 190 MO_EM1_Min_Leistung 16382;
BA_ "GenSigSwitchedByIgnition" SG_ 190 MO_EM1_Min_Leistung 0;
BA_ "GenSigSendType" SG_ 190 MO_EM1_Min_Moment 0;
BA_ "GenSigStartValue" SG_ 190 MO_EM1_Min_Moment 4094;
BA_ "GenSigSwitchedByIgnition" SG_ 190 MO_EM1_Min_Moment 0;
BA_ "GenSigSendType" SG_ 190 MO_EM1_Min_Strom_Lim 0;
BA_ "GenSigStartValue" SG_ 190 MO_EM1_Min_Strom_Lim 8190;
BA_ "GenSigSwitchedByIgnition" SG_ 190 MO_EM1_Min_Strom_Lim 0;
BA_ "GenSigSendType" SG_ 190 MO_EM1_MinDrehzahl 0;
BA_ "GenSigStartValue" SG_ 190 MO_EM1_MinDrehzahl 16383;
BA_ "GenSigSwitchedByIgnition" SG_ 190 MO_EM1_MinDrehzahl 0;
BA_ "GenSigSendType" SG_ 190 MO_EM1_Periode_AR 0;
BA_ "GenSigStartValue" SG_ 190 MO_EM1_Periode_AR 255;
BA_ "GenSigSwitchedByIgnition" SG_ 190 MO_EM1_Periode_AR 0;
BA_ "GenSigSendType" SG_ 190 MO_EM1_Sollmodus 0;
BA_ "GenSigStartValue" SG_ 190 MO_EM1_Sollmodus 15;
BA_ "GenSigSwitchedByIgnition" SG_ 190 MO_EM1_Sollmodus 0;
BA_ "GenSigSendType" SG_ 190 MO_EM1_SollMoment 0;
BA_ "GenSigStartValue" SG_ 190 MO_EM1_SollMoment 4094;
BA_ "GenSigSwitchedByIgnition" SG_ 190 MO_EM1_SollMoment 0;
BA_ "GenSigSendType" SG_ 190 MO_EM1_SollSpannung 0;
BA_ "GenSigStartValue" SG_ 190 MO_EM1_SollSpannung 4095;
BA_ "GenSigSwitchedByIgnition" SG_ 190 MO_EM1_SollSpannung 0;
BA_ "GenSigSendType" SG_ 190 MO_EM2_AR_Anf 0;
BA_ "GenSigSwitchedByIgnition" SG_ 190 MO_EM2_AR_Anf 0;
BA_ "GenSigSendType" SG_ 190 MO_EM2_DynLimit_AR 0;
BA_ "GenSigStartValue" SG_ 190 MO_EM2_DynLimit_AR 255;
BA_ "GenSigSwitchedByIgnition" SG_ 190 MO_EM2_DynLimit_AR 0;
BA_ "GenSigSendType" SG_ 190 MO_EM2_Kp_AR 0;
BA_ "GenSigStartValue" SG_ 190 MO_EM2_Kp_AR 511;
BA_ "GenSigSwitchedByIgnition" SG_ 190 MO_EM2_Kp_AR 0;
BA_ "GenSigSendType" SG_ 190 MO_EM2_Max_Leistung 0;
BA_ "GenSigStartValue" SG_ 190 MO_EM2_Max_Leistung 16382;
BA_ "GenSigSwitchedByIgnition" SG_ 190 MO_EM2_Max_Leistung 0;
BA_ "GenSigSendType" SG_ 190 MO_EM2_Max_Moment 0;
BA_ "GenSigStartValue" SG_ 190 MO_EM2_Max_Moment 4094;
BA_ "GenSigSwitchedByIgnition" SG_ 190 MO_EM2_Max_Moment 0;
BA_ "Fehlerwert" SG_ 190 MO_EM2_Max_Moment 4095;
BA_ "GenSigSendType" SG_ 190 MO_EM2_Max_Strom_Lim 0;
BA_ "GenSigStartValue" SG_ 190 MO_EM2_Max_Strom_Lim 8190;
BA_ "GenSigSwitchedByIgnition" SG_ 190 MO_EM2_Max_Strom_Lim 0;
BA_ "GenSigSendType" SG_ 190 MO_EM2_MaxDrehzahl 0;
BA_ "GenSigStartValue" SG_ 190 MO_EM2_MaxDrehzahl 16383;
BA_ "GenSigSwitchedByIgnition" SG_ 190 MO_EM2_MaxDrehzahl 0;
BA_ "GenSigSendType" SG_ 190 MO_EM2_Min_Leistung 0;
BA_ "GenSigStartValue" SG_ 190 MO_EM2_Min_Leistung 16382;
BA_ "GenSigSwitchedByIgnition" SG_ 190 MO_EM2_Min_Leistung 0;
BA_ "GenSigSendType" SG_ 190 MO_EM2_Min_Moment 0;
BA_ "GenSigStartValue" SG_ 190 MO_EM2_Min_Moment 4094;
BA_ "GenSigSwitchedByIgnition" SG_ 190 MO_EM2_Min_Moment 0;
BA_ "Fehlerwert" SG_ 190 MO_EM2_Min_Moment 4095;
BA_ "GenSigSendType" SG_ 190 MO_EM2_Min_Strom_Lim 0;
BA_ "GenSigStartValue" SG_ 190 MO_EM2_Min_Strom_Lim 8190;
BA_ "GenSigSwitchedByIgnition" SG_ 190 MO_EM2_Min_Strom_Lim 0;
BA_ "GenSigSendType" SG_ 190 MO_EM2_MinDrehzahl 0;
BA_ "GenSigStartValue" SG_ 190 MO_EM2_MinDrehzahl 16383;
BA_ "GenSigSwitchedByIgnition" SG_ 190 MO_EM2_MinDrehzahl 0;
BA_ "GenSigSendType" SG_ 190 MO_EM2_Periode_AR 0;
BA_ "GenSigStartValue" SG_ 190 MO_EM2_Periode_AR 255;
BA_ "GenSigSwitchedByIgnition" SG_ 190 MO_EM2_Periode_AR 0;
BA_ "GenSigSendType" SG_ 190 MO_EM2_Sollmodus 0;
BA_ "GenSigStartValue" SG_ 190 MO_EM2_Sollmodus 15;
BA_ "GenSigSwitchedByIgnition" SG_ 190 MO_EM2_Sollmodus 0;
BA_ "GenSigSendType" SG_ 190 MO_EM2_SollMoment 0;
BA_ "GenSigStartValue" SG_ 190 MO_EM2_SollMoment 4094;
BA_ "GenSigSwitchedByIgnition" SG_ 190 MO_EM2_SollMoment 0;
BA_ "Fehlerwert" SG_ 190 MO_EM2_SollMoment 4095;
BA_ "GenSigSendType" SG_ 190 MO_EM2_SollSpannung 0;
BA_ "GenSigStartValue" SG_ 190 MO_EM2_SollSpannung 4095;
BA_ "GenSigSwitchedByIgnition" SG_ 190 MO_EM2_SollSpannung 0;
BA_ "GenSigSendType" SG_ 190 Motor_56_BZ 0;
BA_ "GenSigFuncType" SG_ 190 Motor_56_BZ 1;
BA_ "GenSigSwitchedByIgnition" SG_ 190 Motor_56_BZ 0;
BA_ "GenSigSendType" SG_ 190 Motor_56_CRC 0;
BA_ "GenSigFuncType" SG_ 190 Motor_56_CRC 2;
BA_ "GenSigSwitchedByIgnition" SG_ 190 Motor_56_CRC 0;
BA_ "GenSigSendType" SG_ 190 SOK_MO_SollMoment_Signatur 0;
BA_ "GenSigFuncType" SG_ 190 SOK_MO_SollMoment_Signatur 15;
BA_ "GenSigSwitchedByIgnition" SG_ 190 SOK_MO_SollMoment_Signatur 0;
BA_ "GenSigSendType" SG_ 2463978666 MO_Drehzahl_EM 0;
BA_ "GenSigStartValue" SG_ 2463978666 MO_Drehzahl_EM 8190;
BA_ "GenSigSwitchedByIgnition" SG_ 2463978666 MO_Drehzahl_EM 0;
BA_ "Fehlerwert" SG_ 2463978666 MO_Drehzahl_EM 8191;
BA_ "GenSigSendType" SG_ 2463978666 MO_Drehzahl_EM_sek 0;
BA_ "GenSigStartValue" SG_ 2463978666 MO_Drehzahl_EM_sek 8190;
BA_ "GenSigSwitchedByIgnition" SG_ 2463978666 MO_Drehzahl_EM_sek 0;
BA_ "Fehlerwert" SG_ 2463978666 MO_Drehzahl_EM_sek 8191;
BA_ "GenSigSendType" SG_ 2463978666 MO_EM1_Generator_Leistung 0;
BA_ "GenSigStartValue" SG_ 2463978666 MO_EM1_Generator_Leistung 254;
BA_ "GenSigSwitchedByIgnition" SG_ 2463978666 MO_EM1_Generator_Leistung 0;
BA_ "Fehlerwert" SG_ 2463978666 MO_EM1_Generator_Leistung 255;
BA_ "GenSigSendType" SG_ 2463978666 MO_EM1_Max_Leistung_Gesamt 0;
BA_ "GenSigStartValue" SG_ 2463978666 MO_EM1_Max_Leistung_Gesamt 8190;
BA_ "GenSigSwitchedByIgnition" SG_ 2463978666 MO_EM1_Max_Leistung_Gesamt 0;
BA_ "GenSigSendType" SG_ 2463978666 MO_EM1_Max_Spannung_Lim 0;
BA_ "GenSigStartValue" SG_ 2463978666 MO_EM1_Max_Spannung_Lim 1022;
BA_ "GenSigSwitchedByIgnition" SG_ 2463978666 MO_EM1_Max_Spannung_Lim 0;
BA_ "GenSigSendType" SG_ 2463978666 MO_EM1_Min_Leistung_Gesamt 0;
BA_ "GenSigStartValue" SG_ 2463978666 MO_EM1_Min_Leistung_Gesamt 8190;
BA_ "GenSigSwitchedByIgnition" SG_ 2463978666 MO_EM1_Min_Leistung_Gesamt 0;
BA_ "GenSigSendType" SG_ 2463978666 MO_EM1_Min_Spannung_Lim 0;
BA_ "GenSigStartValue" SG_ 2463978666 MO_EM1_Min_Spannung_Lim 1022;
BA_ "GenSigSwitchedByIgnition" SG_ 2463978666 MO_EM1_Min_Spannung_Lim 0;
BA_ "GenSigSendType" SG_ 2463978666 MO_EM2_Generator_Leistung 0;
BA_ "GenSigStartValue" SG_ 2463978666 MO_EM2_Generator_Leistung 254;
BA_ "GenSigSwitchedByIgnition" SG_ 2463978666 MO_EM2_Generator_Leistung 0;
BA_ "Fehlerwert" SG_ 2463978666 MO_EM2_Generator_Leistung 255;
BA_ "GenSigSendType" SG_ 2463978666 MO_EM2_Max_Leistung_Gesamt 0;
BA_ "GenSigStartValue" SG_ 2463978666 MO_EM2_Max_Leistung_Gesamt 8190;
BA_ "GenSigSwitchedByIgnition" SG_ 2463978666 MO_EM2_Max_Leistung_Gesamt 0;
BA_ "GenSigSendType" SG_ 2463978666 MO_EM2_Max_Spannung_Lim 0;
BA_ "GenSigStartValue" SG_ 2463978666 MO_EM2_Max_Spannung_Lim 1022;
BA_ "GenSigSwitchedByIgnition" SG_ 2463978666 MO_EM2_Max_Spannung_Lim 0;
BA_ "GenSigSendType" SG_ 2463978666 MO_EM2_Min_Leistung_Gesamt 0;
BA_ "GenSigStartValue" SG_ 2463978666 MO_EM2_Min_Leistung_Gesamt 8190;
BA_ "GenSigSwitchedByIgnition" SG_ 2463978666 MO_EM2_Min_Leistung_Gesamt 0;
BA_ "GenSigSendType" SG_ 2463978666 MO_EM2_Min_Spannung_Lim 0;
BA_ "GenSigStartValue" SG_ 2463978666 MO_EM2_Min_Spannung_Lim 1022;
BA_ "GenSigSwitchedByIgnition" SG_ 2463978666 MO_EM2_Min_Spannung_Lim 0;
BA_ "GenSigSendType" SG_ 2463978666 MO_Rekuperation_EM_Ges_Ueberlauf 0;
BA_ "GenSigSwitchedByIgnition" SG_ 2463978666 MO_Rekuperation_EM_Ges_Ueberlauf 0;
BA_ "GenSigSendType" SG_ 2463978666 MO_Rekuperation_Ges_EM 0;
BA_ "GenSigSwitchedByIgnition" SG_ 2463978666 MO_Rekuperation_Ges_EM 0;
BA_ "GenSigSendType" SG_ 2463978666 MO_TNW_Max_Spannung_Lim 0;
BA_ "GenSigStartValue" SG_ 2463978666 MO_TNW_Max_Spannung_Lim 1022;
BA_ "GenSigSwitchedByIgnition" SG_ 2463978666 MO_TNW_Max_Spannung_Lim 0;
BA_ "GenSigSendType" SG_ 2463978666 MO_TNW_Min_Spannung_Lim 0;
BA_ "GenSigStartValue" SG_ 2463978666 MO_TNW_Min_Spannung_Lim 1022;
BA_ "GenSigSwitchedByIgnition" SG_ 2463978666 MO_TNW_Min_Spannung_Lim 0;
BA_ "GenSigSendType" SG_ 2463978666 MO_Uebersetzung_EM 0;
BA_ "GenSigStartValue" SG_ 2463978666 MO_Uebersetzung_EM 1022;
BA_ "GenSigSwitchedByIgnition" SG_ 2463978666 MO_Uebersetzung_EM 0;
BA_ "Fehlerwert" SG_ 2463978666 MO_Uebersetzung_EM 1023;
BA_ "GenSigSendType" SG_ 2463978666 MO_Uebersetzung_EM_sek 0;
BA_ "GenSigStartValue" SG_ 2463978666 MO_Uebersetzung_EM_sek 1022;
BA_ "GenSigSwitchedByIgnition" SG_ 2463978666 MO_Uebersetzung_EM_sek 0;
BA_ "Fehlerwert" SG_ 2463978666 MO_Uebersetzung_EM_sek 1023;
BA_ "GenSigSendType" SG_ 2463978666 MO_Verbrauch_EM_Ges 0;
BA_ "GenSigSwitchedByIgnition" SG_ 2463978666 MO_Verbrauch_EM_Ges 0;
BA_ "GenSigSendType" SG_ 2463978666 MO_Verbrauch_EM_Ges_Ueberlauf 0;
BA_ "GenSigSwitchedByIgnition" SG_ 2463978666 MO_Verbrauch_EM_Ges_Ueberlauf 0;
BA_ "GenSigSendType" SG_ 2463978666 Motor_57_BZ 0;
BA_ "GenSigFuncType" SG_ 2463978666 Motor_57_BZ 1;
BA_ "GenSigSwitchedByIgnition" SG_ 2463978666 Motor_57_BZ 0;
BA_ "GenSigSendType" SG_ 2463978666 Motor_57_CRC 0;
BA_ "GenSigFuncType" SG_ 2463978666 Motor_57_CRC 2;
BA_ "GenSigSwitchedByIgnition" SG_ 2463978666 Motor_57_CRC 0;
BA_ "GenSigSendType" SG_ 2331595982 PTHyDrA_PrctUtilElDrv 0;
BA_ "GenSigStartValue" SG_ 2331595982 PTHyDrA_PrctUtilElDrv 2047;
BA_ "GenSigSwitchedByIgnition" SG_ 2331595982 PTHyDrA_PrctUtilElDrv 0;
BA_ "GenSigSendType" SG_ 2331595982 PTHyDrA_StAcv 0;
BA_ "GenSigStartValue" SG_ 2331595982 PTHyDrA_StAcv 3;
BA_ "GenSigSwitchedByIgnition" SG_ 2331595982 PTHyDrA_StAcv 0;
BA_ "GenSigSendType" SG_ 2331595982 PTUIPwrm_FacPwrDyn 0;
BA_ "GenSigStartValue" SG_ 2331595982 PTUIPwrm_FacPwrDyn 127;
BA_ "GenSigSwitchedByIgnition" SG_ 2331595982 PTUIPwrm_FacPwrDyn 0;
BA_ "GenSigSendType" SG_ 2331595982 PTUIPwrm_PrctBoostAvl 0;
BA_ "GenSigStartValue" SG_ 2331595982 PTUIPwrm_PrctBoostAvl 1023;
BA_ "GenSigSwitchedByIgnition" SG_ 2331595982 PTUIPwrm_PrctBoostAvl 0;
BA_ "GenSigSendType" SG_ 2331595982 PTUIPwrm_PrctPwrEcoMaxUse 0;
BA_ "GenSigStartValue" SG_ 2331595982 PTUIPwrm_PrctPwrEcoMaxUse 2047;
BA_ "GenSigSwitchedByIgnition" SG_ 2331595982 PTUIPwrm_PrctPwrEcoMaxUse 0;
BA_ "GenSigSendType" SG_ 2331595982 PTUIPwrm_PrctPwrElBoostCur 0;
BA_ "GenSigStartValue" SG_ 2331595982 PTUIPwrm_PrctPwrElBoostCur 1023;
BA_ "GenSigSwitchedByIgnition" SG_ 2331595982 PTUIPwrm_PrctPwrElBoostCur 0;
BA_ "GenSigSendType" SG_ 2331595982 PTUIPwrm_PrctPwrElBoostMaxUse 0;
BA_ "GenSigStartValue" SG_ 2331595982 PTUIPwrm_PrctPwrElBoostMaxUse 1023;
BA_ "GenSigSwitchedByIgnition" SG_ 2331595982 PTUIPwrm_PrctPwrElBoostMaxUse 0;
BA_ "GenSigSendType" SG_ 2331595982 PTUIPwrm_PrctPwrElDrvCur 0;
BA_ "GenSigStartValue" SG_ 2331595982 PTUIPwrm_PrctPwrElDrvCur 4095;
BA_ "GenSigSwitchedByIgnition" SG_ 2331595982 PTUIPwrm_PrctPwrElDrvCur 0;
BA_ "GenSigSendType" SG_ 2331595982 PTUIPwrm_PrctPwrGnrMaxUse 0;
BA_ "GenSigStartValue" SG_ 2331595982 PTUIPwrm_PrctPwrGnrMaxUse 2047;
BA_ "GenSigSwitchedByIgnition" SG_ 2331595982 PTUIPwrm_PrctPwrGnrMaxUse 0;
BA_ "GenSigSendType" SG_ 2331595982 PTUIPwrm_PrctPwrMotElMaxUse 0;
BA_ "GenSigStartValue" SG_ 2331595982 PTUIPwrm_PrctPwrMotElMaxUse 2047;
BA_ "GenSigSwitchedByIgnition" SG_ 2331595982 PTUIPwrm_PrctPwrMotElMaxUse 0;
BA_ "GenSigSendType" SG_ 2331595982 PTUIPwrm_PrctPwrMotMaxUse 0;
BA_ "GenSigStartValue" SG_ 2331595982 PTUIPwrm_PrctPwrMotMaxUse 2047;
BA_ "GenSigSwitchedByIgnition" SG_ 2331595982 PTUIPwrm_PrctPwrMotMaxUse 0;
BA_ "GenSigSendType" SG_ 2331595982 PTUIPwrm_PrctPwrSysCur 0;
BA_ "GenSigStartValue" SG_ 2331595982 PTUIPwrm_PrctPwrSysCur 4095;
BA_ "GenSigSwitchedByIgnition" SG_ 2331595982 PTUIPwrm_PrctPwrSysCur 0;
BA_ "GenSigSendType" SG_ 2331595982 PTUIPwrm_PrctPwrSysMaxUseTemp 0;
BA_ "GenSigStartValue" SG_ 2331595982 PTUIPwrm_PrctPwrSysMaxUseTemp 2047;
BA_ "GenSigSwitchedByIgnition" SG_ 2331595982 PTUIPwrm_PrctPwrSysMaxUseTemp 0;
BA_ "GenSigSendType" SG_ 2331595982 PTUIPwrm_PwrElBoostNom 0;
BA_ "GenSigStartValue" SG_ 2331595982 PTUIPwrm_PwrElBoostNom 1023;
BA_ "GenSigSwitchedByIgnition" SG_ 2331595982 PTUIPwrm_PwrElBoostNom 0;
BA_ "GenSigSendType" SG_ 2331595982 PTUIPwrm_StAcv 0;
BA_ "GenSigStartValue" SG_ 2331595982 PTUIPwrm_StAcv 3;
BA_ "GenSigSwitchedByIgnition" SG_ 2331595982 PTUIPwrm_StAcv 0;
BA_ "GenSigSendType" SG_ 2589283946 PTUIPwrm_PwrGnrNom 0;
BA_ "GenSigStartValue" SG_ 2589283946 PTUIPwrm_PwrGnrNom 2047;
BA_ "GenSigSwitchedByIgnition" SG_ 2589283946 PTUIPwrm_PwrGnrNom 0;
BA_ "GenSigSendType" SG_ 2589283946 PTUIPwrm_PwrMotElNom 0;
BA_ "GenSigStartValue" SG_ 2589283946 PTUIPwrm_PwrMotElNom 2047;
BA_ "GenSigSwitchedByIgnition" SG_ 2589283946 PTUIPwrm_PwrMotElNom 0;
BA_ "GenSigSendType" SG_ 2589283946 PTUIPwrm_PwrSysMotNomDisp 0;
BA_ "GenSigStartValue" SG_ 2589283946 PTUIPwrm_PwrSysMotNomDisp 2047;
BA_ "GenSigSwitchedByIgnition" SG_ 2589283946 PTUIPwrm_PwrSysMotNomDisp 0;
BA_ "GenSigSendType" SG_ 2589284069 MO_Aschebeladung_OPF 0;
BA_ "GenSigSwitchedByIgnition" SG_ 2589284069 MO_Aschebeladung_OPF 0;
BA_ "GenSigSendType" SG_ 2589284069 MO_Beladungsstufe_OPF 0;
BA_ "GenSigSwitchedByIgnition" SG_ 2589284069 MO_Beladungsstufe_OPF 0;
BA_ "GenSigSendType" SG_ 2589284069 MO_Modellbeladung_OPF 0;
BA_ "GenSigSwitchedByIgnition" SG_ 2589284069 MO_Modellbeladung_OPF 0;
BA_ "GenSigSendType" SG_ 2589284069 MO_Offset_Nockenwelle1 0;
BA_ "GenSigStartValue" SG_ 2589284069 MO_Offset_Nockenwelle1 128;
BA_ "GenSigSwitchedByIgnition" SG_ 2589284069 MO_Offset_Nockenwelle1 0;
BA_ "GenSigSendType" SG_ 2589284069 MO_Offset_Nockenwelle2 0;
BA_ "GenSigStartValue" SG_ 2589284069 MO_Offset_Nockenwelle2 128;
BA_ "GenSigSwitchedByIgnition" SG_ 2589284069 MO_Offset_Nockenwelle2 0;
BA_ "GenSigSendType" SG_ 2589284069 MO_Sensorbeladung_OPF 0;
BA_ "GenSigSwitchedByIgnition" SG_ 2589284069 MO_Sensorbeladung_OPF 0;
BA_ "GenSigSendType" SG_ 1601 MO_Ansaugsystem 0;
BA_ "GenSigFuncType" SG_ 1601 MO_Ansaugsystem 8;
BA_ "GenSigSwitchedByIgnition" SG_ 1601 MO_Ansaugsystem 0;
BA_ "GenSigSendType" SG_ 1601 MO_Anzahl_Zyl 0;
BA_ "GenSigFuncType" SG_ 1601 MO_Anzahl_Zyl 8;
BA_ "GenSigSwitchedByIgnition" SG_ 1601 MO_Anzahl_Zyl 0;
BA_ "GenSigSendType" SG_ 1601 MO_Anzeige_StSt_gueltig 0;
BA_ "GenSigSwitchedByIgnition" SG_ 1601 MO_Anzeige_StSt_gueltig 0;
BA_ "GenSigSendType" SG_ 1601 MO_Code 0;
BA_ "GenSigSwitchedByIgnition" SG_ 1601 MO_Code 0;
BA_ "GenSigSendType" SG_ 1601 MO_DPF_verbaut 0;
BA_ "GenSigFuncType" SG_ 1601 MO_DPF_verbaut 8;
BA_ "GenSigSwitchedByIgnition" SG_ 1601 MO_DPF_verbaut 0;
BA_ "GenSigSendType" SG_ 1601 MO_Faktor_Momente_02 0;
BA_ "GenSigFuncType" SG_ 1601 MO_Faktor_Momente_02 8;
BA_ "GenSigSwitchedByIgnition" SG_ 1601 MO_Faktor_Momente_02 0;
BA_ "GenSigSendType" SG_ 1601 MO_Getriebe_Code 0;
BA_ "GenSigSwitchedByIgnition" SG_ 1601 MO_Getriebe_Code 0;
BA_ "GenSigSendType" SG_ 1601 MO_Hubraum 0;
BA_ "GenSigFuncType" SG_ 1601 MO_Hubraum 8;
BA_ "GenSigSwitchedByIgnition" SG_ 1601 MO_Hubraum 0;
BA_ "GenSigSendType" SG_ 1601 MO_Hybridfahrzeug 0;
BA_ "GenSigFuncType" SG_ 1601 MO_Hybridfahrzeug 8;
BA_ "GenSigSwitchedByIgnition" SG_ 1601 MO_Hybridfahrzeug 0;
BA_ "GenSigSendType" SG_ 1601 MO_Kraftstoffart 0;
BA_ "GenSigFuncType" SG_ 1601 MO_Kraftstoffart 8;
BA_ "GenSigSwitchedByIgnition" SG_ 1601 MO_Kraftstoffart 0;
BA_ "GenSigSendType" SG_ 1601 MO_Leistung 0;
BA_ "GenSigSwitchedByIgnition" SG_ 1601 MO_Leistung 0;
BA_ "GenSigSendType" SG_ 1601 MO_OBD_Typ 0;
BA_ "GenSigSwitchedByIgnition" SG_ 1601 MO_OBD_Typ 0;
BA_ "GenSigSendType" SG_ 1601 MO_StartStopp_Codiert 0;
BA_ "GenSigFuncType" SG_ 1601 MO_StartStopp_Codiert 8;
BA_ "GenSigSwitchedByIgnition" SG_ 1601 MO_StartStopp_Codiert 0;
BA_ "GenSigSendType" SG_ 1601 Motor_Code_01_BZ 0;
BA_ "GenSigFuncType" SG_ 1601 Motor_Code_01_BZ 1;
BA_ "GenSigSwitchedByIgnition" SG_ 1601 Motor_Code_01_BZ 0;
BA_ "GenSigSendType" SG_ 1601 Motor_Code_01_CRC 0;
BA_ "GenSigFuncType" SG_ 1601 Motor_Code_01_CRC 2;
BA_ "GenSigSwitchedByIgnition" SG_ 1601 Motor_Code_01_CRC 0;
BA_ "GenSigSendType" SG_ 1601 TSK_Codierung 0;
BA_ "GenSigStartValue" SG_ 1601 TSK_Codierung 7;
BA_ "GenSigSwitchedByIgnition" SG_ 1601 TSK_Codierung 0;
BA_ "GenSigSendType" SG_ 391 EV_Rekuperationsstufe 0;
BA_ "GenSigSwitchedByIgnition" SG_ 391 EV_Rekuperationsstufe 0;
BA_ "GenSigSendType" SG_ 391 MO_Drehzahl_VM 0;
BA_ "GenSigSwitchedByIgnition" SG_ 391 MO_Drehzahl_VM 0;
BA_ "GenSigSendType" SG_ 391 MO_Fehler_Notabschaltung_Klima 3;
BA_ "GenSigSwitchedByIgnition" SG_ 391 MO_Fehler_Notabschaltung_Klima 0;
BA_ "GenSigSendType" SG_ 391 MO_Fehler_NTKreis 0;
BA_ "GenSigSwitchedByIgnition" SG_ 391 MO_Fehler_NTKreis 0;
BA_ "Fehlerwert" SG_ 391 MO_Fehler_NTKreis 1;
BA_ "GenSigSendType" SG_ 391 MO_KLE_FStatus 0;
BA_ "GenSigSwitchedByIgnition" SG_ 391 MO_KLE_FStatus 0;
BA_ "Fehlerwert" SG_ 391 MO_KLE_FStatus 3;
BA_ "GenSigSendType" SG_ 391 MO_Tankbereitschaft_Status 0;
BA_ "GenSigSwitchedByIgnition" SG_ 391 MO_Tankbereitschaft_Status 0;
BA_ "GenSigSendType" SG_ 391 MO_Tankklappensteuerung 0;
BA_ "GenSigSwitchedByIgnition" SG_ 391 MO_Tankklappensteuerung 0;
BA_ "GenSigSendType" SG_ 391 MO_Waehlpos 3;
BA_ "GenSigSwitchedByIgnition" SG_ 391 MO_Waehlpos 0;
BA_ "Fehlerwert" SG_ 391 MO_Waehlpos 7;
BA_ "GenSigSendType" SG_ 391 MO_WH_Texte 3;
BA_ "GenSigSwitchedByIgnition" SG_ 391 MO_WH_Texte 0;
BA_ "GenSigSendType" SG_ 391 Motor_EV_01_BZ 0;
BA_ "GenSigFuncType" SG_ 391 Motor_EV_01_BZ 1;
BA_ "GenSigSwitchedByIgnition" SG_ 391 Motor_EV_01_BZ 0;
BA_ "GenSigSendType" SG_ 391 Motor_EV_01_CRC 0;
BA_ "GenSigFuncType" SG_ 391 Motor_EV_01_CRC 2;
BA_ "GenSigSwitchedByIgnition" SG_ 391 Motor_EV_01_CRC 0;
BA_ "GenSigSendType" SG_ 813 MO_akt_Betrieb 0;
BA_ "GenSigSwitchedByIgnition" SG_ 813 MO_akt_Betrieb 0;
BA_ "GenSigSendType" SG_ 813 MO_AnzeigeGasbetrieb 0;
BA_ "GenSigSwitchedByIgnition" SG_ 813 MO_AnzeigeGasbetrieb 0;
BA_ "GenSigSendType" SG_ 813 MO_CNG_LPG 0;
BA_ "GenSigSwitchedByIgnition" SG_ 813 MO_CNG_LPG 0;
BA_ "GenSigSwitchedByIgnition" SG_ 813 MO_CNG_Tankstopp 0;
BA_ "GenSigSwitchedByIgnition" SG_ 813 MO_CNG_Ueberlauf 0;
BA_ "GenSigSendType" SG_ 813 MO_Erdgasqualitaet 0;
BA_ "GenSigSwitchedByIgnition" SG_ 813 MO_Erdgasqualitaet 0;
BA_ "GenSigSwitchedByIgnition" SG_ 813 MO_Fuellstand_LPG 0;
BA_ "Fehlerwert" SG_ 813 MO_Fuellstand_LPG 1023;
BA_ "GenSigStartValue" SG_ 813 MO_Fuellungsgrad_CNG 254;
BA_ "GenSigSwitchedByIgnition" SG_ 813 MO_Fuellungsgrad_CNG 0;
BA_ "Fehlerwert" SG_ 813 MO_Fuellungsgrad_CNG 255;
BA_ "GenSigStartValue" SG_ 813 MO_Fuellungsgrad_LPG 254;
BA_ "GenSigSwitchedByIgnition" SG_ 813 MO_Fuellungsgrad_LPG 0;
BA_ "Fehlerwert" SG_ 813 MO_Fuellungsgrad_LPG 255;
BA_ "GenSigSwitchedByIgnition" SG_ 813 MO_LPG_Tankstopp 0;
BA_ "GenSigSwitchedByIgnition" SG_ 813 MO_LPG_Ueberlauf 0;
BA_ "GenSigSwitchedByIgnition" SG_ 813 MO_Tankmasse_CNG 0;
BA_ "Fehlerwert" SG_ 813 MO_Tankmasse_CNG 255;
BA_ "GenSigSwitchedByIgnition" SG_ 813 MO_Tankvolumen_LPG 0;
BA_ "Fehlerwert" SG_ 813 MO_Tankvolumen_LPG 255;
BA_ "GenSigSwitchedByIgnition" SG_ 813 MO_Verbrauch_CNG 0;
BA_ "GenSigSwitchedByIgnition" SG_ 813 MO_Verbrauch_LPG 0;
BA_ "GenSigSendType" SG_ 813 MO_Verbrauchsaequivalent 0;
BA_ "GenSigStartValue" SG_ 813 MO_Verbrauchsaequivalent 254;
BA_ "GenSigSwitchedByIgnition" SG_ 813 MO_Verbrauchsaequivalent 0;
BA_ "Fehlerwert" SG_ 813 MO_Verbrauchsaequivalent 255;
BA_ "GenSigSendType" SG_ 1155 MO_Powermeter_Charge_Grenze 3;
BA_ "GenSigStartValue" SG_ 1155 MO_Powermeter_Charge_Grenze 1022;
BA_ "GenSigSwitchedByIgnition" SG_ 1155 MO_Powermeter_Charge_Grenze 0;
BA_ "Fehlerwert" SG_ 1155 MO_Powermeter_Charge_Grenze 1023;
BA_ "GenSigSendType" SG_ 1155 Mo_Powermeter_Grenze 3;
BA_ "GenSigStartValue" SG_ 1155 Mo_Powermeter_Grenze 4093;
BA_ "GenSigSwitchedByIgnition" SG_ 1155 Mo_Powermeter_Grenze 0;
BA_ "GenSigSendType" SG_ 1155 MO_Powermeter_Grenze_strategisch 3;
BA_ "GenSigStartValue" SG_ 1155 MO_Powermeter_Grenze_strategisch 4094;
BA_ "GenSigSwitchedByIgnition" SG_ 1155 MO_Powermeter_Grenze_strategisch 0;
BA_ "Fehlerwert" SG_ 1155 MO_Powermeter_Grenze_strategisch 4095;
BA_ "GenSigSendType" SG_ 1155 MO_Powermeter_Inszenierung_aktiv 3;
BA_ "GenSigSwitchedByIgnition" SG_ 1155 MO_Powermeter_Inszenierung_aktiv 0;
BA_ "GenSigSendType" SG_ 1155 MO_Powermeter_obere_E_Grenze 3;
BA_ "GenSigStartValue" SG_ 1155 MO_Powermeter_obere_E_Grenze 4094;
BA_ "GenSigSwitchedByIgnition" SG_ 1155 MO_Powermeter_obere_E_Grenze 0;
BA_ "Fehlerwert" SG_ 1155 MO_Powermeter_obere_E_Grenze 4095;
BA_ "GenSigSendType" SG_ 1155 MO_Powermeter_untere_E_Grenze 3;
BA_ "GenSigStartValue" SG_ 1155 MO_Powermeter_untere_E_Grenze 4094;
BA_ "GenSigSwitchedByIgnition" SG_ 1155 MO_Powermeter_untere_E_Grenze 0;
BA_ "Fehlerwert" SG_ 1155 MO_Powermeter_untere_E_Grenze 4095;
BA_ "GenSigSendType" SG_ 2589284112 MO_VTD_CDEODT_L 0;
BA_ "GenSigSwitchedByIgnition" SG_ 2589284112 MO_VTD_CDEODT_L 0;
BA_ "GenSigSendType" SG_ 2589284112 MO_VTD_TD_L 0;
BA_ "GenSigSwitchedByIgnition" SG_ 2589284112 MO_VTD_TD_L 0;
BA_ "GenSigSendType" SG_ 2589284113 SOK_Motor_VTD_01_Signatur 0;
BA_ "GenSigFuncType" SG_ 2589284113 SOK_Motor_VTD_01_Signatur 15;
BA_ "GenSigSwitchedByIgnition" SG_ 2589284113 SOK_Motor_VTD_01_Signatur 0;
BA_ "GenSigSendType" SG_ 2589284114 MO_VTD_CDERDT_L 0;
BA_ "GenSigSwitchedByIgnition" SG_ 2589284114 MO_VTD_CDERDT_L 0;
BA_ "GenSigSendType" SG_ 2589284114 MO_VTD_CDFC_L 0;
BA_ "GenSigSwitchedByIgnition" SG_ 2589284114 MO_VTD_CDFC_L 0;
BA_ "GenSigSendType" SG_ 2589284115 SOK_Motor_VTD_02_Signatur 0;
BA_ "GenSigFuncType" SG_ 2589284115 SOK_Motor_VTD_02_Signatur 15;
BA_ "GenSigSwitchedByIgnition" SG_ 2589284115 SOK_Motor_VTD_02_Signatur 0;
BA_ "GenSigSendType" SG_ 2589284116 MO_VTD_CIDT_L 0;
BA_ "GenSigSwitchedByIgnition" SG_ 2589284116 MO_VTD_CIDT_L 0;
BA_ "GenSigSendType" SG_ 2589284116 MO_VTD_GE_L 0;
BA_ "GenSigSwitchedByIgnition" SG_ 2589284116 MO_VTD_GE_L 0;
BA_ "GenSigSendType" SG_ 2589284117 SOK_Motor_VTD_03_Signatur 0;
BA_ "GenSigFuncType" SG_ 2589284117 SOK_Motor_VTD_03_Signatur 15;
BA_ "GenSigSwitchedByIgnition" SG_ 2589284117 SOK_Motor_VTD_03_Signatur 0;
BA_ "GenSigSendType" SG_ 2589284118 MO_VTD_CIFC_L 0;
BA_ "GenSigSwitchedByIgnition" SG_ 2589284118 MO_VTD_CIFC_L 0;
BA_ "GenSigSendType" SG_ 2589284118 MO_VTD_FC_L 0;
BA_ "GenSigSwitchedByIgnition" SG_ 2589284118 MO_VTD_FC_L 0;
BA_ "GenSigSendType" SG_ 2589284119 SOK_Motor_VTD_04_Signatur 0;
BA_ "GenSigFuncType" SG_ 2589284119 SOK_Motor_VTD_04_Signatur 15;
BA_ "GenSigSwitchedByIgnition" SG_ 2589284119 SOK_Motor_VTD_04_Signatur 0;
BA_ "GenSigSwitchedByIgnition" SG_ 16 WFS_MSG1_CRC 0;
BA_ "GenSigSendType" SG_ 16 WFS_MSG1_RND 1;
BA_ "GenSigSwitchedByIgnition" SG_ 16 WFS_MSG1_RND 0;
BA_ "GenSigSwitchedByIgnition" SG_ 22 WFS_MSG3_CRC 0;
BA_ "GenSigSendType" SG_ 22 WFS_MSG3_RND 1;
BA_ "GenSigSwitchedByIgnition" SG_ 22 WFS_MSG3_RND 0;
BA_ "GenSigSwitchedByIgnition" SG_ 24 WFS_MSG4_CRC 0;
BA_ "GenSigSendType" SG_ 24 WFS_MSG4_RND 1;
BA_ "GenSigSwitchedByIgnition" SG_ 24 WFS_MSG4_RND 0;
BA_REL_ "GenSigTimeoutTime" BU_SG_REL_ Gateway_Max SG_ 267 MO_Fahrpedalrohwert_01 500;
BA_REL_ "GenSigTimeoutTime" BU_SG_REL_ Gateway_Max SG_ 267 MO_QBit_Fahrpedalwerte_01 500;
BA_REL_ "GenSigTimeoutTime" BU_SG_REL_ Gateway_Max SG_ 267 MO_Fahrpedalgradient 500;
BA_REL_ "GenSigTimeoutTime" BU_SG_REL_ Gateway_Max SG_ 267 MO_Sig_Fahrpedalgradient 500;
BA_REL_ "GenSigTimeoutTime" BU_SG_REL_ Gateway_Max SG_ 267 MO_Solldrehz_Leerlauf 500;
BA_REL_ "GenSigTimeoutTime" BU_SG_REL_ Gateway_Max SG_ 330 MO_KVS 500;
BA_REL_ "GenSigTimeoutTime" BU_SG_REL_ Gateway_Max SG_ 330 MO_KVS_Ueberlauf 500;
BA_REL_ "GenSigTimeoutTime" BU_SG_REL_ Gateway_Max SG_ 330 MO_Zust_Antrieb 500;
BA_REL_ "GenSigTimeoutTime" BU_SG_REL_ Gateway_Max SG_ 330 MO_Zust_Betriebsstrategie 500;
BA_REL_ "GenSigTimeoutTime" BU_SG_REL_ Gateway_Max SG_ 330 Ladezustand_02 500;
BA_REL_ "GenSigTimeoutTime" BU_SG_REL_ Gateway_Max SG_ 512 TSK_Limiter_Anzeige 500;
BA_REL_ "GenSigTimeoutTime" BU_SG_REL_ Gateway_Max SG_ 512 TSK_Status_Anzeige 500;
BA_REL_ "GenSigTimeoutTime" BU_SG_REL_ Gateway_Max SG_ 512 MO_Sperrung_FahrPr_BZS 500;
BA_REL_ "GenSigTimeoutTime" BU_SG_REL_ Gateway_Max SG_ 512 MO_Rampenzeit_Generator_Anf 500;
BA_REL_ "GenSigTimeoutTime" BU_SG_REL_ Gateway_Max SG_ 512 MO_BZS_Charisma_FahrPr 500;
BA_REL_ "GenSigTimeoutTime" BU_SG_REL_ Gateway_Max SG_ 512 MO_BZS_Charisma_Status 500;
BA_REL_ "GenSigTimeoutTime" BU_SG_REL_ Gateway_Max SG_ 332 TSK_vMax_aktuell 1000;
BA_REL_ "GenSigTimeoutTime" BU_SG_REL_ Gateway_Max SG_ 332 MO_Fahrbereitschaft 1000;
BA_REL_ "GenSigTimeoutTime" BU_SG_REL_ Gateway_Max SG_ 332 MO_UBE_Hybrid_Reserve 1000;
BA_REL_ "GenSigTimeoutTime" BU_SG_REL_ Gateway_Max SG_ 332 OBD_Eng_Cool_Temp 1000;
BA_REL_ "GenSigTimeoutTime" BU_SG_REL_ Gateway_Max SG_ 332 MO_QBit_Aussen_Temp 1000;
BA_REL_ "GenSigTimeoutTime" BU_SG_REL_ Gateway_Max SG_ 332 OBD_Driving_Cycle 1000;
BA_REL_ "GenSigTimeoutTime" BU_SG_REL_ Gateway_Max SG_ 332 MO_MVEM_MaxLeistung_MVVerbrauch 1000;
BA_REL_ "GenSigTimeoutTime" BU_SG_REL_ Gateway_Max SG_ 332 OBD_Aussen_Temp_gef 1000;
BA_REL_ "GenSigTimeoutTime" BU_SG_REL_ Gateway_Max SG_ 246 Motor_55_CRC 500;
BA_REL_ "GenSigTimeoutTime" BU_SG_REL_ Gateway_Max SG_ 246 Motor_55_BZ 500;
BA_REL_ "GenSigTimeoutTime" BU_SG_REL_ Gateway_Max SG_ 246 MO_EMG_Sollmodus 500;
BA_REL_ "GenSigTimeoutTime" BU_SG_REL_ Gateway_Max SG_ 190 MO_EM1_Sollmodus 500;
BA_REL_ "GenSigTimeoutTime" BU_SG_REL_ Gateway_Max SG_ 190 MO_DC_Max_Strom_HV 500;
BA_REL_ "GenSigTimeoutTime" BU_SG_REL_ Gateway_Max SG_ 2463978666 MO_Verbrauch_EM_Ges 1000;
BA_REL_ "GenSigTimeoutTime" BU_SG_REL_ Gateway_Max SG_ 2463978666 MO_Verbrauch_EM_Ges_Ueberlauf 1000;
BA_REL_ "GenSigTimeoutTime" BU_SG_REL_ Gateway_Max SG_ 2463978666 MO_Rekuperation_Ges_EM 1000;
BA_REL_ "GenSigTimeoutTime" BU_SG_REL_ Gateway_Max SG_ 2463978666 MO_Rekuperation_EM_Ges_Ueberlauf 1000;
BA_REL_ "GenSigTimeoutTime" BU_SG_REL_ Gateway_Max SG_ 1601 MO_Hybridfahrzeug 5000;
BA_REL_ "GenSigTimeoutTime" BU_SG_REL_ Gateway_Max SG_ 1601 MO_Getriebe_Code 5000;
BA_REL_ "GenSigTimeoutTime" BU_SG_REL_ Gateway_Max SG_ 1601 MO_StartStopp_Codiert 5000;
BA_REL_ "GenSigTimeoutTime" BU_SG_REL_ Gateway_Max SG_ 1601 MO_Anzeige_StSt_gueltig 5000;
BA_REL_ "GenSigTimeoutTime" BU_SG_REL_ Gateway_Max SG_ 1601 MO_Anzahl_Zyl 5000;
BA_REL_ "GenSigTimeoutTime" BU_SG_REL_ Gateway_Max SG_ 1601 MO_Kraftstoffart 5000;
BA_REL_ "GenSigTimeoutTime" BU_SG_REL_ Gateway_Max SG_ 1601 MO_Hubraum 5000;
BA_REL_ "GenSigTimeoutTime" BU_SG_REL_ Gateway_Max SG_ 1601 MO_OBD_Typ 5000;
BA_REL_ "GenSigTimeoutTime" BU_SG_REL_ Gateway_Max SG_ 391 MO_Waehlpos 1000;
BA_REL_ "GenSigTimeoutTime" BU_SG_REL_ Gateway_Max SG_ 813 MO_CNG_Tankstopp 500;
BA_REL_ "GenSigTimeoutTime" BU_SG_REL_ Gateway_Max SG_ 813 MO_akt_Betrieb 500;
BA_REL_ "GenSigTimeoutTime" BU_SG_REL_ Gateway_Max SG_ 813 MO_Verbrauchsaequivalent 500;
BA_REL_ "GenSigTimeoutTime" BU_SG_REL_ Gateway_Max SG_ 813 MO_Tankmasse_CNG 500;
BA_REL_ "GenSigTimeoutTime" BU_SG_REL_ Gateway_Max SG_ 813 MO_Fuellungsgrad_CNG 500;
BA_REL_ "GenSigTimeoutTime" BU_SG_REL_ Gateway_Max SG_ 813 MO_CNG_Ueberlauf 500;
BA_REL_ "GenSigTimeoutTime" BU_SG_REL_ Gateway_Max SG_ 813 MO_Verbrauch_CNG 500;
BA_REL_ "GenSigTimeoutTime" BU_SG_REL_ Getriebe_DQ SG_ 267 MO_Fahrpedalrohwert_01 500;
BA_REL_ "GenSigTimeoutTime" BU_SG_REL_ Getriebe_DQ SG_ 267 MO_QBit_Fahrpedalwerte_01 500;
BA_REL_ "GenSigTimeoutTime" BU_SG_REL_ Getriebe_DQ SG_ 267 MO_Moment_im_Leerlauf 500;
BA_REL_ "GenSigTimeoutTime" BU_SG_REL_ Getriebe_DQ SG_ 267 MO_Schubabschaltung 500;
BA_REL_ "GenSigTimeoutTime" BU_SG_REL_ Getriebe_DQ SG_ 267 MO_StartStopp_StoppVorbereitung 500;
BA_REL_ "GenSigTimeoutTime" BU_SG_REL_ Getriebe_DQ SG_ 267 MO_Solldrehz_Leerlauf 500;
BA_REL_ "GenSigTimeoutTime" BU_SG_REL_ Getriebe_DQ SG_ 267 TSK_Radbremsmom 500;
BA_REL_ "GenSigTimeoutTime" BU_SG_REL_ Getriebe_DQ SG_ 267 TSK_Status 500;
BA_REL_ "GenSigTimeoutTime" BU_SG_REL_ Getriebe_DQ SG_ 267 TSK_v_Begrenzung_aktiv 500;
BA_REL_ "GenSigTimeoutTime" BU_SG_REL_ Getriebe_DQ SG_ 267 TSK_Freig_Verzoeg_Anf 500;
BA_REL_ "GenSigTimeoutTime" BU_SG_REL_ Getriebe_DQ SG_ 267 TSK_ax_Getriebe_02 500;
BA_REL_ "GenSigTimeoutTime" BU_SG_REL_ Getriebe_DQ SG_ 330 MO_Effizienzmodus 500;
BA_REL_ "GenSigTimeoutTime" BU_SG_REL_ Getriebe_DQ SG_ 512 CE_StLdRdcEmiSysPrep 500;
BA_REL_ "GenSigTimeoutTime" BU_SG_REL_ Getriebe_DQ SG_ 512 MO_Prio_MAX_Wunschdrehzahl 500;
BA_REL_ "GenSigTimeoutTime" BU_SG_REL_ Getriebe_DQ SG_ 512 MO_Prio_MIN_Wunschdrehzahl 500;
BA_REL_ "GenSigTimeoutTime" BU_SG_REL_ Getriebe_DQ SG_ 512 MO_MIN_Wunschdrehzahl 500;
BA_REL_ "GenSigTimeoutTime" BU_SG_REL_ Getriebe_DQ SG_ 512 MO_MAX_Wunschdrehzahl 500;
BA_REL_ "GenSigTimeoutTime" BU_SG_REL_ Getriebe_DQ SG_ 332 TSK_Status_IPA 1000;
BA_REL_ "GenSigTimeoutTime" BU_SG_REL_ Getriebe_DQ SG_ 332 TSK_aktives_System_02 1000;
BA_REL_ "GenSigTimeoutTime" BU_SG_REL_ Getriebe_DQ SG_ 332 TSK_Status_RHP 1000;
BA_REL_ "GenSigTimeoutTime" BU_SG_REL_ Getriebe_DQ SG_ 332 MO_Fahrbereitschaft 1000;
BA_REL_ "GenSigTimeoutTime" BU_SG_REL_ Getriebe_DQ SG_ 332 MO_Freilauf_Info 1000;
BA_REL_ "GenSigTimeoutTime" BU_SG_REL_ Getriebe_DQ SG_ 332 MO_Veto_Launchcontrol 1000;
BA_REL_ "GenSigTimeoutTime" BU_SG_REL_ Getriebe_DQ SG_ 332 MO_Startwunsch 1000;
BA_REL_ "GenSigTimeoutTime" BU_SG_REL_ Getriebe_DQ SG_ 332 OBDProtocol_req 1000;
BA_REL_ "GenSigTimeoutTime" BU_SG_REL_ Getriebe_DQ SG_ 332 OBD_Calc_Load_Val 1000;
BA_REL_ "GenSigTimeoutTime" BU_SG_REL_ Getriebe_DQ SG_ 332 OBD_Eng_Cool_Temp 1000;
BA_REL_ "GenSigTimeoutTime" BU_SG_REL_ Getriebe_DQ SG_ 332 OBD_Abs_Throttle_Pos 1000;
BA_REL_ "GenSigTimeoutTime" BU_SG_REL_ Getriebe_DQ SG_ 332 OBD_Abs_Load_Val 1000;
BA_REL_ "GenSigTimeoutTime" BU_SG_REL_ Getriebe_DQ SG_ 332 OBD_Abs_Pedal_Pos 1000;
BA_REL_ "GenSigTimeoutTime" BU_SG_REL_ Getriebe_DQ SG_ 332 MO_Servicemodus 1000;
BA_REL_ "GenSigTimeoutTime" BU_SG_REL_ Getriebe_DQ SG_ 332 OBD_ClearMem_Inhibit 1000;
BA_REL_ "GenSigTimeoutTime" BU_SG_REL_ Getriebe_DQ SG_ 332 OBD_Sperrung_IUMPR 1000;
BA_REL_ "GenSigTimeoutTime" BU_SG_REL_ Getriebe_DQ SG_ 332 OBD_Minimum_Trip 1000;
BA_REL_ "GenSigTimeoutTime" BU_SG_REL_ Getriebe_DQ SG_ 332 OBD_Driving_Cycle 1000;
BA_REL_ "GenSigTimeoutTime" BU_SG_REL_ Getriebe_DQ SG_ 332 OBD_Warm_Up_Cycle 1000;
BA_REL_ "GenSigTimeoutTime" BU_SG_REL_ Getriebe_DQ SG_ 332 OBD_Normed_Trip 1000;
BA_REL_ "GenSigTimeoutTime" BU_SG_REL_ Getriebe_DQ SG_ 553 SOK_Motor_54_Signatur 1000;
BA_REL_ "GenSigTimeoutTime" BU_SG_REL_ Getriebe_DQ SG_ 246 TS_Faktor_Radmomente 500;
BA_REL_ "GenSigTimeoutTime" BU_SG_REL_ Getriebe_DQ SG_ 246 TS_MomRad_Soll_Summe 500;
BA_REL_ "GenSigTimeoutTime" BU_SG_REL_ Getriebe_DQ SG_ 246 TS_Allrad_Anteil_sek 500;
BA_REL_ "GenSigTimeoutTime" BU_SG_REL_ Getriebe_DQ SG_ 246 MO_Mom_Begr_Fahr_Pred 500;
BA_REL_ "GenSigTimeoutTime" BU_SG_REL_ Getriebe_DQ SG_ 1601 Motor_Code_01_CRC 5000;
BA_REL_ "GenSigTimeoutTime" BU_SG_REL_ Getriebe_DQ SG_ 1601 Motor_Code_01_BZ 5000;
BA_REL_ "GenSigTimeoutTime" BU_SG_REL_ Getriebe_DQ SG_ 1601 MO_Faktor_Momente_02 5000;
BA_REL_ "GenSigTimeoutTime" BU_SG_REL_ Getriebe_DQ SG_ 1601 MO_Kraftstoffart 5000;
VAL_ 267 MO_Fahrpedalrohwert_01 255 "Fehler" ;
VAL_ 267 MO_QBit_Fahrpedalwerte_01 0 "gueltiger_Wert" 1 "Ersatz_Init_oder_Fehlerwert" ;
VAL_ 267 MO_Fahrpedalgradient 255 "Fehler" ;
VAL_ 267 MO_Sig_Fahrpedalgradient 0 "Fahrpedalgradient positiv" 1 "Fahrpedalgradient negativ" ;
VAL_ 267 MO_rel_Saugrohrdruck 0 "Init_Ueberdruck" 63 "Fehler" ;
VAL_ 267 MO_rel_Saugrohrdruck_gem_err 0 "errechnet" 1 "gemessen" ;
VAL_ 267 MO_Moment_im_Leerlauf 0 "kein_Leergas" 1 "Leergas" ;
VAL_ 267 MO_Schubabschaltung 0 "keine_Schubabschaltung" 1 "Schubabschaltung_aktiv" ;
VAL_ 267 MO_StartStopp_StoppVorbereitung 0 "Motorstopp_nicht_in_Vorbereitung" 1 "Motorstopp_in_Vorbereitung" ;
VAL_ 267 MO_Entkopplung_Sollschlupf 125 "Notoeffnen_Anfahrelement" 126 "Init" ;
VAL_ 267 MO_temporaere_Fahrerabwesenheit 0 "nicht_erkannt" 1 "erkannt" ;
VAL_ 267 TSK_a_Soll_gradientenbegrenzt 127 "Init_oder_nicht_aktiv" ;
VAL_ 267 TSK_Status 0 "Hauptschalter_aus" 1 "Init" 2 "passiv" 3 "aktiv" 4 "Uebertreten" 5 "brake_only_Mode" 6 "reversibel_aus" 7 "irreversibel_aus" ;
VAL_ 267 TSK_v_Begrenzung_aktiv 0 "inaktiv" 1 "aktiv" ;
VAL_ 267 TSK_Standby_Anf_ESP 0 "keine_Standby_Anforderung" 1 "Standby_Anforderung" ;
VAL_ 267 TSK_Freig_Verzoeg_Anf 0 "Verzoegerungsanforderung_nicht_freigegeben" 1 "Verzoegerungsanforderung_freigegeben" ;
VAL_ 267 TSK_Limiter_ausgewaehlt 0 "kein_Limiter_ausgewaehlt" 1 "Limiter_ausgewaehlt" ;
VAL_ 267 TSK_Hauptschalter_GRA_ACC 0 "Init" 1 "Aus" 2 "Ein" 3 "Fehler" ;
VAL_ 267 TSK_SRBM_Anf_ASIL 0 "keine_SRBM_Anforderung" 1 "SRBM_Anforderung_in_ASIL_QM" 2 "SRBM_Anforderung_in_ASIL_A" 3 "SRBM_Anforderung_in_ASIL_B" 4 "SRBM_Anforderung_in_ASIL_C" ;
VAL_ 267 TSK_ax_Getriebe_02 511 "Neutralwert" ;
VAL_ 267 TSK_Zwangszusch_ESP 0 "keine_ESP_ASR_Beeinflussung" 1 "ESP_ASR_Beeinflussung" ;
VAL_ 267 TSK_Radsollmoment 65534 "Init" 65535 "Fehler" ;
VAL_ 267 TSK_Kategorie_Verzoegerungsfkt 0 "Schnittstelle_nicht_vorhanden" 1 "Kategorie_Fahrerassistenz" 2 "Kategorie_Schubverzoegerung" 3 "reserviert" ;
VAL_ 267 TSK_Notstopp_Anf 0 "Ueberwachung_aus" 1 "Ueberwachung_ein" 2 "Notstopp_ausloesen" ;
VAL_ 267 MO_Status_MinDrzEingriff 0 "kein_Eingriff" 1 "Schalteingriff" 2 "ESP_Eingriff" 3 "Achsdifferenzdrehzahl" 4 "Bauteilschutz" 5 "Rennstart_Fahrbarkeit" ;
VAL_ 267 MO_Status_MaxDrzEingriff 0 "kein_Eingriff" 1 "Schalteingriff" 2 "ESP_Eingriff" 3 "Achsdifferenzdrehzahl" 4 "Bauteilschutz" 5 "Rennstart_Fahrbarkeit" ;
VAL_ 267 MO_Status_MinDrzEingriff_sek 0 "kein_Eingriff" 1 "Schalteingriff" 2 "ESP_Eingriff" 3 "Achsdifferenzdrehzahl" 4 "Bauteilschutz" 5 "Rennstart_Fahrbarkeit" ;
VAL_ 267 MO_Status_MaxDrzEingriff_sek 0 "kein_Eingriff" 1 "Schalteingriff" 2 "ESP_Eingriff" 3 "Achsdifferenzdrehzahl" 4 "Bauteilschutz" 5 "Rennstart_Fahrbarkeit" ;
VAL_ 267 TSK_SRBM_max_Gradient 126 "Init" 127 "Fehler" ;
VAL_ 330 MO_Hochschaltdrehz 0 "keine_manuelle_Hochschaltung" 4095 "Fehler" ;
VAL_ 330 MO_Anzeige_Verbr_Einheit 0 "l_h" 1 "kg_h" ;
VAL_ 330 MO_Schaltblitz_Anz 101 "blinkende_Anzeige" 126 "Init_Funktion_nicht_aktiv" 127 "Fehler" ;
VAL_ 330 MO_Anzeige_Drehmoment 2046 "nicht_verbaut" 2047 "Fehler" ;
VAL_ 330 MO_Anzeige_Leistung 2046 "nicht_verbaut" 2047 "Fehler" ;
VAL_ 330 MO_rel_Ladedruck 255 "Fehler" ;
VAL_ 330 MO_Istgang 0 "kein_Gang_eingelegt" 1 "Gang_1" 2 "Gang_2" 3 "Gang_3" 4 "Gang_4" 5 "Gang_5" 6 "Gang_6" 7 "Gang_7" 8 "Gang_8" 9 "Gang_9" ;
VAL_ 330 MO_Sollgang 0 "keine_Empfehlung" 1 "Gang_1" 2 "Gang_2" 3 "Gang_3" 4 "Gang_4" 5 "Gang_5" 6 "Gang_6" 7 "Gang_7" 8 "Gang_8" 9 "Gang_9" 15 "Neutralgang" ;
VAL_ 330 MO_Oeldruck 254 "Init" 255 "Fehler" ;
VAL_ 330 MO_Anzeigedrehz 4095 "reserviert" ;
VAL_ 330 MO_Effizienzmodus 0 "nicht_im_Effizienz_Modus" 1 "Effizienz_Modus" ;
VAL_ 330 MO_Fehler_Oeldrucksensor 0 "kein_Fehler" 1 "Fehler" ;
VAL_ 330 MO_Schaltempf_verfbar 0 "nicht_verfuegbar" 1 "verfuegbar" ;
VAL_ 330 MO_Ladedruck 511 "Fehler" ;
VAL_ 330 MO_KVS_Ueberlauf 0 "kein Ueberlauf" 1 "Kraftstoffverbrauchsignale mindestens 1x übergelaufen" ;
VAL_ 330 MO_ePowermeter 0 "Init_keine_Anzeige" 254 "Funktion_deaktiv_Anzeige_ausgegraut" 255 "Fehler_keine_Anzeige" ;
VAL_ 330 MO_ePerformance 0 "Init" 254 "Funktion_deaktiv_Anz_ausgegraut" 255 "Fehler" ;
VAL_ 330 MO_Zust_Antrieb 0 "VM bzw. Brennstoffz. aktiv" 1 "EM aktiv" 2 "VM bzw. Brennstoffz. u. EM aktiv" 3 "Segeln oder Reku aktiv" ;
VAL_ 330 MO_Zust_Betriebsstrategie 0 "Kein Hybrid" 1 "Depleting" 2 "Soft-Depleting " 3 "Sustaining" 4 "Increasing" 5 "Fremdgesteuert" ;
VAL_ 330 Ladezustand_02 254 "Init" 255 "Fehler" ;
VAL_ 330 Ladezustand_gering 0 "keine_Anzeige" 1 "Ladezustand_gering" 2 "Batterie_fast_leer" 3 "Batterie_leer" ;
VAL_ 330 Ladezustand_kritisch 0 "keine_Anzeige" 1 "extern_laden" 2 "generatorisch_laden" 3 "extern_oder_generatorisch_laden" ;
VAL_ 330 MO_Powermeter_Elm_02 0 "nicht_verbaut" 4094 "Init" ;
VAL_ 330 MO_Powermeter 4093 "Off" ;
VAL_ 330 MO_OnePedalDriving_Warnung 0 "keine_Warnung" 1 "Warnstufe_1" ;
VAL_ 512 TSK_Wunschgeschw 1022 "keine_Anzeige" 1023 "kein_Wert_im_Speicher" ;
VAL_ 512 TSK_praediktiver_Hinweis 0 "keine_Anzeige" 1 "Vorschlag_zur_Bestaetigung" 2 "Hinweis_neuer_Setzwert" 3 "Regelung_im_Uebergang" 4 "Tempolimit_voraus" 5 "Tempolimit_erkannt" ;
VAL_ 512 TSK_naechstes_Event 0 "Init" 1 "Tempolimit_5" 2 "Tempolimit_10" 3 "Tempolimit_15" 4 "Tempolimit_20" 5 "Tempolimit_25" 6 "Tempolimit_30" 7 "Tempolimit_35" 8 "Tempolimit_40" 9 "Tempolimit_45" 10 "Tempolimit_50" 11 "Tempolimit_55" 12 "Tempolimit_60" 13 "Tempolimit_65" 14 "Tempolimit_70" 15 "Tempolimit_75" 16 "Tempolimit_80" 17 "Tempolimit_90" 18 "Tempolimit_100" 19 "Tempolimit_110" 20 "Tempolimit_120" 21 "Tempolimit_130" 22 "Tempolimit_140" 23 "Tempolimit_150" 24 "Tempolimit_160" 25 "Tempolimit_unbegrenzt" 26 "Linkskurve" 27 "Rechtskurve" 28 "Kuppe" 29 "Steigung" 30 "Gefaelle" 31 "Kreuzung" 32 "Ampel" 33 "Bahnuebergang" 34 "Ortsanfang" 35 "Kreisverkehr" 36 "naechstes_Limit_ausserh_Verfueg" 37 "Tempolimit_85" ;
VAL_ 512 TSK_Fahrzeugstatus_praed_Fkt 0 "init" 1 "Praed_Fkt_verfuegbar" 2 "Praed_Fkt_eingeschraenkt_verfueg" 3 "Praed_Fkt_nicht_verfuegbar" 4 "Praed_Fkt_Land_nicht_verfuegbar" 5 "Praed_Fkt_Auffahrt" 6 "Praed_Fkt_Abfahrt" 7 "Praed_Fkt_Regelbereich_verlassen" ;
VAL_ 512 TSK_praediktiver_Automode 0 "Automode_inaktiv" 1 "Automode_aktiv" ;
VAL_ 512 CE_StStrtDlyEmiSysPrep 0 "Startverzögerung_inaktiv" 1 "Startverzögerung_aktiv" 2 "Init" 3 "Fehler" ;
VAL_ 512 CE_StLdRdcEmiSysPrep 0 "nicht_belastbar" 1 "durch_Nebenaggregate_belastbar" 2 "voll_belastbar" 3 "Reserve" 5 "Reserve" 6 "Init" 7 "Fehler" ;
VAL_ 512 TSK_Texte 0 "kein_Text" 1 "GRA_Modus_ausgewaehlt" 2 "ACC_Modus_ausgewaehlt" 3 "Lim_Modus_ausgewaehlt" 4 "Lim_nicht_verfuegbar_ESC_passiv" 5 "GRA_nicht_verfuegbar_ESC_passiv" 6 "Lim_nicht_verfuegbar_Charisma" 7 "GRA_nicht_verfuegbar_Charisma" 8 "Lim_nicht_verfuegbar_HDC" 9 "GRA_nicht_verfuegbar_HDC" 10 "P_GRA_Modus_ausgewaehlt" 11 "P_LIM_Modus_ausgewaehlt" 12 "Bremse_ueberhitzt" 13 "kein_Laengsregler" 14 "kein_Abstandsregler" 15 "keine_Abstandsregelung" 16 "Bitte_Hauptschalter_einschalten" ;
VAL_ 512 TSK_Akustik 0 "keine_Akustik" 1 "einzelner_Warnton" 2 "dauerhafter_Warnton" ;
VAL_ 512 TSK_Texte_Primaeranz 0 "keine_Anzeige" 1 "GRA_Symbol_passiv_xxx_kmh_mph" 2 "GRA_Symbol_aktiv_xxx_kmh_mph" 3 "Bremse_ueberhitzt" 4 "Limiter_Modus_aktiviert" 5 "GRA_Modus_aktiviert" 6 "ACC_Modus_aktiviert" 7 "Opt_Geschwindigkeitswarnung" 8 "Opt_und_akustische_GeschwWarnung" 9 "Opt_GeschwWarnung_dauerhaft_mit_einmal_Akustik" 10 "Limiter_passiv_mit_Akustik" 11 "Limiter_Fehler_mit_Akustik" 12 "Limiter_Symbol_passiv_xxx_kmh_mph" 13 "Limiter_Symbol_aktiv_xxx_kmh_mph" 14 "Popup_Geschw_zu_hoch__Resume_unzulaessig" ;
VAL_ 512 TSK_Limiter_Fahrerinfo 0 "keine_Info" 1 "Limit_erreicht" 2 "Ueberschritten" 3 "Vom_Fahrer_Ueberstimmt" ;
VAL_ 512 TSK_Limiter_Anzeige 0 "Display_Anzeige_GRA_ACC" 1 "Display_Anzeige_Limiter" ;
VAL_ 512 TSK_Fahrzeugstatus_GRA 0 "GRA_verfuegbar" 1 "GRA_nicht_verfuegbar" ;
VAL_ 512 TSK_Fahrzeugstatus_Limiter 0 "Limiter_verfuegbar" 1 "Limiter_nicht_verfuegbar" ;
VAL_ 512 MO_Motorlaufwarnung 0 "keine_Anzeige" 1 "Anforderung_Motorlaufwarnung" ;
VAL_ 512 TSK_naechstes_Event_Einheit 0 "kmh" 1 "mph" ;
VAL_ 512 TSK_Status_Anzeige 0 "Hauptschalter_aus" 1 "Init" 2 "passiv" 3 "aktiv" 4 "Uebertreten" 5 "Limitiierung_aktiv" 6 "reversibel_aus" 7 "irreversibel_aus" ;
VAL_ 512 MO_Sperrung_FahrPr_BZS 0 "keine Sperrung" 1 "Sperrung BZS1" 2 "Sperrung BZS2" 4 "Sperrung BZS3" 8 "Sperrung BZS4" 16 "Sperrung BZS5" 32 "Sperrung BZS6" 64 "Sperrung BZS7" 128 "Sperrung BZS8" ;
VAL_ 512 MO_Rampenzeit_Generator_Anf 0 "0_sec" 1 "1_sec" 2 "2_sec" 3 "3_sec" 4 "4_sec" 5 "5_sec" 6 "6_sec" 7 "7_sec" 8 "8_sec" 9 "9_sec" 10 "reserviert" 11 "reserviert" 12 "reserviert" 13 "reserviert" 14 "reserviert" 15 "keine_Anforderung" ;
VAL_ 512 MO_Prio_MAX_Wunschdrehzahl 0 "Wunsch" 1 "Zwang" ;
VAL_ 512 MO_Prio_MIN_Wunschdrehzahl 0 "Wunsch" 1 "Zwang" ;
VAL_ 512 MO_Luftpfad_aktiv 0 "kein Eingriff oder nur Eingriff über Zündpfad" 1 "Eingriff über Luftpfad" ;
VAL_ 512 MO_v_Begrenz_Aktivierbar 0 "V-Begrenzung nicht möglich" 1 "V-Begrenzung möglich" ;
VAL_ 512 MO_Charisma_FahrPr 0 "keine_Funktion" 1 "Programm_1" 2 "Programm_2" 3 "Programm_3" 4 "Programm_4" 5 "Programm_5" 6 "Programm_6" 7 "Programm_7" 8 "Programm_8" 9 "Programm_9" 10 "Programm_10" 11 "Programm_11" 12 "Programm_12" 13 "Programm_13" 14 "Programm_14" 15 "Programm_15" ;
VAL_ 512 MO_Charisma_Status 0 "Init" 1 "verfuegbar" 2 "nicht_verfuegbar" 3 "asynchron_durch_Fahrerwunsch" ;
VAL_ 512 MO_StSt_Charisma_FahrPr 0 "keine_Funktion" 1 "Programm_1" 2 "Programm_2" 3 "Programm_3" 4 "Programm_4" 5 "Programm_5" 6 "Programm_6" 7 "Programm_7" 8 "Programm_8" 9 "Programm_9" 10 "Programm_10" 11 "Programm_11" 12 "Programm_12" 13 "Programm_13" 14 "Programm_14" 15 "Programm_15" ;
VAL_ 512 MO_StSt_Charisma_Status 0 "Init" 1 "verfuegbar" 2 "nicht_verfuegbar" 3 "asynchron_durch_Fahrerwunsch" ;
VAL_ 512 MO_BZS_Charisma_FahrPr 0 "keine_Funktion" 1 "Programm_1" 2 "Programm_2" 3 "Programm_3" 4 "Programm_4" 5 "Programm_5" 6 "Programm_6" 7 "Programm_7" 8 "Programm_8" 9 "Programm_9" 10 "Programm_10" 11 "Programm_11" 12 "Programm_12" 13 "Programm_13" 14 "Programm_14" 15 "Programm_15" ;
VAL_ 512 MO_BZS_Charisma_Status 0 "Init" 1 "verfuegbar" 2 "nicht_verfuegbar" 3 "asynchron_durch_Fahrerwunsch" ;
VAL_ 512 MO_NGS_Position 0 "Neutralposition_nicht_erkannt" 1 "Neutralposition_erkannt" ;
VAL_ 512 MO_NGS_Status 0 "nicht_verbaut" 1 "nicht_plausibilisiert" 2 "plausibilisiert" 3 "Fehler" ;
VAL_ 512 MO_v_Begrenzung_Niveau 0 "keine_Begrenzung_aktiv" 1 "Sicherheitsbegrenzung_1_aktiv" 2 "Sicherheitsbegrenzung_2_aktiv" 3 "Komfortbegrenzung_aktiv" ;
VAL_ 512 MO_Anzeige_Rekuperation 0 "Init_und_nicht_verbaut" ;
VAL_ 512 PEA_Fortschrittsanzeige 127 "Neutralwert" ;
VAL_ 512 MO_Anzeige_Fahrbereitschaft 0 "OFF" 1 "READY" ;
VAL_ 512 MO_Boost_verfuegbar 0 "Init" 253 "Nicht_verbaut" 254 "Funktion_deaktiv" 255 "Fehler" ;
VAL_ 512 MO_Overboost 0 "inaktiv" 1 "aktiv" ;
VAL_ 512 MO_Boost_aktiv 0 "kein_Boost_aktiv" 1 "Boost_aktiv" ;
VAL_ 512 MO_Anzeige_Betriebsmodus 0 "Init_keine_Anzeige" 1 "EV" 2 "Auto" 3 "Hold" 4 "Charge" 5 "GTE" 6 "ECO" 7 "SPORT" 8 "Auto_praediktiv" 9 "Manuell_SOC_erhoehen" 10 "Manuell_SOC_halten" 11 "Manuell_SOC_verringern" ;
VAL_ 512 PEA_Hinweis 0 "keine_Anzeige" 1 "Anzeige_Fusssymbol_1" 2 "Anzeige_Fusssymbol_2" 3 "Anzeige_Auskuppeln" ;
VAL_ 512 PEA_Ereignisanzeige 0 "keine_Anzeige" 1 "Linkskurve_voraus" 2 "Rechtskurve_voraus" 3 "Kreuzung_voraus" 4 "Gefaelle_voraus" 5 "Kreisverkehr_voraus" 6 "Fahrzeug_voraus" 7 "Tempolimit_voraus" 8 "Ereignis_voraus" 9 "Autobahnabfahrt_voraus" 10 "Autobahnauffahrt_voraus" 11 "Abbiegung_links_voraus" 12 "Abbiegung_rechts_voraus" 13 "Ortseinfahrt_voraus" 14 "Autobahnabfahrt_links_voraus" ;
VAL_ 512 PEA_Ereignisanzeige_temporaer 0 "keine_Anzeige" 1 "Anzeige_temporaer" ;
VAL_ 512 PEA_Abschalttexte 0 "keine_Anzeige" 1 "PEA_ausserhalb_Einsatzgebiet" 2 "PEA_temporaer_nicht_verfuegbar" 3 "PEA_vom_Fahrer_deaktiviert" ;
VAL_ 512 PEA_Zielgeschw_Einheit 0 "km_h" 1 "mph" ;
VAL_ 512 PEA_Zielgeschw 0 "keine_Anzeige" 1 "Wert_5" 2 "Wert_10" 3 "Wert_15" 4 "Wert_20" 5 "Wert_25" 6 "Wert_30" 7 "Wert_35" 8 "Wert_40" 9 "Wert_45" 10 "50" 11 "Wert_55" 12 "Wert_60" 13 "Wert_65" 14 "Wert_70" 15 "Wert_75" 16 "Wert_80" 17 "Wert_85" 18 "Wert_90" 19 "Wert_95" 20 "Wert_100" 21 "Wert_105" 22 "Wert_110" 23 "Wert_115" 24 "Wert_120" 25 "Wert_125" 26 "Wert_130" 27 "Wert_140" 28 "Wert_150" 29 "Wert_160" ;
VAL_ 512 MO_Antriebsstrang_Warnung_HS 0 "Keine_Anzeige" 1 "Fehlereskalationsstufe_I" 2 "Fehlereskalationsstufe_II" 3 "Fehlereskalationsstufe_III" ;
VAL_ 512 MO_Text_Aktivierung_Antrieb 0 "keine_Anzeige" 1 "Ladestecker_nicht_fahrbereit" 2 "erneute_Aktivierung_erforderlich" 3 "Warten_Antrieb_wird_aktiviert" 4 "zum_Fahren_Bremse_und_Fahrstufe" 5 "h2_Tankklappe_nicht_fahrbereit" 6 "zum_Starten_Bremse_treten" 7 "zum_Starten_Kupplung_treten" 15 "Init" ;
VAL_ 512 ISA_Tempolimit_Regelung 0 "Init" 1 "Tempolimit_5" 2 "Tempolimit_10" 3 "Tempolimit_15" 4 "Tempolimit_20" 5 "Tempolimit_25" 6 "Tempolimit_30" 7 "Tempolimit_35" 8 "Tempolimit_40" 9 "Tempolimit_45" 10 "Tempolimit_50" 11 "Tempolimit_55" 12 "Tempolimit_60" 13 "Tempolimit_65" 14 "Tempolimit_70" 15 "Tempolimit_75" 16 "Tempolimit_80" 17 "Tempolimit_90" 18 "Tempolimit_100" 19 "Tempolimit_110" 20 "Tempolimit_120" 21 "Tempolimit_130" 22 "Tempolimit_140" 23 "Tempolimit_150" 24 "Tempolimit_160" 25 "Tempolimit_unbegrenzt" 26 "Linkskurve" 27 "Rechtskurve" 28 "Kuppe" 29 "Steigung" 30 "Gefaelle" 31 "Kreuzung" 32 "Ampel" 33 "Bahnuebergang" 34 "Ortsanfang" 35 "Kreisverkehr" 36 "naechstes_Limit_ausserh_Verfueg" ;
VAL_ 512 PEA_Fahrerinfo 0 "keine_Anzeige" 1 "Anzeige_Fahreruebernahme_hart" 2 "Anzeige_Fahreruebernahme_medium" 3 "Anzeige_Fahreruebernahme_soft" 4 "Anzeige_Fahreruebernahme_Popup" 5 "Fehleranzeige_FAS_Sammelmeldung" ;
VAL_ 512 CE_CtrPrpPrep 0 "Ready" 1 "Ready_in_1" 2 "Ready_in_2" 3 "Ready_in_3" 7 "keine_Anzeige" ;
VAL_ 512 CE_PrctPrpPrep 125 "Keine_Anzeige" 126 "InitWert" 127 "Fehler" ;
VAL_ 512 MO_Kuehlmitttel_Sensor_AGB2 0 "OK" 1 "Kuehlmittel_unter_min" ;
VAL_ 512 CE_FlgEmiColdLmp 0 "Lamp_off" 1 "Lamp_on" ;
VAL_ 512 CE_FlgEmiColdTxt 0 "kein_Text" 1 "Textanzeige_Leistungsbegrenzung" ;
VAL_ 512 CE_FlgHybModAdvi 0 "kein_Text" 1 "Textanzeige_Hybridmodus_waehlen" ;
VAL_ 512 CE_FlgPTLimPrfTxt 0 "kein_Text" 1 "Textanzeige_Leistungsbegrenzung" ;
VAL_ 512 TSK_praed_Wunschgeschw 1022 "keine_Anzeige" 1023 "kein_praed_Setzwert_verfuegbar" ;
VAL_ 332 MO_Anforderung_HMS 0 "keine_Anforderung" 1 "halten" 2 "parken" 3 "halten_Standby" 4 "anfahren" 5 "Loesen_ueber_Rampe" 7 "HMS_uebernehmen" ;
VAL_ 332 FoD_DTC_TSK_GRA 0 "Kein_DTC" 1 "DTC_vorhanden_oder_in_Quali" ;
VAL_ 332 TSK_vMax_aktuell 254 "kein_Limit_aktiv" 255 "Init" ;
VAL_ 332 ISA_Status 0 "ISA_nicht_aktiv" 1 "Init" 2 "ISA_degradiert" 3 "ISA_aktiv" 4 "reserviert" 5 "reserviert" 6 "reserviert" 7 "reserviert" ;
VAL_ 332 ISA_Regelung_aktiv 0 "ISA_Regelung_nicht_aktiv" 1 "ISA_Regelung_aktiv" ;
VAL_ 332 ISA_Tempolimitwarnung 0 "ISA_keine_Warnung" 1 "ISA_Warnung_aktiv" ;
VAL_ 332 MO_Red_El_Fahrleistung 0 "keine_Anzeige" 1 "mehr_als_20Prcnt_Red" 2 "Reserve_1" 3 "Reserve_2" 4 "unter_GBB_Schwelle_Anhaenger" 5 "unter_GBB_Schwelle" 6 "unter_minimal_Schwelle" 7 "kein_Vortrieb" ;
VAL_ 332 TSK_Status_EA 0 "Aus" 1 "Init_oder_nicht_verbaut" 3 "Aktiv" 4 "Uebertreten" 5 "Abschaltung_laeuft" 6 "Reversibel_aus" 7 "Fehler" ;
VAL_ 332 FoD_DTC_TSK_ACC 0 "Kein_DTC" 1 "DTC_vorhanden_oder_in_Quali" ;
VAL_ 332 TSK_ACC_FoD_Status 0 "default" 1 "nicht_aktiv" 2 "aktiv" 3 "nicht_genutzt" ;
VAL_ 332 TSK_GRA_FoD_Status 0 "default" 1 "nicht_aktiv" 2 "aktiv" 3 "nicht_genutzt" ;
VAL_ 332 TSK_vMax_Fahrerassistenz 511 "Init_ungueltig_keine_Beschraenkung" ;
VAL_ 332 TSK_Einheit_vMax_Fahrerassistenz 0 "kmh" 1 "mph" ;
VAL_ 332 TSK_Status_PLA 0 "Aus_Funktionsbereit" 1 "Init_oder_nicht_verbaut" 2 "aktivierbar" 3 "aktiv" 5 "Abschaltung_laeuft" 6 "reversibel_aus" 7 "Fehler" ;
VAL_ 332 TSK_aktives_System 0 "keine_Funktion_aktiv" 1 "GRA_ACC" 2 "ARA" 3 "Speedlimiter" 4 "IPA" 5 "PLA" 6 "PEA_Ausrollassistent" 7 "EA" ;
VAL_ 332 TSK_erhoehter_Fahrwiderstand 0 "kein_erhoehter_Fahrwiderstand" 1 "erhoehter_Fahrwiderstand" ;
VAL_ 332 TSK_Anf_Antriebsmoment 0 "keine_Anforderung" 1 "Anforderung_aktiv" ;
VAL_ 332 TSK_Status_ARA 0 "Aus" 1 "Init_oder_nicht_verbaut" 2 "aktivierbar" 3 "aktiv" 5 "abschaltung_laeuft" 6 "reversibel_aus" 7 "Fehler" ;
VAL_ 332 TSK_Status_IPA 0 "Aus_Funktionsbereit" 1 "Init_oder_nicht_verbaut" 2 "aktivierbar" 3 "aktiv" 4 "Fahreruebernahme_angefordert" 5 "Abschaltung_laueft" 6 "reversibel_aus" 7 "Fehler" ;
VAL_ 332 TSK_aktives_System_02 0 "keine_Funktion_aktiv" 1 "GRA_ACC" 2 "ARA" 3 "Speedlimiter" 4 "IPA" 5 "PLA" 6 "PEA_Ausrollassistent" 7 "EA" 8 "Staupilot" 9 "RHP" ;
VAL_ 332 TSK_Status_RHP 0 "off" 1 "init" 2 "standby" 3 "active" 4 "driver_override" 5 "shutdown" 6 "reversible_failure" 7 "irreversible_failure" ;
VAL_ 332 MO_Kuppl_betaetigt 0 "Kupplung_nicht_betaetigt" 1 "Kupplung_betaetigt" ;
VAL_ 332 MO_QBit_Kuppl_betaetigt 0 "gueltiger_Wert" 1 "Ersatz_Init_oder_Fehlerwert" ;
VAL_ 332 MO_Klima_Regelmodus 0 "Init" 1 "Regelmodus_1" 2 "Regelmodus_2" 3 "Regelmodus_3" ;
VAL_ 332 MO_Fahrbereitschaft 0 "Fahrzykl_inaktiv__kein_Antrieb" 1 "Fahrzykl_aktiv__kein_Antrieb" 2 "Fahrzykl_aktiv__Antrieb_moeglich" ;
VAL_ 332 MO_Freilauf_Info 0 "Freilauf_freigegeben" 1 "Weiches_Veto_uebertippbar" 2 "Hartes_Veto_Abbruch" 3 "Freilauf_Anforderung" ;
VAL_ 332 CE_FlgLnchCtlPreCnd 0 "not_fulfilled" 1 "fulfilled" ;
VAL_ 332 MO_Krit_Heckobjekt 0 "Init_kein_relevantes_Objekt" 1 "Entfernung_grosser_Abstand" 2 "Annaeherung_grosser_Abstand" 3 "Entfernung_geringer_Abstand" 4 "Annaeherung_geringer_Abstand" 7 "Fehler" ;
VAL_ 332 MO_NGS_Gangpos 0 "nicht_bedient" 1 "1_3_oder_5" 2 "2_4_6_oder_R" 3 "R" 4 "Neutralposition" 5 "Zwischenposition" 6 "Sensor_temp_nicht_verfuegbar" 7 "Fehler" ;
VAL_ 332 MO_Freilauf_Status 0 "Freilauf_inaktiv_aber_moeglich" 1 "Freilauf_aktiv" 2 "Freilauf_nicht_moegl_1Verhinderer" 3 "Freilauf_nicht_moegl_gr_1Verhinderer" 7 "Fehler" ;
VAL_ 332 MO_EBoost_verf_praed 0 "Init_oder_nicht_verfuegbar" 1 "EBoost_kurzzeit_verfuegbar" 2 "EBoost_langzeit_verfuegbar" ;
VAL_ 332 MO_Heckspoiler_Anf 0 "nicht_angefordert" 1 "angefordert" ;
VAL_ 332 MO_eLaunch_verf 0 "Init" 1 "nicht_verfuegbar" 2 "verfuegbar" ;
VAL_ 332 MO_Positionierung_aktiv 0 "keine_Positionierung_aktiv" 1 "Positionierung_aktiv" ;
VAL_ 332 MO_Veto_Launchcontrol 0 "kein_Veto__LC_moeglich" 1 "Veto__LC_nicht_moeglich" ;
VAL_ 332 MO_Startwunsch 0 "kein_Startwunsch" 1 "Startwunsch" ;
VAL_ 332 MO_LaunchControl 0 "nicht_verfuegbar" 1 "verfuegbar" ;
VAL_ 332 MO_UBE_Hybrid_Reserve 1023 "Init" ;
VAL_ 332 OBDProtocol_req 0 "OBDonUDS" 1 "OBDclassic" 254 "Init" 255 "Fehler" ;
VAL_ 332 MO_Servicemodus 0 "nicht_aktiv" 1 "Service_Mode_1" 2 "Service_Mode_2" 3 "Service_Mode_3" 4 "Service_Mode_4" 5 "Service_Mode_5" 6 "Service_Mode_6" 7 "Service_Mode_7" 8 "Service_Mode_8" 9 "Service_Mode_9" 10 "Service_Mode_10" 11 "Service_Mode_11" 12 "Service_Mode_12" 13 "Service_Mode_13" 14 "Service_Mode_14" 15 "Service_Mode_15" ;
VAL_ 332 OBD_ClearMem_Inhibit 0 "FSP_Loeschen_zulaessig" 1 "FSP_Loeschen_nicht_zulaessig" ;
VAL_ 332 OBD_Sperrung_Kaltstart_Denom 0 "EVAP_Berechnung_freigegeben" 1 "EVAP_Berechnung_gesperrt" ;
VAL_ 332 MO_QBit_Aussen_Temp 0 "gueltiger_Wert" 1 "Ersatz_Init_oder_Fehlerwert" ;
VAL_ 332 OBD_Sperrung_IUMPR 0 "IUMPR_Berechnung_freigegeben" 1 "IUMPR_Berechnung_gesperrt" ;
VAL_ 332 OBD_Kaltstart_Denominator 0 "Denominator_nicht_hochzaehlen" 1 "Bedingungen_zum_Inkr_des_Kaltstart_Denom_erf" ;
VAL_ 332 OBD_Minimum_Trip 0 "kein_Min_Normed_Trip" 1 "Min_Normed_Trip" ;
VAL_ 332 OBD_Driving_Cycle 0 "kein_Driving_Cycle_erkannt" 1 "Driving_Cycle_erkannt" ;
VAL_ 332 OBD_Warm_Up_Cycle 0 "kein_Warm_Up_Cycle_erkannt" 1 "Warm_Up_Cycle_erkannt" ;
VAL_ 332 OBD_Normed_Trip 0 "kein_Normed_Trip" 1 "Normed_Trip" ;
VAL_ 332 MO_EMG_Min_Leistung 2046 "Init" 2047 "Fehler" ;
VAL_ 332 MO_EMG_Max_Leistung 2046 "Init" 2047 "Fehler" ;
VAL_ 332 MO_MVEM_MinLeistung_MVVerbrauch 1022 "Init" 1023 "Fehler" ;
VAL_ 332 MO_MVEM_MaxLeistung_MVVerbrauch 1022 "Init" 1023 "Fehler" ;
VAL_ 332 MO_UBE_Reserve 1023 "Init" ;
VAL_ 332 OBD_Aussen_Temp_gef 254 "Initwert" 255 "Fehler" ;
VAL_ 246 TS_Faktor_Radmomente 0 "Faktor_1NM" 1 "Faktor_2NM" 2 "Faktor_3NM" 3 "Faktor_4NM" ;
VAL_ 246 TS_Status_MomRad_Ist 0 "FuSi_hohe_Genauigkeit" 1 "FuSi_niedrige_Genauigkeit" 2 "QM_fehlerfrei" 3 "QM_mit_Fehlern" ;
VAL_ 246 TS_MomRad_verfuegb_maxReku_Summe 4094 "Init" ;
VAL_ 246 TS_MomRad_Ist 8190 "Init" ;
VAL_ 246 TS_MomRad_Soll_Summe 8190 "Init" ;
VAL_ 246 TS_MomRad_Wunsch 8190 "Init" ;
VAL_ 246 TS_MomRad_Wunsch_sek 8190 "Init" ;
VAL_ 246 TS_MomRad_verfuegb_max 4094 "Init" ;
VAL_ 246 TS_MomRad_verfuegb_max_sek 4094 "Init" ;
VAL_ 246 TS_MomRad_verfuegb_maxReku 4094 "Init" ;
VAL_ 246 TS_MomRad_verfuegb_maxReku_sek 4094 "Init" ;
VAL_ 246 TS_MomRad_Ist_sek 8190 "Init" ;
VAL_ 246 TS_Allrad_Anteil_sek 510 "Init" 511 "Fehler" ;
VAL_ 246 FDR_Allrad_Anteil_max_sek 510 "Init" 511 "Fehler" ;
VAL_ 246 FDR_Allrad_Anteil_min_sek 510 "Init" 511 "Fehler" ;
VAL_ 246 FDR_MomRad_Eingriff 8190 "Init" 8191 "Fehler" ;
VAL_ 246 FDR_Status_Eingriff 0 "kein_Eingriff" 1 "Eingriff" ;
VAL_ 246 FDR_MomRad_Eingriff_sek 8190 "Init" 8191 "Fehler" ;
VAL_ 246 FDR_Status_Eingriff_sek 0 "kein_Eingriff" 1 "Eingriff" ;
VAL_ 246 MO_Mom_Begr_Fahr_Pred 510 "Init" ;
VAL_ 246 FDR_Zwangszusch_ESP 0 "keine_ESP_ASR_Beeinflussung" 1 "ESP_ASR_Beeinflussung" ;
VAL_ 246 MO_EMG_Sollmodus 0 "Standby" 1 "Momentenreg" 2 "Int_Drehzahlreg" 3 "Spannungsreg" 4 "Spannungsreg_Batt_Ab" 6 "Kalibrierung" 8 "Freilauf" 9 "Momentenreg_Komfortfunktionen" 10 "Asynchrones_Bremsen" 11 "Positionieren" 12 "Int_Diagnose" 15 "Init" ;
VAL_ 246 TS_Status_DrzReg 0 "Init" 1 "Verfuegbar" 2 "Fehler_ohne_DrzReg_Abweichung" 3 "Fehler_mit_DrzReg_Abweichung" ;
VAL_ 246 TS_Status_DrzReg_sek 0 "Init" 1 "Verfuegbar" 2 "Fehler_ohne_DrzReg_Abweichung" 3 "Fehler_mit_DrzReg_Abweichung" ;
VAL_ 246 MO_EMG_SollDrehzahl 32767 "Init" ;
VAL_ 246 MO_EMG_Max_Momentengradient 125 "keine_Beschraenkung" 126 "Init" 127 "Reserve" ;
VAL_ 246 MO_EMG_Generator_Leistung 2046 "Init" 2047 "Fehler" ;
VAL_ 246 MO_EMG_Max_Strom_Lim 2046 "Init" 2047 "Fehler" ;
VAL_ 246 MO_EMG_Min_Strom_Lim 2046 "Init" 2047 "Fehler" ;
VAL_ 246 MO_EMG_Max_Spannung_Lim 254 "Init" 255 "Fehler" ;
VAL_ 246 MO_EMG_Min_Spannung_Lim 254 "Init" 255 "Fehler" ;
VAL_ 246 MO_EMG_SollMoment_02 65534 "Init" ;
VAL_ 246 MO_EMG_Sollspannung 254 "Init" 255 "Fehler" ;
VAL_ 190 MO_EM1_MinDrehzahl 16383 "Init" ;
VAL_ 190 MO_EM1_MaxDrehzahl 16383 "Init" ;
VAL_ 190 MO_EM1_DynLimit_AR 255 "Init" ;
VAL_ 190 MO_EM1_Periode_AR 255 "Init" ;
VAL_ 190 MO_EM1_SollMoment 4094 "Init" ;
VAL_ 190 MO_EM1_Sollmodus 0 "Standby" 1 "Momentenreg" 2 "Int_Drehzahlreg" 3 "Spannungsreg" 4 "Ext_Drehzahlreg" 6 "Kalibrierung" 7 "Sonderbremsbetrieb" 8 "Freilauf" 9 "Autonome_Synchronisation" 15 "Initialisierung" ;
VAL_ 190 MO_EM1_Min_Leistung 16382 "Init" ;
VAL_ 190 MO_EM1_Max_Leistung 16382 "Init" ;
VAL_ 190 MO_EM1_Min_Strom_Lim 8190 "Init" ;
VAL_ 190 MO_EM1_Max_Strom_Lim 8190 "Init" ;
VAL_ 190 MO_EM1_AR_Anf 0 "AR_aus" 2 "AR_D2T2" 3 "AR_RDR" 4 "AR_IRDR" ;
VAL_ 190 MO_EM1_Kp_AR 511 "Init" ;
VAL_ 190 MO_EM1_SollSpannung 4095 "Init" ;
VAL_ 190 MO_CluEng_Set 0 "Init" 1 "offen" 2 "geschlossen" 3 "geschlossen_Notbetrieb" ;
VAL_ 190 MO_EM2_MinDrehzahl 16383 "Init" ;
VAL_ 190 MO_EM2_MaxDrehzahl 16383 "Init" ;
VAL_ 190 MO_EM2_DynLimit_AR 255 "Init" ;
VAL_ 190 MO_EM2_Periode_AR 255 "Init" ;
VAL_ 190 MO_EM2_SollMoment 4094 "Init" 4095 "Fehler" ;
VAL_ 190 MO_EM2_Sollmodus 0 "Standby" 1 "Momentenreg" 2 "Int_Drehzahlreg" 3 "Spannungsreg" 4 "Ext_Drehzahlreg" 6 "Kalibrierung" 7 "Sonderbremsbetrieb" 8 "Freilauf" 9 "Autonome_Synchronisation" 15 "Initialisierung" ;
VAL_ 190 MO_EM2_Min_Leistung 16382 "Init" ;
VAL_ 190 MO_EM2_Max_Leistung 16382 "Init" ;
VAL_ 190 MO_EM2_Min_Strom_Lim 8190 "Init" ;
VAL_ 190 MO_EM2_Max_Strom_Lim 8190 "Init" ;
VAL_ 190 MO_EM2_AR_Anf 0 "AR_aus" 2 "AR_D2T2" 3 "AR_RDR" 4 "AR_IRDR" ;
VAL_ 190 MO_EM2_Kp_AR 511 "Init" ;
VAL_ 190 MO_EM2_SollSpannung 4095 "Init" ;
VAL_ 190 MO_CluAxs_Set 0 "Init" 1 "offen" 2 "geschlossen" 3 "geschlossen_Notbetrieb" ;
VAL_ 190 MO_DC_Max_Strom_HV 255 "Init" ;
VAL_ 190 MO_DC_SollSpannung_HV 255 "Init" ;
VAL_ 190 MO_EM1_Max_Moment 4094 "Init" ;
VAL_ 190 MO_EM1_Min_Moment 4094 "Init" ;
VAL_ 190 MO_EM2_Max_Moment 4094 "Init" 4095 "Fehler" ;
VAL_ 190 MO_EM2_Min_Moment 4094 "Init" 4095 "Fehler" ;
VAL_ 2463978666 MO_EM1_Min_Spannung_Lim 1022 "Init" ;
VAL_ 2463978666 MO_EM1_Max_Spannung_Lim 1022 "Init" ;
VAL_ 2463978666 MO_EM1_Min_Leistung_Gesamt 8190 "Init" ;
VAL_ 2463978666 MO_EM1_Max_Leistung_Gesamt 8190 "Init" ;
VAL_ 2463978666 MO_EM2_Min_Leistung_Gesamt 8190 "Init" ;
VAL_ 2463978666 MO_EM2_Max_Leistung_Gesamt 8190 "Init" ;
VAL_ 2463978666 MO_EM2_Min_Spannung_Lim 1022 "Init" ;
VAL_ 2463978666 MO_EM2_Max_Spannung_Lim 1022 "Init" ;
VAL_ 2463978666 MO_EM1_Generator_Leistung 254 "Init" 255 "Fehler" ;
VAL_ 2463978666 MO_EM2_Generator_Leistung 254 "Init" 255 "Fehler" ;
VAL_ 2463978666 MO_Verbrauch_EM_Ges_Ueberlauf 0 "kein_Ueberlauf" 1 "Ueberlauf_Verbrauchssignal" ;
VAL_ 2463978666 MO_Rekuperation_EM_Ges_Ueberlauf 0 "kein_Ueberlauf" 1 "Ueberlauf_Reku_Leistungssignal" ;
VAL_ 2463978666 MO_Drehzahl_EM 8190 "Init_nichtverbaut" 8191 "Fehler" ;
VAL_ 2463978666 MO_Uebersetzung_EM 0 "keine_sichere_Uebertragung" 1022 "Init_nichtverbaut" 1023 "Fehler" ;
VAL_ 2463978666 MO_Drehzahl_EM_sek 8190 "Init_nichtverbaut" 8191 "Fehler" ;
VAL_ 2463978666 MO_Uebersetzung_EM_sek 0 "keine_sichere_Uebertragung" 1022 "Init" 1023 "Fehler" ;
VAL_ 2463978666 MO_TNW_Min_Spannung_Lim 1022 "Init" ;
VAL_ 2463978666 MO_TNW_Max_Spannung_Lim 1022 "Init" ;
VAL_ 2331595982 PTUIPwrm_PrctPwrSysCur 4094 "nicht_vorhanden" 4095 "Init" ;
VAL_ 2331595982 PTUIPwrm_PrctPwrElDrvCur 4094 "nicht vorhanden" 4095 "Init" ;
VAL_ 2331595982 PTHyDrA_StAcv 0 "aus_keine_Anzeige" 1 "inaktiv" 2 "aktiv" 3 "Init" ;
VAL_ 2331595982 PTUIPwrm_StAcv 0 "aus_keine_Anzeige" 1 "inaktiv" 2 "aktiv" 3 "Init" ;
VAL_ 2331595982 PTHyDrA_PrctUtilElDrv 2046 "NotAvailable" 2047 "Init" ;
VAL_ 2331595982 PTUIPwrm_PrctPwrGnrMaxUse 2046 "nicht_vorhanden" 2047 "Init" ;
VAL_ 2331595982 PTUIPwrm_PrctPwrMotElMaxUse 2046 "nicht vorhanden" 2047 "Init" ;
VAL_ 2331595982 PTUIPwrm_FacPwrDyn 126 "nicht_vorhanden" 127 "Init" ;
VAL_ 2331595982 PTUIPwrm_PrctPwrMotMaxUse 2046 "nicht_vorhanden" 2047 "Init" ;
VAL_ 2331595982 PTUIPwrm_PrctBoostAvl 1022 "nicht_vorhanden" 1023 "InitWert" ;
VAL_ 2331595982 PTUIPwrm_PrctPwrElBoostCur 1022 "nicht_vorhanden" 1023 "InitWert" ;
VAL_ 2331595982 PTUIPwrm_PrctPwrElBoostMaxUse 1022 "nicht_vorhanden" 1023 "InitWert" ;
VAL_ 2331595982 PTUIPwrm_PwrElBoostNom 1022 "nicht_vorhanden" 1023 "Init" ;
VAL_ 2331595982 PTUIPwrm_PrctPwrEcoMaxUse 2046 "nicht_vorhanden" 2047 "Init" ;
VAL_ 2331595982 PTUIPwrm_PrctPwrSysMaxUseTemp 2046 "nicht_vorhanden" 2047 "Init" ;
VAL_ 2589283946 PTUIPwrm_PwrMotElNom 2046 "nicht_vorhanden" 2047 "Init" ;
VAL_ 2589283946 PTUIPwrm_PwrGnrNom 2046 "nicht_vorhanden" 2047 "Init" ;
VAL_ 2589283946 PTUIPwrm_PwrSysMotNomDisp 2046 "nicht_vorhanden" 2047 "Init" ;
VAL_ 2589284069 MO_Beladungsstufe_OPF 0 "Stufe_0" 1 "Stufe_1" 2 "Stufe_2" 3 "Stufe_3" 4 "Stufe_4" 5 "Stufe_5" 6 "Stufe_6" 7 "Stufe_7" ;
VAL_ 1601 MO_Faktor_Momente_02 0 "nicht_belegt" ;
VAL_ 1601 MO_Hybridfahrzeug 0 "kein_Hybridfahrzeug" 1 "Mild_Hybrid" 2 "Full_Hybrid" 3 "PlugIn_Hybrid" ;
VAL_ 1601 MO_Getriebe_Code 0 "Init" 2 "DL501" 3 "DL800" 4 "VL381" 5 "DL382_Front" 6 "DL382_Allrad" 7 "DL702" 8 "AL552_Allrad" 9 "AL552_Front" 10 "AL651" 11 "AL551__AL951__AL1000_8A" 12 "PDK_PAG" 13 "AL551_Hybrid" 15 "Handschalter_konventionell" 16 "AQ250_160" 17 "AQ450" 18 "DQ200" 19 "DQ250" 20 "DQ500" 21 "SQ100" 22 "SQ200" 23 "DQ400E" 24 "DQ381" 25 "AL550" 26 "AQ300" 31 "DL800E" 32 "Single_Gear__ohne_GSG_WH_am_MSG" 33 "EQ550_2P" ;
VAL_ 1601 MO_StartStopp_Codiert 0 "Start_Stopp_nicht_verbaut" 1 "Start_Stopp_verbaut" ;
VAL_ 1601 MO_Anzeige_StSt_gueltig 0 "MO_Text_Motorstart_gueltig" 1 "Signale_MO_Anzeige_StSt_gueltig" ;
VAL_ 1601 MO_Anzahl_Zyl 0 "kein_Zylinder" 1 "1_Zylinder" 2 "2_Zylinder" 3 "3_Zylinder" 4 "4_Zylinder" 5 "5_Zylinder" 6 "6_Zylinder" 7 "7_Zylinder" 8 "8_Zylinder" 9 "9_Zylinder" 10 "10_Zylinder" 11 "11_Zylinder" 12 "12_Zylinder" 13 "15_Zylinder" 14 "16_Zylinder" 15 "18_Zylinder" ;
VAL_ 1601 MO_Kraftstoffart 0 "Diesel" 1 "Benzin_inkl_E25_E85" 2 "CNG" 3 "LPG" 4 "Wasserstoff" 5 "E100_Ethanol" 15 "kein_Verbrennungskraftstoff" ;
VAL_ 1601 MO_Ansaugsystem 0 "Turbo" 1 "Sauger" ;
VAL_ 1601 MO_OBD_Typ 0 "NoOBD_RdW" 1 "EOBD" 2 "US_OBD" 3 "reserviert" ;
VAL_ 1601 MO_DPF_verbaut 0 "kein_DPF_verbaut" 1 "DPF_verbaut" ;
VAL_ 1601 TSK_Codierung 0 "kein_Fahrgeschwindigkeitsregler" 1 "GRA" 2 "GRA_Plus" 3 "Basis_ACC" 4 "ACC_Follow_to_Stop" 5 "ACC_Stop_and_Go" 7 "Codierung_in_Plausibilisierungsphase" ;
VAL_ 391 EV_Rekuperationsstufe 0 "keine_Anzeige" 1 "1" 2 "2" 3 "3" 4 "4" 5 "5" ;
VAL_ 391 MO_Waehlpos 0 "Init_nicht_unterstuetzt" 1 "reserviert" 2 "P" 3 "R" 4 "N" 5 "D" 6 "B" 7 "Fehler" ;
VAL_ 391 MO_Fehler_NTKreis 0 "kein_Fehler" 1 "Fehler" ;
VAL_ 391 MO_Fehler_Notabschaltung_Klima 0 "Init" 1 "HVIL_ist_OK" 2 "HVIL_Fehler" 3 "ohne_Funktion" ;
VAL_ 391 MO_KLE_FStatus 0 "kein_Fehler" 2 "Fehlerentprellung" 3 "Fehler" ;
VAL_ 391 MO_WH_Texte 0 "keine_Anzeige" 1 "ShiftLock__Fussbremse_betaetigen" 3 "Wegrollgefahr_bitte_P_einlegen" 4 "Parksperre_Warnstufe_I" 5 "Parksperre_Warnstufe_II" 6 "P_nur_im_Stillstand_moeglich" ;
VAL_ 391 MO_Tankbereitschaft_Status 0 "keine_Aktion_Init" 1 "Tankbereitschaft_wird_hergestellt" 2 "Tankbereitschaft_ist_hergestellt" 3 "Tankbereitschaft_kann_nicht_hergestellt_werden" 4 "Tanksystem_Systemfehler" 5 "Tankklappe_pruefen_schliessen" 6 "Tankvorgang_abgebrochen" ;
VAL_ 391 MO_Tankklappensteuerung 0 "Init_nicht_verbaut" 1 "Tankklappe_soll_entriegeln" 2 "Tankklappe_soll_verriegeln" 3 "keine_Aktion" ;
VAL_ 813 MO_Fuellstand_LPG 1022 "ungueltig" 1023 "Fehler" ;
VAL_ 813 MO_CNG_LPG 0 "CNG" 1 "LPG" ;
VAL_ 813 MO_CNG_Tankstopp 0 "kein_Tankstopp" 1 "Tankstopp_erkannt" ;
VAL_ 813 MO_LPG_Tankstopp 0 "kein_Tankstopp" 1 "Tankstopp_erkannt" ;
VAL_ 813 MO_AnzeigeGasbetrieb 0 "keine_Textmeldung" 1 "Umschaltung_Gasbetrieb" 2 "Gasbetrieb" 3 "Umschaltung_Benzinbetrieb" 4 "Benzinbetrieb" 5 "Umschaltung_nicht_moeglich" 6 "Gasbetrieb_nicht_moeglich" 7 "Benzintank_leer" 8 "GAP_CNG_Betrieb_verhindert" ;
VAL_ 813 MO_akt_Betrieb 0 "Benzinbetrieb" 1 "Gasbetrieb" ;
VAL_ 813 MO_Erdgasqualitaet 0 "Anzeige_in_MFA_Rolle_nicht_auswaehlbar" 1 "Qualitaet_xxx" 2 "Qualitaet_100" 3 "Qualitaet_90" 4 "Qualitaet_80" 5 "Qualitaet_70" 6 "Qualitaet_xxx" 7 "Qualitaet_xxx" ;
VAL_ 813 MO_Verbrauchsaequivalent 0 "Funktion_nicht_unterstuetzt" 254 "Init_Adaption_nach_Betankung" 255 "Fehler" ;
VAL_ 813 MO_Tankmasse_CNG 0 "Init" 255 "Fehler" ;
VAL_ 813 MO_Tankvolumen_LPG 0 "Init" 255 "Fehler" ;
VAL_ 813 MO_Fuellungsgrad_CNG 254 "Init" 255 "Fehler" ;
VAL_ 813 MO_Fuellungsgrad_LPG 254 "Init_ungueltig" 255 "Fehler" ;
VAL_ 813 MO_CNG_Ueberlauf 0 "kein_Ueberlauf" 1 "mind_1_Ueberlauf" ;
VAL_ 813 MO_LPG_Ueberlauf 0 "kein_Ueberlauf" 1 "mind_1_Ueberlauf" ;
VAL_ 1155 Mo_Powermeter_Grenze 4093 "OFF" ;
VAL_ 1155 MO_Powermeter_Inszenierung_aktiv 0 "keine_Anzeige" 1 "Inszenierung_aktiv" ;
VAL_ 1155 MO_Powermeter_Charge_Grenze 1022 "Init" 1023 "Fehler" ;
VAL_ 1155 MO_Powermeter_Grenze_strategisch 4094 "Init" 4095 "Fehler" ;
VAL_ 1155 MO_Powermeter_untere_E_Grenze 4094 "Init" 4095 "Fehler" ;
VAL_ 1155 MO_Powermeter_obere_E_Grenze 4094 "Init" 4095 "Fehler" ;
VAL_ 2589284112 MO_VTD_TD_L 0 "Init" 0 "Fehler" ;
VAL_ 2589284112 MO_VTD_CDEODT_L 0 "Init" 0 "Fehler" ;
VAL_ 2589284114 MO_VTD_CDFC_L 0 "Init" 0 "Fehler" ;
VAL_ 2589284114 MO_VTD_CDERDT_L 0 "Init" 0 "Fehler" ;
VAL_ 2589284116 MO_VTD_CIDT_L 0 "Init" 0 "Fehler" ;
VAL_ 2589284116 MO_VTD_GE_L 0 "Init" 0 "Fehler" ;
VAL_ 2589284118 MO_VTD_CIFC_L 0 "Init" 0 "Fehler" ;
VAL_ 2589284118 MO_VTD_FC_L 0 "Init" 0 "Fehler" ;
